VERSION "xyz"

NS_ :

BS_:

BU_: CabDisplay2 SafetyRestraintSystem AftertreatmentSystemGasOutlet AftertreatmentSystemGasIntake Turbocharger OnBoardDataLogger OffBoardDiagnosticTool2 OffBoardDiagnosticTool1 FileServer ParkingBrakeController SeatControl2 FanDriveController SteeringColumnUnit CommunicationUnitRadio CommunicationUnitSatellite CommunicationUnitCellular PropulsionBatteryCharger ChassisController2 ChassisController1 EngineValveControl AuxiliaryHeater2 AuxiliaryHeater1 ClutchUnit RampControl InformationSystem1 SuspensionSystemController2 OilSensor VehicleDynamicStability ExhaustEmissionController TransmissionDisplay2 TransmissionDisplay1 ClimateControl2 WaterPumpController RearAxleSteeringController LightingOperatorControl SeatController1 IgnitionController2 IgnitionController1 TirePressureController CabController2 CabController1 PneumaticSystemController SuspensionSystemController1 HydraulicPumpController EnduranceBrakingSystem RetarderExhaustEngine2 OnBoardDiagnosticUnit HeadwayController RetarderExhaustEngine1 CabDisplay1 ManagementComputer VirtualTerminal OffVehicleGateway PowerTakeOffFront HitchControl AuxiliaryValveControl BodyController TractorTrailerBridge1 StarterSystem ElectricalSystem VehicleSecurity VehicleNavigation AerodynamicControl ElectricalChargingSystem ClimateControl1 TripRecorder InstrumentCluster SuspensionDriveAxle2 SuspensionDriveAxle1 SuspensionSteerAxle SteeringController FuelSystem CruiseControl RetarderDriveline RetarderEngine BrakesDriveAxle2 BrakesDriveAxle1 BrakesSystemController BrakesSteerAxle AxleDrive2 AxleDrive1 AxleSteering PowerTakeOff ShiftConsoleSecondary ShiftConsolePrimary Transmission2 Transmission1 Engine2 Engine1

BO_ 2566781694 GTACE: 8 Vector__XXX
 SG_ GeneratorTotalKWHoursImport : 32|32@1+ (1,0) [0|4211081215] "kWh" Vector__XXX
 SG_ GeneratorTotalKWHoursExport : 0|32@1+ (1,0) [0|4211081215] "kWh" Vector__XXX

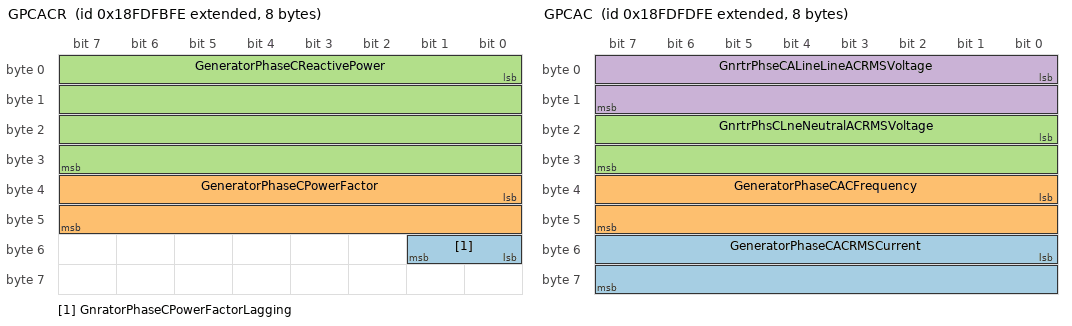
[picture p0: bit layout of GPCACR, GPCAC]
BO_ 2566781950 GPCACR: 8 Vector__XXX
 SG_ GnratorPhaseCPowerFactorLagging : 48|2@1+ (1,0) [0|3] "" Vector__XXX
 SG_ GeneratorPhaseCPowerFactor : 32|16@1+ (1,-1) [-1|2.92181] "" Vector__XXX
 SG_ GeneratorPhaseCReactivePower : 0|32@1+ (1,-2000000000) [-2000000000|2211081215] "VA" Vector__XXX

BO_ 2566782206 GPCACP: 8 Vector__XXX
 SG_ GeneratorPhaseCApparentPower : 32|32@1+ (1,-2000000000) [-2000000000|2211081215] "VA" Vector__XXX
 SG_ GeneratorPhaseCRealPower : 0|32@1+ (1,-2000000000) [-2000000000|2211081215] "VA" Vector__XXX

BO_ 2566782462 GPCAC: 8 Vector__XXX
 SG_ GeneratorPhaseCACRMSCurrent : 48|16@1+ (1,0) [0|64255] "A" Vector__XXX
 SG_ GeneratorPhaseCACFrequency : 32|16@1+ (1,0) [0|501.9921875] "Hz" Vector__XXX
 SG_ GnrtrPhsCLneNeutralACRMSVoltage : 16|16@1+ (1,0) [0|64255] "V" Vector__XXX
 SG_ GnrtrPhseCALineLineACRMSVoltage : 0|16@1+ (1,0) [0|64255] "V" Vector__XXX

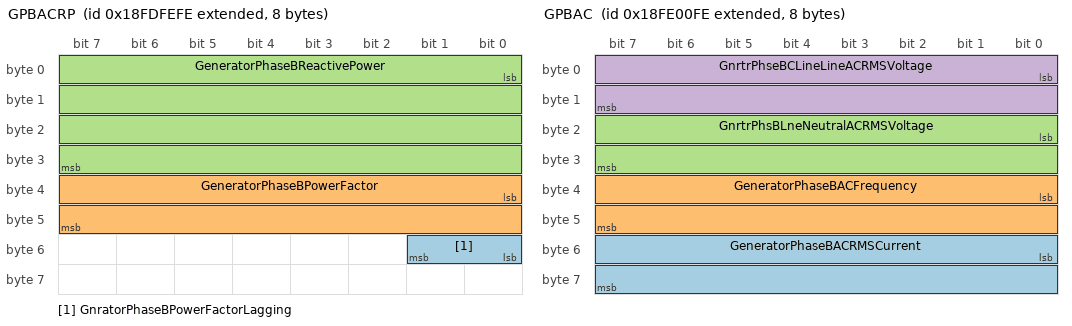
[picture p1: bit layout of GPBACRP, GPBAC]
BO_ 2566782718 GPBACRP: 8 Vector__XXX
 SG_ GnratorPhaseBPowerFactorLagging : 48|2@1+ (1,0) [0|3] "" Vector__XXX
 SG_ GeneratorPhaseBPowerFactor : 32|16@1+ (1,-1) [-1|2.92181] "" Vector__XXX
 SG_ GeneratorPhaseBReactivePower : 0|32@1+ (1,-2000000000) [-2000000000|2211081215] "VA" Vector__XXX

BO_ 2566782974 GPBACP: 8 Vector__XXX
 SG_ GeneratorPhaseBApparentPower : 32|32@1+ (1,-2000000000) [-2000000000|2211081215] "VA" Vector__XXX
 SG_ GeneratorPhaseBRealPower : 0|32@1+ (1,-2000000000) [-2000000000|2211081215] "VA" Vector__XXX

BO_ 2566783230 GPBAC: 8 Vector__XXX
 SG_ GeneratorPhaseBACRMSCurrent : 48|16@1+ (1,0) [0|64255] "A" Vector__XXX
 SG_ GeneratorPhaseBACFrequency : 32|16@1+ (1,0) [0|501.9921875] "Hz" Vector__XXX
 SG_ GnrtrPhsBLneNeutralACRMSVoltage : 16|16@1+ (1,0) [0|64255] "V" Vector__XXX
 SG_ GnrtrPhseBCLineLineACRMSVoltage : 0|16@1+ (1,0) [0|64255] "V" Vector__XXX

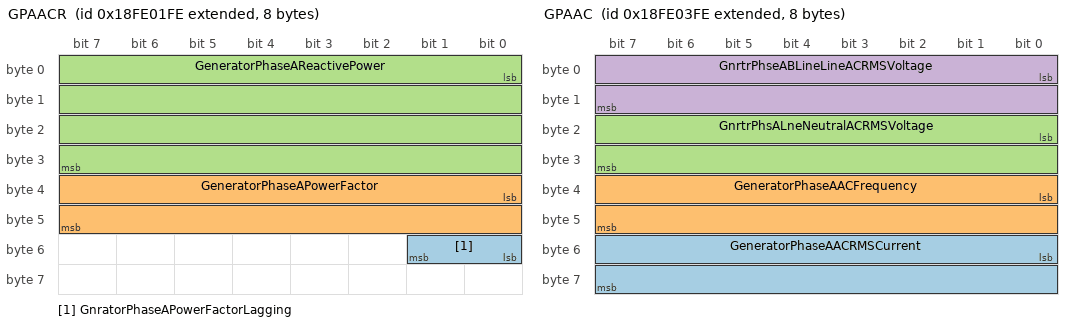
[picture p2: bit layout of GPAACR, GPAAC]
BO_ 2566783486 GPAACR: 8 Vector__XXX
 SG_ GnratorPhaseAPowerFactorLagging : 48|2@1+ (1,0) [0|3] "" Vector__XXX
 SG_ GeneratorPhaseAPowerFactor : 32|16@1+ (1,-1) [-1|2.92181] "" Vector__XXX
 SG_ GeneratorPhaseAReactivePower : 0|32@1+ (1,-2000000000) [-2000000000|2211081215] "VA" Vector__XXX

BO_ 2566783742 GPAACP: 8 Vector__XXX
 SG_ GeneratorPhaseAApparentPower : 32|32@1+ (1,-2000000000) [-2000000000|2211081215] "VA" Vector__XXX
 SG_ GeneratorPhaseARealPower : 0|32@1+ (1,-2000000000) [-2000000000|2211081215] "VA" Vector__XXX

BO_ 2566783998 GPAAC: 8 Vector__XXX
 SG_ GeneratorPhaseAACRMSCurrent : 48|16@1+ (1,0) [0|64255] "A" Vector__XXX
 SG_ GeneratorPhaseAACFrequency : 32|16@1+ (1,0) [0|501.9921875] "Hz" Vector__XXX
 SG_ GnrtrPhsALneNeutralACRMSVoltage : 16|16@1+ (1,0) [0|64255] "V" Vector__XXX
 SG_ GnrtrPhseABLineLineACRMSVoltage : 0|16@1+ (1,0) [0|64255] "V" Vector__XXX

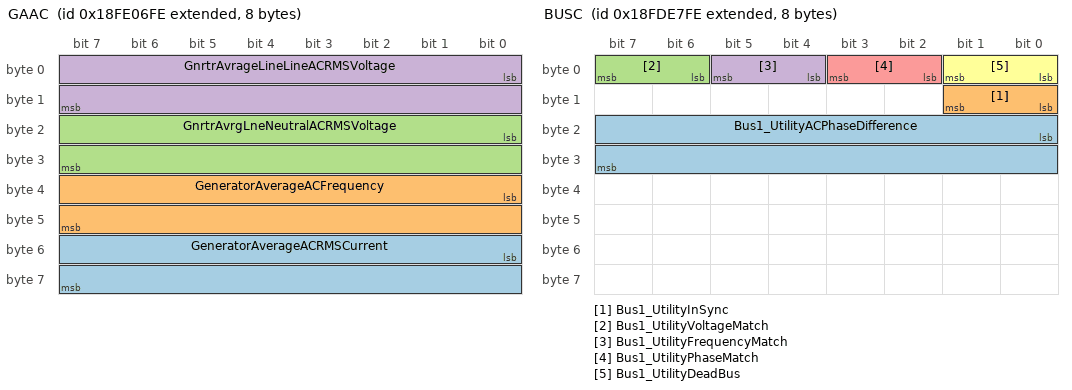
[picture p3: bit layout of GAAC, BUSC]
BO_ 2566784766 GAAC: 8 Vector__XXX
 SG_ GeneratorAverageACRMSCurrent : 48|16@1+ (1,0) [0|64255] "A" Vector__XXX
 SG_ GeneratorAverageACFrequency : 32|16@1+ (1,0) [0|501.9921875] "Hz" Vector__XXX
 SG_ GnrtrAvrgLneNeutralACRMSVoltage : 16|16@1+ (1,0) [0|64255] "V" Vector__XXX
 SG_ GnrtrAvrageLineLineACRMSVoltage : 0|16@1+ (1,0) [0|64255] "V" Vector__XXX

BO_ 2566776830 BUSC: 8 Vector__XXX
 SG_ Bus1_UtilityACPhaseDifference : 16|16@1+ (1,-200) [-200|301.99] "deg" Vector__XXX
 SG_ Bus1_UtilityInSync : 8|2@1+ (1,0) [0|3] "" Vector__XXX
 SG_ Bus1_UtilityVoltageMatch : 6|2@1+ (1,0) [0|3] "" Vector__XXX
 SG_ Bus1_UtilityFrequencyMatch : 4|2@1+ (1,0) [0|3] "" Vector__XXX
 SG_ Bus1_UtilityPhaseMatch : 2|2@1+ (1,0) [0|3] "" Vector__XXX
 SG_ Bus1_UtilityDeadBus : 0|2@1+ (1,0) [0|3] "" Vector__XXX

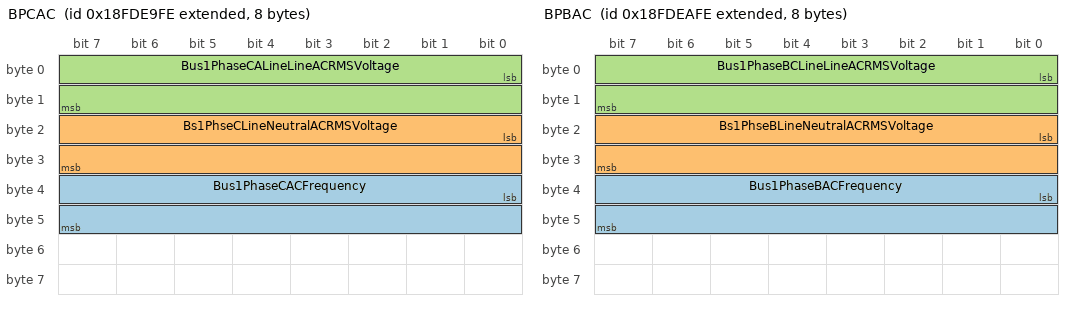
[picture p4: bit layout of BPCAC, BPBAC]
BO_ 2566777342 BPCAC: 8 Vector__XXX
 SG_ Bus1PhaseCACFrequency : 32|16@1+ (1,0) [0|501.9921875] "Hz" Vector__XXX
 SG_ Bs1PhseCLineNeutralACRMSVoltage : 16|16@1+ (1,0) [0|64255] "V" Vector__XXX
 SG_ Bus1PhaseCALineLineACRMSVoltage : 0|16@1+ (1,0) [0|64255] "V" Vector__XXX

BO_ 2566777598 BPBAC: 8 Vector__XXX
 SG_ Bus1PhaseBACFrequency : 32|16@1+ (1,0) [0|501.9921875] "Hz" Vector__XXX
 SG_ Bs1PhseBLineNeutralACRMSVoltage : 16|16@1+ (1,0) [0|64255] "V" Vector__XXX
 SG_ Bus1PhaseBCLineLineACRMSVoltage : 0|16@1+ (1,0) [0|64255] "V" Vector__XXX

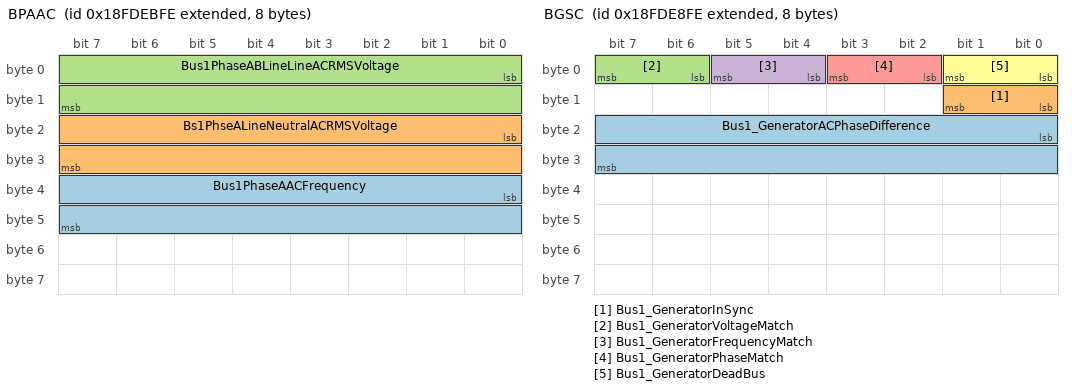
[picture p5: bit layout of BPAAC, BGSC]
BO_ 2566777854 BPAAC: 8 Vector__XXX
 SG_ Bus1PhaseAACFrequency : 32|16@1+ (1,0) [0|501.9921875] "Hz" Vector__XXX
 SG_ Bs1PhseALineNeutralACRMSVoltage : 16|16@1+ (1,0) [0|64255] "V" Vector__XXX
 SG_ Bus1PhaseABLineLineACRMSVoltage : 0|16@1+ (1,0) [0|64255] "V" Vector__XXX

BO_ 2566777086 BGSC: 8 Vector__XXX
 SG_ Bus1_GeneratorACPhaseDifference : 16|16@1+ (1,-200) [-200|301.99] "deg" Vector__XXX
 SG_ Bus1_GeneratorInSync : 8|2@1+ (1,0) [0|3] "" Vector__XXX
 SG_ Bus1_GeneratorVoltageMatch : 6|2@1+ (1,0) [0|3] "" Vector__XXX
 SG_ Bus1_GeneratorFrequencyMatch : 4|2@1+ (1,0) [0|3] "" Vector__XXX
 SG_ Bus1_GeneratorPhaseMatch : 2|2@1+ (1,0) [0|3] "" Vector__XXX
 SG_ Bus1_GeneratorDeadBus : 0|2@1+ (1,0) [0|3] "" Vector__XXX

BO_ 2566778110 BAAC: 8 Vector__XXX
 SG_ Bus1AverageACFrequency : 32|16@1+ (1,0) [0|501.9921875] "Hz" Vector__XXX
 SG_ Bs1AvrgeLineNeutralACRMSVoltage : 16|16@1+ (1,0) [0|64255] "V" Vector__XXX
 SG_ Bus1AverageLineLineACRMSVoltage : 0|16@1+ (1,0) [0|64255] "V" Vector__XXX

BO_ 2633895422 WSMSTR: 8 Vector__XXX
 SG_ NumberOfMembers : 0|8@1+ (1,0) [0|0] "" Vector__XXX

BO_ 2566838526 CA: 9 Vector__XXX
 SG_ ArbitraryAddressCapable : 63|1@1+ (1,0) [0|1] "" Vector__XXX
 SG_ IndustryGroup : 60|3@1+ (1,0) [0|7] "" Vector__XXX
 SG_ VehicleSystemInstance : 56|4@1+ (1,0) [0|15] "" Vector__XXX
 SG_ VehicleSystem : 49|7@1+ (1,0) [0|127] "" Vector__XXX
 SG_ Function : 40|8@1+ (1,0) [0|255] "" Vector__XXX
 SG_ FunctionInstance : 35|5@1+ (1,0) [0|31] "" Vector__XXX
 SG_ ECUInstance : 32|3@1+ (1,0) [0|7] "" Vector__XXX
 SG_ ManufacturerCode : 21|11@1+ (1,0) [0|2047] "" Vector__XXX
 SG_ IdentityNumber : 0|21@1+ (1,0) [0|2097152] "" Vector__XXX
 SG_ AddressAssignment : 64|8@1+ (1,0) [0|255] "" Vector__XXX

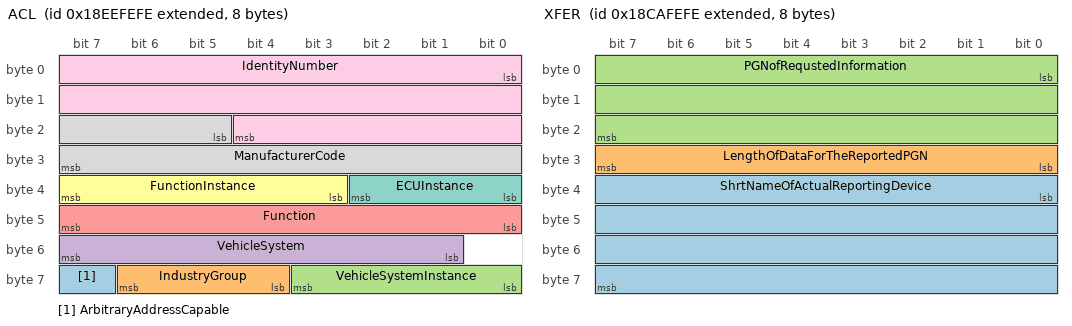
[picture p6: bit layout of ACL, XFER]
BO_ 2565799678 ACL: 8 Vector__XXX
 SG_ ArbitraryAddressCapable : 63|1@1+ (1,0) [0|1] "" Vector__XXX
 SG_ IndustryGroup : 60|3@1+ (1,0) [0|7] "" Vector__XXX
 SG_ VehicleSystemInstance : 56|4@1+ (1,0) [0|15] "" Vector__XXX
 SG_ VehicleSystem : 49|7@1+ (1,0) [0|127] "" Vector__XXX
 SG_ Function : 40|8@1+ (1,0) [0|255] "" Vector__XXX
 SG_ FunctionInstance : 35|5@1+ (1,0) [0|31] "" Vector__XXX
 SG_ ECUInstance : 32|3@1+ (1,0) [0|7] "" Vector__XXX
 SG_ ManufacturerCode : 21|11@1+ (1,0) [0|2047] "" Vector__XXX
 SG_ IdentityNumber : 0|21@1+ (1,0) [0|2097152] "" Vector__XXX

BO_ 2563440382 XFER: 8 Vector__XXX
 SG_ ShrtNameOfActualReportingDevice : 32|32@1+ (1,0) [0|0] "(2^32 - 1)" Vector__XXX
 SG_ LengthOfDataForTheReportedPGN : 24|8@1+ (1,0) [0|255] "" Vector__XXX
 SG_ PGNofRequstedInformation : 0|24@1+ (1,0) [0|16777215] "" Vector__XXX

BO_ 2565603070 TPDT: 8 Vector__XXX
 SG_ SequenceNumber : 0|8@1+ (1,0) [0|252] "" Vector__XXX

BO_ 2565668606 TPCM: 8 Vector__XXX
 SG_ TotalNumberOfPacketsEoMA m19 : 24|8@1+ (1,0) [0|255] "" Vector__XXX
 SG_ TotalMessageSizeEoMA m19 : 8|16@1+ (1,0) [0|64255] "counts" Vector__XXX
 SG_ TotalMessageSizeBAM m32 : 8|16@1+ (1,0) [0|64255] "counts" Vector__XXX
 SG_ TotalNumberOfPacketsBAM m32 : 24|8@1+ (1,0) [0|255] "" Vector__XXX
 SG_ ConnectionAbortReason m255 : 8|8@1+ (1,0) [0|255] "" Vector__XXX
 SG_ NextPacketNumberToBeSent m17 : 16|8@1+ (1,0) [0|255] "" Vector__XXX
 SG_ NumberOfPacketsThatCanBeSent m17 : 8|8@1+ (1,0) [0|255] "" Vector__XXX
 SG_ PGNumber : 40|24@1+ (1,0) [0|16777200] "" Vector__XXX
 SG_ MaximumNumberOfPackets m16 : 32|8@1+ (1,0) [0|255] "" Vector__XXX
 SG_ TotalNumberOfPackets m16 : 24|8@1+ (1,0) [0|255] "" Vector__XXX
 SG_ TotalMessageSize m16 : 8|16@1+ (1,0) [0|64255] "counts" Vector__XXX
 SG_ ControlByte M : 0|8@1+ (1,0) [0|255] "" Vector__XXX

BO_ 2563374846 RQST2: 8 Vector__XXX
 SG_ UseTransferMode : 24|2@1+ (1,0) [0|3] "" Vector__XXX
 SG_ ParameterGroupNumber : 0|24@1+ (1,0) [0|16777215] "" Vector__XXX

BO_ 2565537534 RQST: 3 Vector__XXX
 SG_ ParameterGroupNumber : 0|24@1+ (1,0) [0|16777215] "" Vector__XXX

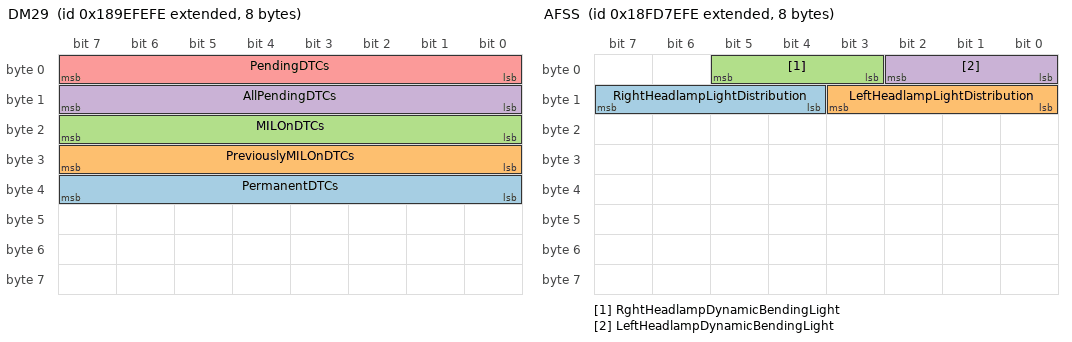
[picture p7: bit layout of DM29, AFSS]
BO_ 2560556798 DM29: 8 Vector__XXX
 SG_ PermanentDTCs : 32|8@1+ (1,0) [0|255] "" Vector__XXX
 SG_ PreviouslyMILOnDTCs : 24|8@1+ (1,0) [0|255] "" Vector__XXX
 SG_ MILOnDTCs : 16|8@1+ (1,0) [0|255] "" Vector__XXX
 SG_ AllPendingDTCs : 8|8@1+ (1,0) [0|255] "" Vector__XXX
 SG_ PendingDTCs : 0|8@1+ (1,0) [0|255] "" Vector__XXX

BO_ 2566750462 DM28: 22 Vector__XXX
 SG_ SPN5 : 144|16@1+ (1,0) [0|65536] "" Vector__XXX
 SG_ SPN4 : 112|16@1+ (1,0) [0|65536] "" Vector__XXX
 SG_ SPN3 : 80|16@1+ (1,0) [0|65536] "" Vector__XXX
 SG_ SPN2 : 48|16@1+ (1,0) [0|65536] "" Vector__XXX
 SG_ FailureModeIdentifier5 : 160|5@1+ (1,0) [0|0] "" Vector__XXX
 SG_ FailureModeIdentifier4 : 128|5@1+ (1,0) [0|0] "" Vector__XXX
 SG_ FailureModeIdentifier3 : 96|5@1+ (1,0) [0|0] "" Vector__XXX
 SG_ FlashRedStopLamp : 12|2@1+ (1,0) [0|3] "" Vector__XXX
 SG_ FlashProtectLamp : 8|2@1+ (1,0) [0|3] "" Vector__XXX
 SG_ FlashMalfuncIndicatorLamp : 14|2@1+ (1,0) [0|3] "" Vector__XXX
 SG_ FlashAmberWarningLamp : 10|2@1+ (1,0) [0|3] "" Vector__XXX
 SG_ MalfunctionIndicatorLampStatus : 6|2@1+ (1,0) [0|3] "" Vector__XXX
 SG_ AmberWarningLampStatus : 2|2@1+ (1,0) [0|3] "" Vector__XXX
 SG_ OccurenceCount1 : 40|7@1+ (1,0) [0|126] "" Vector__XXX
 SG_ SPNConversionMethod1 : 47|1@1+ (1,0) [0|1] "" Vector__XXX
 SG_ FailureModeIdentifier1 : 32|5@1+ (1,0) [0|0] "" Vector__XXX
 SG_ SPN1 : 16|16@1+ (1,0) [0|65536] "" Vector__XXX
 SG_ RedStopLampState : 4|2@1+ (1,0) [0|3] "" Vector__XXX
 SG_ ProtectLampStatus : 0|2@1+ (1,0) [0|3] "" Vector__XXX
 SG_ FailureModeIdentifier2 : 64|5@1+ (1,0) [0|0] "" Vector__XXX
 SG_ SPNConversionMethod5 : 175|1@1+ (1,0) [0|1] "" Vector__XXX
 SG_ SPNConversionMethod4 : 143|1@1+ (1,0) [0|1] "" Vector__XXX
 SG_ SPNConversionMethod3 : 111|1@1+ (1,0) [0|1] "" Vector__XXX
 SG_ SPNConversionMethod2 : 79|1@1+ (1,0) [0|1] "" Vector__XXX
 SG_ OccurenceCount5 : 168|7@1+ (1,0) [0|126] "" Vector__XXX
 SG_ OccurenceCount4 : 136|7@1+ (1,0) [0|126] "" Vector__XXX
 SG_ OccurenceCount3 : 104|7@1+ (1,0) [0|126] "" Vector__XXX
 SG_ OccurenceCount2 : 72|7@1+ (1,0) [0|126] "" Vector__XXX
 SG_ SPN5High : 165|3@1+ (1,0) [0|7] "" Vector__XXX
 SG_ SPN4High : 133|3@1+ (1,0) [0|7] "" Vector__XXX
 SG_ SPN3High : 101|3@1+ (1,0) [0|7] "" Vector__XXX
 SG_ SPN2High : 69|3@1+ (1,0) [0|7] "" Vector__XXX
 SG_ SPN1High : 37|3@1+ (1,0) [0|7] "" Vector__XXX

BO_ 2566750974 DM27: 22 Vector__XXX
 SG_ SPN5 : 144|16@1+ (1,0) [0|65536] "" Vector__XXX
 SG_ SPN4 : 112|16@1+ (1,0) [0|65536] "" Vector__XXX
 SG_ SPN3 : 80|16@1+ (1,0) [0|65536] "" Vector__XXX
 SG_ SPN2 : 48|16@1+ (1,0) [0|65536] "" Vector__XXX
 SG_ FailureModeIdentifier5 : 160|5@1+ (1,0) [0|0] "" Vector__XXX
 SG_ FailureModeIdentifier4 : 128|5@1+ (1,0) [0|0] "" Vector__XXX
 SG_ FailureModeIdentifier3 : 96|5@1+ (1,0) [0|0] "" Vector__XXX
 SG_ FlashRedStopLamp : 12|2@1+ (1,0) [0|3] "" Vector__XXX
 SG_ FlashProtectLamp : 8|2@1+ (1,0) [0|3] "" Vector__XXX
 SG_ FlashMalfuncIndicatorLamp : 14|2@1+ (1,0) [0|3] "" Vector__XXX
 SG_ FlashAmberWarningLamp : 10|2@1+ (1,0) [0|3] "" Vector__XXX
 SG_ MalfunctionIndicatorLampStatus : 6|2@1+ (1,0) [0|3] "" Vector__XXX
 SG_ AmberWarningLampStatus : 2|2@1+ (1,0) [0|3] "" Vector__XXX
 SG_ OccurenceCount1 : 40|7@1+ (1,0) [0|126] "" Vector__XXX
 SG_ SPNConversionMethod1 : 47|1@1+ (1,0) [0|1] "" Vector__XXX
 SG_ FailureModeIdentifier1 : 32|5@1+ (1,0) [0|0] "" Vector__XXX
 SG_ SPN1 : 16|16@1+ (1,0) [0|65536] "" Vector__XXX
 SG_ RedStopLampState : 4|2@1+ (1,0) [0|3] "" Vector__XXX
 SG_ ProtectLampStatus : 0|2@1+ (1,0) [0|3] "" Vector__XXX
 SG_ FailureModeIdentifier2 : 64|5@1+ (1,0) [0|0] "" Vector__XXX
 SG_ SPNConversionMethod5 : 175|1@1+ (1,0) [0|1] "" Vector__XXX
 SG_ SPNConversionMethod4 : 143|1@1+ (1,0) [0|1] "" Vector__XXX
 SG_ SPNConversionMethod3 : 111|1@1+ (1,0) [0|1] "" Vector__XXX
 SG_ SPNConversionMethod2 : 79|1@1+ (1,0) [0|1] "" Vector__XXX
 SG_ OccurenceCount5 : 168|7@1+ (1,0) [0|126] "" Vector__XXX
 SG_ OccurenceCount4 : 136|7@1+ (1,0) [0|126] "" Vector__XXX
 SG_ OccurenceCount3 : 104|7@1+ (1,0) [0|126] "" Vector__XXX
 SG_ OccurenceCount2 : 72|7@1+ (1,0) [0|126] "" Vector__XXX
 SG_ SPN5High : 165|3@1+ (1,0) [0|7] "" Vector__XXX
 SG_ SPN4High : 133|3@1+ (1,0) [0|7] "" Vector__XXX
 SG_ SPN3High : 101|3@1+ (1,0) [0|7] "" Vector__XXX
 SG_ SPN2High : 69|3@1+ (1,0) [0|7] "" Vector__XXX
 SG_ SPN1High : 37|3@1+ (1,0) [0|7] "" Vector__XXX

BO_ 2566748414 ATI2: 32 Vector__XXX
 SG_ Aftrtrtmnt2TrpPssvRgnrationTime : 128|32@1+ (1,0) [0|4211081215] "s" Vector__XXX
 SG_ Aftrtrtmnt2TrpNmbrOfPssvRgnrtns : 160|32@1+ (1,0) [0|4294967295] "counts" Vector__XXX
 SG_ Aftrtrtmnt2TrpNmbrOfActvRgnrtns : 96|32@1+ (1,0) [0|4294967295] "counts" Vector__XXX
 SG_ Aftrtrtmnt2TrpNmbrOfActvRgnrtnMn : 224|32@1+ (1,0) [0|4294967295] "counts" Vector__XXX
 SG_ Aftrtrtmnt2TrpNmbrOfActvRgnrtnIn : 192|32@1+ (1,0) [0|4294967295] "counts" Vector__XXX
 SG_ Aftrtrtmnt2TrpActvRgnrationTime : 32|32@1+ (1,0) [0|4211081215] "s" Vector__XXX
 SG_ Aftertreatment2TripFuelUsed : 0|32@1+ (0.5,0) [0|2105540607.5] "L" Vector__XXX
 SG_ Aftertreatment2TripDisabledTime : 64|32@1+ (1,0) [0|4211081215] "s" Vector__XXX

BO_ 2566748670 ATI1: 32 Vector__XXX
 SG_ Aftrtrtmnt1TrpPssvRgnrationTime : 128|32@1+ (1,0) [0|4211081215] "s" Vector__XXX
 SG_ Aftrtrtmnt1TrpNmbrOfPssvRgnrtns : 160|32@1+ (1,0) [0|4294967295] "counts" Vector__XXX
 SG_ Aftrtrtmnt1TrpNmbrOfActvRgnrtns : 96|32@1+ (1,0) [0|4294967295] "counts" Vector__XXX
 SG_ Aftrtrtmnt1TrpNmbrOfActvRgnrtnMn : 224|32@1+ (1,0) [0|4294967295] "counts" Vector__XXX
 SG_ Aftrtrtmnt1TrpNmbrOfActvRgnrtnIn : 192|32@1+ (1,0) [0|4294967295] "counts" Vector__XXX
 SG_ Aftrtrtmnt1TrpActvRgnrationTime : 32|32@1+ (1,0) [0|4211081215] "s" Vector__XXX
 SG_ Aftertreatment1TripFuelUsed : 0|32@1+ (0.5,0) [0|2105540607.5] "L" Vector__XXX
 SG_ Aftertreatment1TripDisabledTime : 64|32@1+ (1,0) [0|4211081215] "s" Vector__XXX

BO_ 2566745598 AAC3: 8 Vector__XXX
 SG_ Aftertreatment1SecondAirPress : 48|16@1+ (0.1,0) [0|6425.5] "kPa" Vector__XXX
 SG_ Aftrtreatment1SecondAirMassFlow : 32|16@1+ (0.2,0) [0|12851] "kg/h" Vector__XXX
 SG_ Aftertreatment1SecondAirTemp : 16|16@1+ (0.03125,-273) [-273|1735] "deg" Vector__XXX
 SG_ Aftrtratment1SecondAirDiffPress : 0|16@1+ (0.0078125,-250) [-250|251.99] "kPa" Vector__XXX

BO_ 2566745342 AAC4: 8 Vector__XXX
 SG_ Aftertreatment2SecondAirPress : 48|16@1+ (0.1,0) [0|6425.5] "kPa" Vector__XXX
 SG_ Aftrtreatment2SecondAirMassFlow : 32|16@1+ (0.2,0) [0|12851] "kg/h" Vector__XXX
 SG_ Aftertreatment2SecondAirTemp : 16|16@1+ (0.03125,-273) [-273|1735] "deg" Vector__XXX
 SG_ Aftrtratment2SecondAirDiffPress : 0|16@1+ (0.0078125,-250) [-250|251.99] "kPa" Vector__XXX

BO_ 2566754558 AETC: 8 Vector__XXX
 SG_ NumberOfAETCDataPoints : 4|4@1+ (1,0) [0|15] "" Vector__XXX
 SG_ AETCDataCollectionStandard : 0|4@1+ (1,0) [0|15] "" Vector__XXX

BO_ 2566749950 AFSS: 8 Vector__XXX
 SG_ RightHeadlampLightDistribution : 12|4@1+ (1,0) [0|15] "" Vector__XXX
 SG_ LeftHeadlampLightDistribution : 8|4@1+ (1,0) [0|15] "" Vector__XXX
 SG_ RghtHeadlampDynamicBendingLight : 3|3@1+ (1,0) [0|7] "" Vector__XXX
 SG_ LeftHeadlampDynamicBendingLight : 0|3@1+ (1,0) [0|7] "" Vector__XXX

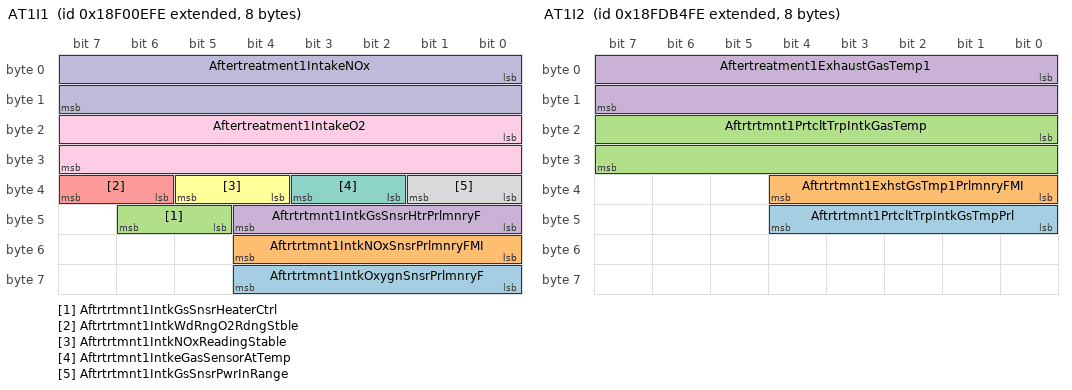
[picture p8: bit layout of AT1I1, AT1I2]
BO_ 2565869310 AT1I1: 8 Vector__XXX
 SG_ Aftrtrtmnt1IntkOxygnSnsrPrlmnryF : 56|5@1+ (1,0) [0|31] "" Vector__XXX
 SG_ Aftrtrtmnt1IntkNOxSnsrPrlmnryFMI : 48|5@1+ (1,0) [0|31] "" Vector__XXX
 SG_ Aftrtrtmnt1IntkGsSnsrHeaterCtrl : 45|2@1+ (1,0) [0|3] "" Vector__XXX
 SG_ Aftrtrtmnt1IntkGsSnsrHtrPrlmnryF : 40|5@1+ (1,0) [0|31] "" Vector__XXX
 SG_ Aftrtrtmnt1IntkWdRngO2RdngStble : 38|2@1+ (1,0) [0|3] "" Vector__XXX
 SG_ Aftrtrtmnt1IntkNOxReadingStable : 36|2@1+ (1,0) [0|3] "" Vector__XXX
 SG_ Aftrtrtmnt1IntkeGasSensorAtTemp : 34|2@1+ (1,0) [0|3] "" Vector__XXX
 SG_ Aftrtrtmnt1IntkGsSnsrPwrInRange : 32|2@1+ (1,0) [0|3] "" Vector__XXX
 SG_ Aftertreatment1IntakeO2 : 16|16@1+ (0.000514,-12) [-12|21] "%" Vector__XXX
 SG_ Aftertreatment1IntakeNOx : 0|16@1+ (0.05,-200) [-200|3012.75] "ppm" Vector__XXX

BO_ 2566763774 AT1I2: 8 Vector__XXX
 SG_ Aftrtrtmnt1PrtcltTrpIntkGsTmpPrl : 40|5@1+ (1,0) [0|31] "" Vector__XXX
 SG_ Aftrtrtmnt1ExhstGsTmp1PrlmnryFMI : 32|5@1+ (1,0) [0|31] "" Vector__XXX
 SG_ Aftrtrtmnt1PrtcltTrpIntkGasTemp : 16|16@1+ (0.03125,-273) [-273|1735] "deg" Vector__XXX
 SG_ Aftertreatment1ExhaustGasTemp1 : 0|16@1+ (0.03125,-273) [-273|1735] "deg" Vector__XXX

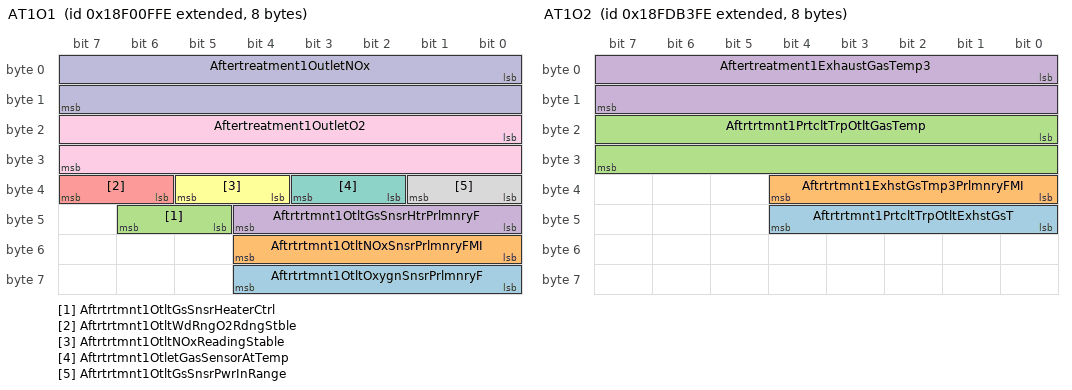
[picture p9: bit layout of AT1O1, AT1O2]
BO_ 2565869566 AT1O1: 8 Vector__XXX
 SG_ Aftrtrtmnt1OtltOxygnSnsrPrlmnryF : 56|5@1+ (1,0) [0|31] "" Vector__XXX
 SG_ Aftrtrtmnt1OtltNOxSnsrPrlmnryFMI : 48|5@1+ (1,0) [0|31] "" Vector__XXX
 SG_ Aftrtrtmnt1OtltGsSnsrHeaterCtrl : 45|2@1+ (1,0) [0|3] "" Vector__XXX
 SG_ Aftrtrtmnt1OtltGsSnsrHtrPrlmnryF : 40|5@1+ (1,0) [0|31] "" Vector__XXX
 SG_ Aftrtrtmnt1OtltWdRngO2RdngStble : 38|2@1+ (1,0) [0|3] "" Vector__XXX
 SG_ Aftrtrtmnt1OtltNOxReadingStable : 36|2@1+ (1,0) [0|3] "" Vector__XXX
 SG_ Aftrtrtmnt1OtletGasSensorAtTemp : 34|2@1+ (1,0) [0|3] "" Vector__XXX
 SG_ Aftrtrtmnt1OtltGsSnsrPwrInRange : 32|2@1+ (1,0) [0|3] "" Vector__XXX
 SG_ Aftertreatment1OutletO2 : 16|16@1+ (0.000514,-12) [-12|21] "%" Vector__XXX
 SG_ Aftertreatment1OutletNOx : 0|16@1+ (0.05,-200) [-200|3012.75] "ppm" Vector__XXX

BO_ 2566763518 AT1O2: 8 Vector__XXX
 SG_ Aftrtrtmnt1PrtcltTrpOtltExhstGsT : 40|5@1+ (1,0) [0|31] "" Vector__XXX
 SG_ Aftrtrtmnt1ExhstGsTmp3PrlmnryFMI : 32|5@1+ (1,0) [0|31] "" Vector__XXX
 SG_ Aftrtrtmnt1PrtcltTrpOtltGasTemp : 16|16@1+ (0.03125,-273) [-273|1735] "deg" Vector__XXX
 SG_ Aftertreatment1ExhaustGasTemp3 : 0|16@1+ (0.03125,-273) [-273|1735] "deg" Vector__XXX

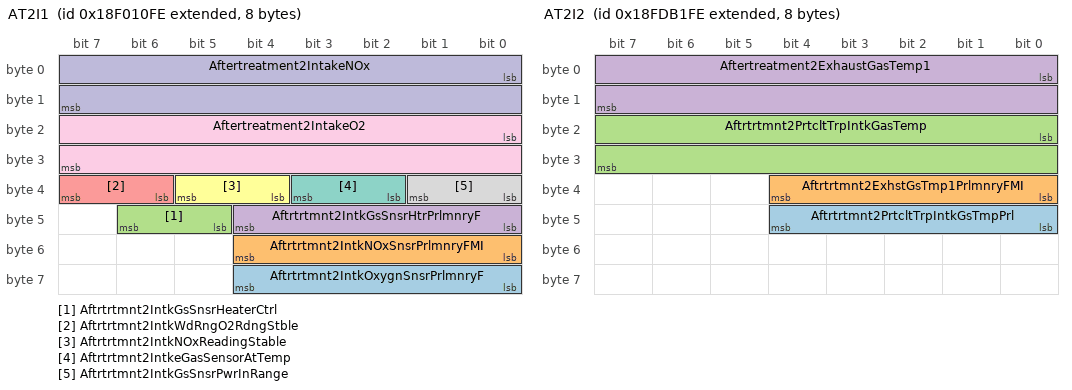
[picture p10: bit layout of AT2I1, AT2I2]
BO_ 2565869822 AT2I1: 8 Vector__XXX
 SG_ Aftrtrtmnt2IntkOxygnSnsrPrlmnryF : 56|5@1+ (1,0) [0|31] "" Vector__XXX
 SG_ Aftrtrtmnt2IntkNOxSnsrPrlmnryFMI : 48|5@1+ (1,0) [0|31] "" Vector__XXX
 SG_ Aftrtrtmnt2IntkGsSnsrHeaterCtrl : 45|2@1+ (1,0) [0|3] "" Vector__XXX
 SG_ Aftrtrtmnt2IntkGsSnsrHtrPrlmnryF : 40|5@1+ (1,0) [0|31] "" Vector__XXX
 SG_ Aftrtrtmnt2IntkWdRngO2RdngStble : 38|2@1+ (1,0) [0|3] "" Vector__XXX
 SG_ Aftrtrtmnt2IntkNOxReadingStable : 36|2@1+ (1,0) [0|3] "" Vector__XXX
 SG_ Aftrtrtmnt2IntkeGasSensorAtTemp : 34|2@1+ (1,0) [0|3] "" Vector__XXX
 SG_ Aftrtrtmnt2IntkGsSnsrPwrInRange : 32|2@1+ (1,0) [0|3] "" Vector__XXX
 SG_ Aftertreatment2IntakeO2 : 16|16@1+ (0.000514,-12) [-12|21] "%" Vector__XXX
 SG_ Aftertreatment2IntakeNOx : 0|16@1+ (0.05,-200) [-200|3012.75] "ppm" Vector__XXX

BO_ 2566763006 AT2I2: 8 Vector__XXX
 SG_ Aftrtrtmnt2PrtcltTrpIntkGsTmpPrl : 40|5@1+ (1,0) [0|31] "" Vector__XXX
 SG_ Aftrtrtmnt2ExhstGsTmp1PrlmnryFMI : 32|5@1+ (1,0) [0|31] "" Vector__XXX
 SG_ Aftrtrtmnt2PrtcltTrpIntkGasTemp : 16|16@1+ (0.03125,-273) [-273|1735] "deg" Vector__XXX
 SG_ Aftertreatment2ExhaustGasTemp1 : 0|16@1+ (0.03125,-273) [-273|1735] "deg" Vector__XXX

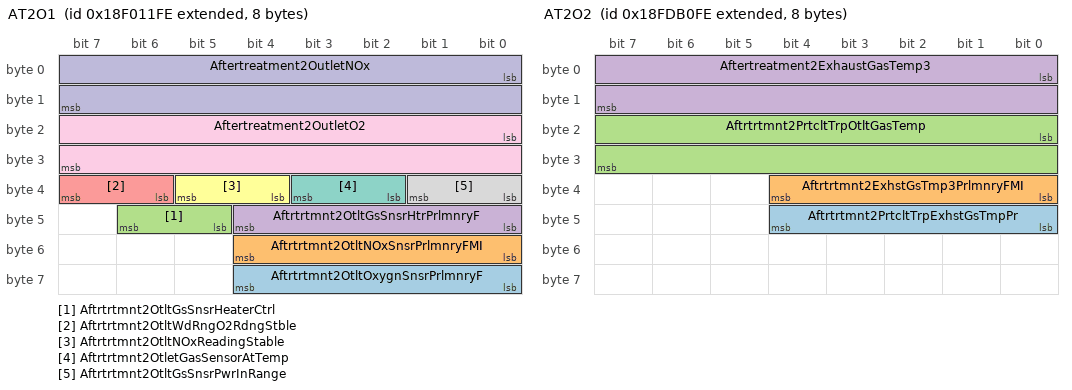
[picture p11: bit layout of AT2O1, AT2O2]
BO_ 2565870078 AT2O1: 8 Vector__XXX
 SG_ Aftrtrtmnt2OtltOxygnSnsrPrlmnryF : 56|5@1+ (1,0) [0|31] "" Vector__XXX
 SG_ Aftrtrtmnt2OtltNOxSnsrPrlmnryFMI : 48|5@1+ (1,0) [0|31] "" Vector__XXX
 SG_ Aftrtrtmnt2OtltGsSnsrHeaterCtrl : 45|2@1+ (1,0) [0|3] "" Vector__XXX
 SG_ Aftrtrtmnt2OtltGsSnsrHtrPrlmnryF : 40|5@1+ (1,0) [0|31] "" Vector__XXX
 SG_ Aftrtrtmnt2OtltWdRngO2RdngStble : 38|2@1+ (1,0) [0|3] "" Vector__XXX
 SG_ Aftrtrtmnt2OtltNOxReadingStable : 36|2@1+ (1,0) [0|3] "" Vector__XXX
 SG_ Aftrtrtmnt2OtletGasSensorAtTemp : 34|2@1+ (1,0) [0|3] "" Vector__XXX
 SG_ Aftrtrtmnt2OtltGsSnsrPwrInRange : 32|2@1+ (1,0) [0|3] "" Vector__XXX
 SG_ Aftertreatment2OutletO2 : 16|16@1+ (0.000514,-12) [-12|21] "%" Vector__XXX
 SG_ Aftertreatment2OutletNOx : 0|16@1+ (0.05,-200) [-200|3012.75] "ppm" Vector__XXX

BO_ 2566762750 AT2O2: 8 Vector__XXX
 SG_ Aftrtrtmnt2PrtcltTrpExhstGsTmpPr : 40|5@1+ (1,0) [0|31] "" Vector__XXX
 SG_ Aftrtrtmnt2ExhstGsTmp3PrlmnryFMI : 32|5@1+ (1,0) [0|31] "" Vector__XXX
 SG_ Aftrtrtmnt2PrtcltTrpOtltGasTemp : 16|16@1+ (0.03125,-273) [-273|1735] "deg" Vector__XXX
 SG_ Aftertreatment2ExhaustGasTemp3 : 0|16@1+ (0.03125,-273) [-273|1735] "deg" Vector__XXX

BO_ 2566753534 ATGP1: 8 Vector__XXX
 SG_ ParticulateTrapOutletPress1 : 16|16@1+ (0.1,0) [0|6425.5] "kPa" Vector__XXX
 SG_ ParticulateTrapIntakePress1 : 0|16@1+ (0.1,0) [0|6425.5] "kPa" Vector__XXX

BO_ 2566753278 ATGP2: 8 Vector__XXX
 SG_ ParticulateTrapOutletPress2 : 16|16@1+ (0.1,0) [0|6425.5] "kPa" Vector__XXX
 SG_ ParticulateTrapIntakePress2 : 0|16@1+ (0.1,0) [0|6425.5] "kPa" Vector__XXX

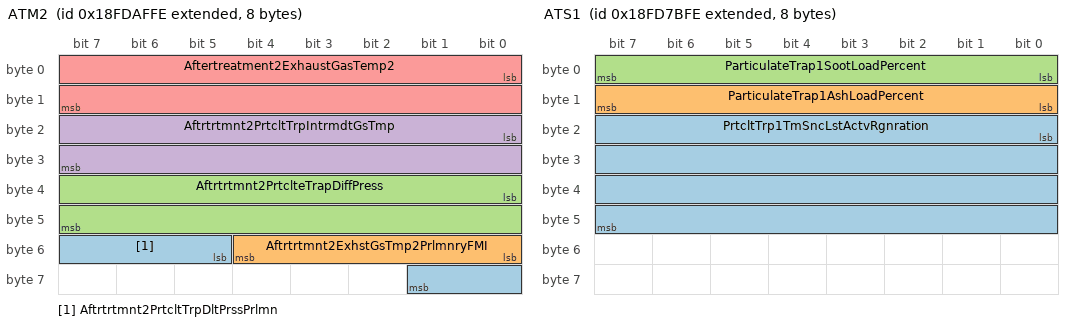
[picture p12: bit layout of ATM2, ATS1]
BO_ 2566762494 ATM2: 8 Vector__XXX
 SG_ Aftrtrtmnt2PrtcltTrpDltPrssPrlmn : 53|5@1+ (1,0) [0|31] "" Vector__XXX
 SG_ Aftrtrtmnt2ExhstGsTmp2PrlmnryFMI : 48|5@1+ (1,0) [0|31] "" Vector__XXX
 SG_ Aftrtrtmnt2PrtclteTrapDiffPress : 32|16@1+ (0.1,0) [0|6425.5] "kPa" Vector__XXX
 SG_ Aftrtrtmnt2PrtcltTrpIntrmdtGsTmp : 16|16@1+ (0.03125,-273) [-273|1735] "deg" Vector__XXX
 SG_ Aftertreatment2ExhaustGasTemp2 : 0|16@1+ (0.03125,-273) [-273|1735] "deg" Vector__XXX

BO_ 2566749182 ATS1: 8 Vector__XXX
 SG_ PrtcltTrp1TmSncLstActvRgnration : 16|32@1+ (1,0) [0|4211081215] "s" Vector__XXX
 SG_ ParticulateTrap1AshLoadPercent : 8|8@1+ (1,0) [0|250] "%" Vector__XXX
 SG_ ParticulateTrap1SootLoadPercent : 0|8@1+ (1,0) [0|250] "%" Vector__XXX

BO_ 2566748926 ATS2: 8 Vector__XXX
 SG_ PrtcltTrp2TmSncLstActvRgnration : 16|32@1+ (1,0) [0|4211081215] "s" Vector__XXX
 SG_ ParticulateTrap2AshLoadPercent : 8|8@1+ (1,0) [0|250] "%" Vector__XXX
 SG_ ParticulateTrap2SootLoadPercent : 0|8@1+ (1,0) [0|250] "%" Vector__XXX

BO_ 2566838782 AUXIO1: 8 Vector__XXX
 SG_ AuxI_OChannel2 : 48|16@1+ (1,0) [0|64255] "counts" Vector__XXX
 SG_ AuxI_OChannel1 : 32|16@1+ (1,0) [0|64255] "counts" Vector__XXX

BO_ 2561146622 AUXIO2: 8 Vector__XXX
 SG_ AuxI_O45 : 62|2@1+ (1,0) [0|3] "" Vector__XXX
 SG_ AuxI_O46 : 60|2@1+ (1,0) [0|3] "" Vector__XXX
 SG_ AuxI_O47 : 58|2@1+ (1,0) [0|3] "" Vector__XXX
 SG_ AuxI_O48 : 56|2@1+ (1,0) [0|3] "" Vector__XXX
 SG_ AuxI_O41 : 54|2@1+ (1,0) [0|3] "" Vector__XXX
 SG_ AuxI_O42 : 52|2@1+ (1,0) [0|3] "" Vector__XXX
 SG_ AuxI_O43 : 50|2@1+ (1,0) [0|3] "" Vector__XXX
 SG_ AuxI_O44 : 48|2@1+ (1,0) [0|3] "" Vector__XXX
 SG_ AuxI_O37 : 46|2@1+ (1,0) [0|3] "" Vector__XXX
 SG_ AuxI_O38 : 44|2@1+ (1,0) [0|3] "" Vector__XXX
 SG_ AuxI_O39 : 42|2@1+ (1,0) [0|3] "" Vector__XXX
 SG_ AuxI_O40 : 40|2@1+ (1,0) [0|3] "" Vector__XXX
 SG_ AuxI_O33 : 38|2@1+ (1,0) [0|3] "" Vector__XXX
 SG_ AuxI_O34 : 36|2@1+ (1,0) [0|3] "" Vector__XXX
 SG_ AuxI_O35 : 34|2@1+ (1,0) [0|3] "" Vector__XXX
 SG_ AuxI_O36 : 32|2@1+ (1,0) [0|3] "" Vector__XXX
 SG_ AuxI_O29 : 30|2@1+ (1,0) [0|3] "" Vector__XXX
 SG_ AuxI_O30 : 28|2@1+ (1,0) [0|3] "" Vector__XXX
 SG_ AuxI_O31 : 26|2@1+ (1,0) [0|3] "" Vector__XXX
 SG_ AuxI_O32 : 24|2@1+ (1,0) [0|3] "" Vector__XXX
 SG_ AuxI_O25 : 22|2@1+ (1,0) [0|3] "" Vector__XXX
 SG_ AuxI_O26 : 20|2@1+ (1,0) [0|3] "" Vector__XXX
 SG_ AuxI_O27 : 18|2@1+ (1,0) [0|3] "" Vector__XXX
 SG_ AuxI_O28 : 16|2@1+ (1,0) [0|3] "" Vector__XXX
 SG_ AuxI_O21 : 14|2@1+ (1,0) [0|3] "" Vector__XXX
 SG_ AuxI_O22 : 12|2@1+ (1,0) [0|3] "" Vector__XXX
 SG_ AuxI_O23 : 10|2@1+ (1,0) [0|3] "" Vector__XXX
 SG_ AuxI_O24 : 8|2@1+ (1,0) [0|3] "" Vector__XXX
 SG_ AuxI_O17 : 6|2@1+ (1,0) [0|3] "" Vector__XXX
 SG_ AuxI_O18 : 4|2@1+ (1,0) [0|3] "" Vector__XXX
 SG_ AuxI_O19 : 2|2@1+ (1,0) [0|3] "" Vector__XXX
 SG_ AuxI_O20 : 0|2@1+ (1,0) [0|3] "" Vector__XXX

BO_ 2561081086 AUXIO3: 8 Vector__XXX
 SG_ AuxI_O77 : 62|2@1+ (1,0) [0|3] "" Vector__XXX
 SG_ AuxI_O78 : 60|2@1+ (1,0) [0|3] "" Vector__XXX
 SG_ AuxI_O79 : 58|2@1+ (1,0) [0|3] "" Vector__XXX
 SG_ AuxI_O80 : 56|2@1+ (1,0) [0|3] "" Vector__XXX
 SG_ AuxI_O73 : 54|2@1+ (1,0) [0|3] "" Vector__XXX
 SG_ AuxI_O74 : 52|2@1+ (1,0) [0|3] "" Vector__XXX
 SG_ AuxI_O75 : 50|2@1+ (1,0) [0|3] "" Vector__XXX
 SG_ AuxI_O76 : 48|2@1+ (1,0) [0|3] "" Vector__XXX
 SG_ AuxI_O69 : 46|2@1+ (1,0) [0|3] "" Vector__XXX
 SG_ AuxI_O70 : 44|2@1+ (1,0) [0|3] "" Vector__XXX
 SG_ AuxI_O71 : 42|2@1+ (1,0) [0|3] "" Vector__XXX
 SG_ AuxI_O72 : 40|2@1+ (1,0) [0|3] "" Vector__XXX
 SG_ AuxI_O65 : 38|2@1+ (1,0) [0|3] "" Vector__XXX
 SG_ AuxI_O66 : 36|2@1+ (1,0) [0|3] "" Vector__XXX
 SG_ AuxI_O67 : 34|2@1+ (1,0) [0|3] "" Vector__XXX
 SG_ AuxI_O68 : 32|2@1+ (1,0) [0|3] "" Vector__XXX
 SG_ AuxI_O61 : 30|2@1+ (1,0) [0|3] "" Vector__XXX
 SG_ AuxI_O62 : 28|2@1+ (1,0) [0|3] "" Vector__XXX
 SG_ AuxI_O63 : 26|2@1+ (1,0) [0|3] "" Vector__XXX
 SG_ AuxI_O64 : 24|2@1+ (1,0) [0|3] "" Vector__XXX
 SG_ AuxI_O57 : 22|2@1+ (1,0) [0|3] "" Vector__XXX
 SG_ AuxI_O58 : 20|2@1+ (1,0) [0|3] "" Vector__XXX
 SG_ AuxI_O59 : 18|2@1+ (1,0) [0|3] "" Vector__XXX
 SG_ AuxI_O60 : 16|2@1+ (1,0) [0|3] "" Vector__XXX
 SG_ AuxI_O53 : 14|2@1+ (1,0) [0|3] "" Vector__XXX
 SG_ AuxI_O54 : 12|2@1+ (1,0) [0|3] "" Vector__XXX
 SG_ AuxI_O55 : 10|2@1+ (1,0) [0|3] "" Vector__XXX
 SG_ AuxI_O56 : 8|2@1+ (1,0) [0|3] "" Vector__XXX
 SG_ AuxI_O49 : 6|2@1+ (1,0) [0|3] "" Vector__XXX
 SG_ AuxI_O50 : 4|2@1+ (1,0) [0|3] "" Vector__XXX
 SG_ AuxI_O51 : 2|2@1+ (1,0) [0|3] "" Vector__XXX
 SG_ AuxI_O52 : 0|2@1+ (1,0) [0|3] "" Vector__XXX

BO_ 2561015550 AUXIO4: 8 Vector__XXX
 SG_ AuxI_O92 : 16|2@1+ (1,0) [0|3] "" Vector__XXX
 SG_ AuxI_O85 : 14|2@1+ (1,0) [0|3] "" Vector__XXX
 SG_ AuxI_O86 : 12|2@1+ (1,0) [0|3] "" Vector__XXX
 SG_ AuxI_O87 : 10|2@1+ (1,0) [0|3] "" Vector__XXX
 SG_ AuxI_O88 : 8|2@1+ (1,0) [0|3] "" Vector__XXX
 SG_ AuxI_O81 : 6|2@1+ (1,0) [0|3] "" Vector__XXX
 SG_ AuxI_O82 : 4|2@1+ (1,0) [0|3] "" Vector__XXX
 SG_ AuxI_O83 : 2|2@1+ (1,0) [0|3] "" Vector__XXX
 SG_ AuxI_O84 : 0|2@1+ (1,0) [0|3] "" Vector__XXX
 SG_ AuxI_O109 : 62|2@1+ (1,0) [0|3] "" Vector__XXX
 SG_ AuxI_O110 : 60|2@1+ (1,0) [0|3] "" Vector__XXX
 SG_ AuxI_O111 : 58|2@1+ (1,0) [0|3] "" Vector__XXX
 SG_ AuxI_O112 : 56|2@1+ (1,0) [0|3] "" Vector__XXX
 SG_ AuxI_O105 : 54|2@1+ (1,0) [0|3] "" Vector__XXX
 SG_ AuxI_O106 : 52|2@1+ (1,0) [0|3] "" Vector__XXX
 SG_ AuxI_O107 : 50|2@1+ (1,0) [0|3] "" Vector__XXX
 SG_ AuxI_O108 : 48|2@1+ (1,0) [0|3] "" Vector__XXX
 SG_ AuxI_O101 : 46|2@1+ (1,0) [0|3] "" Vector__XXX
 SG_ AuxI_O102 : 44|2@1+ (1,0) [0|3] "" Vector__XXX
 SG_ AuxI_O103 : 42|2@1+ (1,0) [0|3] "" Vector__XXX
 SG_ AuxI_O104 : 40|2@1+ (1,0) [0|3] "" Vector__XXX
 SG_ AuxI_O97 : 38|2@1+ (1,0) [0|3] "" Vector__XXX
 SG_ AuxI_O98 : 36|2@1+ (1,0) [0|3] "" Vector__XXX
 SG_ AuxI_O99 : 34|2@1+ (1,0) [0|3] "" Vector__XXX
 SG_ AuxI_O100 : 32|2@1+ (1,0) [0|3] "" Vector__XXX
 SG_ AuxI_O93 : 30|2@1+ (1,0) [0|3] "" Vector__XXX
 SG_ AuxI_O94 : 28|2@1+ (1,0) [0|3] "" Vector__XXX
 SG_ AuxI_O95 : 26|2@1+ (1,0) [0|3] "" Vector__XXX
 SG_ AuxI_O96 : 24|2@1+ (1,0) [0|3] "" Vector__XXX
 SG_ AuxI_O89 : 22|2@1+ (1,0) [0|3] "" Vector__XXX
 SG_ AuxI_O90 : 20|2@1+ (1,0) [0|3] "" Vector__XXX
 SG_ AuxI_O91 : 18|2@1+ (1,0) [0|3] "" Vector__XXX

BO_ 2566746622 BSA: 8 Vector__XXX
 SG_ TrailerBrakeStrokeAxle5Right : 57|3@1+ (1,0) [0|7] "" Vector__XXX
 SG_ TrailerBrakeStrokeAxle5Left : 54|3@1+ (1,0) [0|7] "" Vector__XXX
 SG_ TrailerBrakeStrokeAxle4Right : 51|3@1+ (1,0) [0|7] "" Vector__XXX
 SG_ TrailerBrakeStrokeAxle4Left : 48|3@1+ (1,0) [0|7] "" Vector__XXX
 SG_ TrailerBrakeStrokeAxle3Right : 45|3@1+ (1,0) [0|7] "" Vector__XXX
 SG_ TrailerBrakeStrokeAxle3Left : 42|3@1+ (1,0) [0|7] "" Vector__XXX
 SG_ TrailerBrakeStrokeAxle2Right : 39|3@1+ (1,0) [0|7] "" Vector__XXX
 SG_ TrailerBrakeStrokeAxle2Left : 36|3@1+ (1,0) [0|7] "" Vector__XXX
 SG_ TrailerBrakeStrokeAxle1Right : 33|3@1+ (1,0) [0|7] "" Vector__XXX
 SG_ TrailerBrakeStrokeAxle1Left : 30|3@1+ (1,0) [0|7] "" Vector__XXX
 SG_ TractorBrakeStrokeAxle5Right : 27|3@1+ (1,0) [0|7] "" Vector__XXX
 SG_ TractorBrakeStrokeAxle5Left : 24|3@1+ (1,0) [0|7] "" Vector__XXX
 SG_ TractorBrakeStrokeAxle4Right : 21|3@1+ (1,0) [0|7] "" Vector__XXX
 SG_ TractorBrakeStrokeAxle4Left : 18|3@1+ (1,0) [0|7] "" Vector__XXX
 SG_ TractorBrakeStrokeAxle3Right : 15|3@1+ (1,0) [0|7] "" Vector__XXX
 SG_ TractorBrakeStrokeAxle3Left : 12|3@1+ (1,0) [0|7] "" Vector__XXX
 SG_ TractorBrakeStrokeAxle2Right : 9|3@1+ (1,0) [0|7] "" Vector__XXX
 SG_ TractorBrakeStrokeAxle2Left : 6|3@1+ (1,0) [0|7] "" Vector__XXX
 SG_ TractorBrakeStrokeAxle1Right : 3|3@1+ (1,0) [0|7] "" Vector__XXX
 SG_ TractorBrakeStrokeAxle1Left : 0|3@1+ (1,0) [0|7] "" Vector__XXX

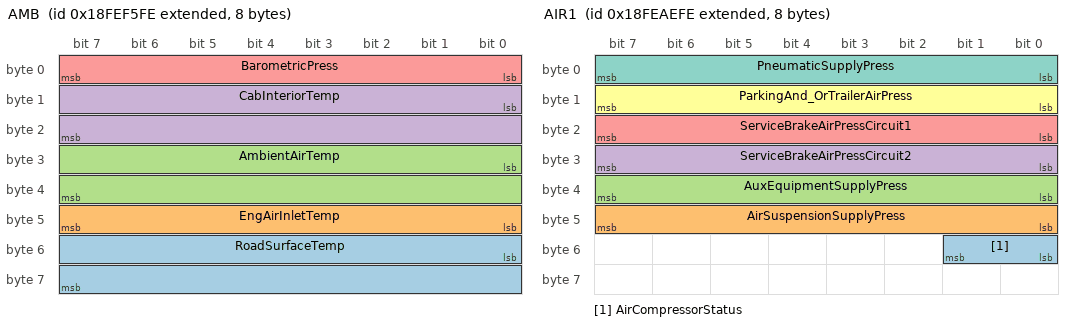
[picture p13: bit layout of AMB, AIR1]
BO_ 2566845950 AMB: 8 Vector__XXX
 SG_ RoadSurfaceTemp : 48|16@1+ (0.03125,-273) [-273|1735] "deg" Vector__XXX
 SG_ EngAirInletTemp : 40|8@1+ (1,-40) [-40|210] "deg" Vector__XXX
 SG_ AmbientAirTemp : 24|16@1+ (0.03125,-273) [-273|1735] "deg" Vector__XXX
 SG_ CabInteriorTemp : 8|16@1+ (0.03125,-273) [-273|1735] "deg" Vector__XXX
 SG_ BarometricPress : 0|8@1+ (0.5,0) [0|125] "kPa" Vector__XXX

BO_ 2566840062 AIR2: 8 Vector__XXX
 SG_ EngAirStartPress : 0|8@1+ (4,0) [0|1000] "kPa" Vector__XXX

BO_ 2566827774 AIR1: 8 Vector__XXX
 SG_ AirCompressorStatus : 48|2@1+ (1,0) [0|3] "" Vector__XXX
 SG_ AirSuspensionSupplyPress : 40|8@1+ (8,0) [0|2000] "kPa" Vector__XXX
 SG_ AuxEquipmentSupplyPress : 32|8@1+ (8,0) [0|2000] "kPa" Vector__XXX
 SG_ ServiceBrakeAirPressCircuit2 : 24|8@1+ (8,0) [0|2000] "kPa" Vector__XXX
 SG_ ServiceBrakeAirPressCircuit1 : 16|8@1+ (8,0) [0|2000] "kPa" Vector__XXX
 SG_ ParkingAnd_OrTrailerAirPress : 8|8@1+ (8,0) [0|2000] "kPa" Vector__XXX
 SG_ PneumaticSupplyPress : 0|8@1+ (8,0) [0|2000] "kPa" Vector__XXX

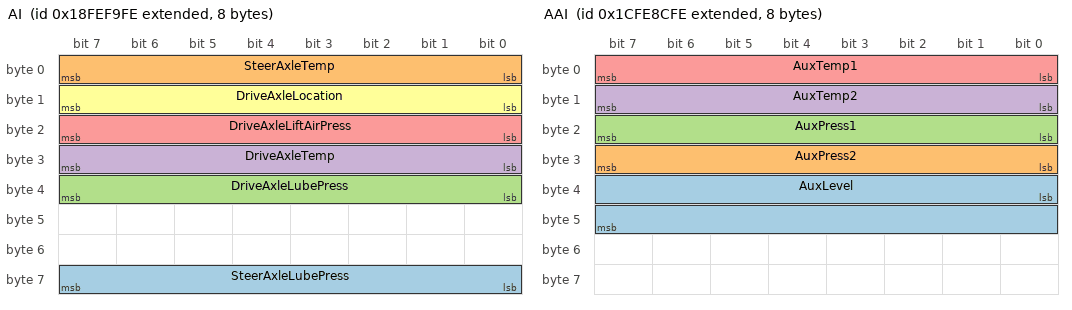
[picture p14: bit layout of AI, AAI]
BO_ 2566846974 AI: 8 Vector__XXX
 SG_ SteerAxleLubePress : 56|8@1+ (4,0) [0|1000] "kPa" Vector__XXX
 SG_ SteerAxleTemp : 0|8@1+ (1,-40) [-40|210] "deg" Vector__XXX
 SG_ DriveAxleLubePress : 32|8@1+ (4,0) [0|1000] "kPa" Vector__XXX
 SG_ DriveAxleTemp : 24|8@1+ (1,-40) [-40|210] "deg" Vector__XXX
 SG_ DriveAxleLiftAirPress : 16|8@1+ (4,0) [0|1000] "kPa" Vector__XXX
 SG_ DriveAxleLocation : 8|8@1+ (1,0) [0|255] "" Vector__XXX

BO_ 2633935614 AF2: 8 Vector__XXX
 SG_ EngTurboWastegateValvePos : 24|8@1+ (0.4,0) [0|100] "%" Vector__XXX
 SG_ EngGsMssFlwSnsrFelingCorrection : 32|8@1+ (1,-125) [-125|125] "%" Vector__XXX
 SG_ EngDsiredAbsIntakeManifoldPress : 8|16@1+ (0.1,0) [0|6425.5] "kPa" Vector__XXX
 SG_ EngGasFuelCorrectionFactor : 0|8@1+ (1,0) [0|250] "%" Vector__XXX

BO_ 2566803966 ACC2: 8 Vector__XXX
 SG_ RqedACCDistanceMode : 5|3@1+ (1,0) [0|7] "" Vector__XXX

BO_ 2432593918 ACC1: 8 Vector__XXX
 SG_ ACCDistanceAlertSignal : 52|2@1+ (1,0) [0|3] "" Vector__XXX
 SG_ ACCSystemShutoffWarning : 50|2@1+ (1,0) [0|3] "" Vector__XXX
 SG_ ACCTargetDetected : 48|2@1+ (1,0) [0|3] "" Vector__XXX
 SG_ RoadCurvature : 32|16@1+ (0.0078125,-250) [-250|251.992] "1/km" Vector__XXX
 SG_ AdptveCruiseCtrlSetDistanceMode : 27|3@1+ (1,0) [0|7] "" Vector__XXX
 SG_ AdaptiveCruiseCtrlMode : 24|3@1+ (1,0) [0|7] "" Vector__XXX
 SG_ AdaptiveCruiseCtrlSetSpeed : 16|8@1+ (1,0) [0|250] "km/h" Vector__XXX
 SG_ DistanceToForwardVehicle : 8|8@1+ (1,0) [0|250] "m" Vector__XXX
 SG_ SpeedOfForwardVehicle : 0|8@1+ (1,0) [0|250] "km/h" Vector__XXX

BO_ 2633935102 AC: 8 Vector__XXX
 SG_ ArticulationAngle : 0|8@1+ (1,-125) [-125|125] "deg" Vector__XXX

BO_ 2633927934 AAI: 8 Vector__XXX
 SG_ AuxLevel : 32|16@1+ (0.1,0) [0|6425.5] "mm" Vector__XXX
 SG_ AuxPress2 : 24|8@1+ (16,0) [0|4000] "kPa" Vector__XXX
 SG_ AuxPress1 : 16|8@1+ (16,0) [0|4000] "kPa" Vector__XXX
 SG_ AuxTemp2 : 8|8@1+ (1,-40) [-40|210] "deg" Vector__XXX
 SG_ AuxTemp1 : 0|8@1+ (1,-40) [-40|210] "deg" Vector__XXX

BO_ 2566847998 A1: 8 Vector__XXX
 SG_ EngBlowerBypassValvePos : 0|8@1+ (0.4,0) [0|100] "%" Vector__XXX
 SG_ EngGasSupplyPress : 8|16@1+ (0.5,0) [0|32127.5] "kPa" Vector__XXX

BO_ 2565406462 ACKM: 8 Vector__XXX
 SG_ AddressBusy m3 : 32|8@1+ (1,0) [0|255] "" Vector__XXX
 SG_ ControlByte M : 0|8@1+ (1,0) [0|255] "" Vector__XXX
 SG_ ParameterGroupNumber : 40|24@1+ (1,0) [0|16777215] "" Vector__XXX
 SG_ GroupFunctionValue : 8|8@1+ (1,0) [0|255] "" Vector__XXX
 SG_ AddressAccessDenied m2 : 32|8@1+ (1,0) [0|255] "" Vector__XXX
 SG_ AddressNegativeAcknowledgement m1 : 32|8@1+ (1,0) [0|255] "" Vector__XXX
 SG_ AddressAcknowledged m0 : 32|8@1+ (1,0) [0|255] "" Vector__XXX

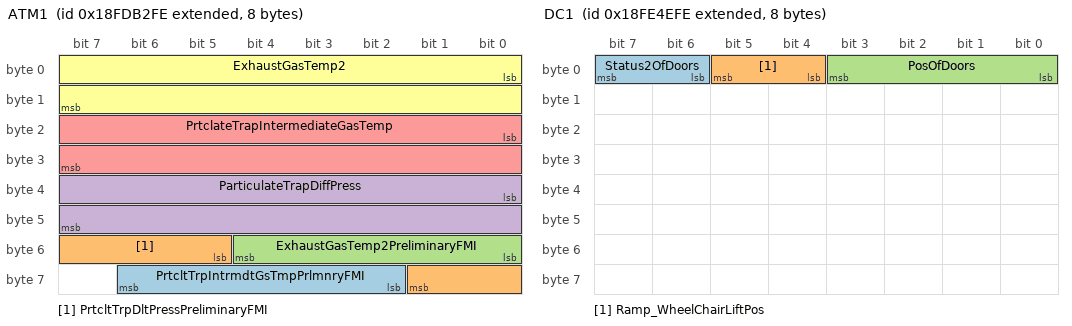
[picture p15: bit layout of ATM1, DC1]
BO_ 2566763262 ATM1: 8 Vector__XXX
 SG_ PrtcltTrpIntrmdtGsTmpPrlmnryFMI : 58|5@1+ (1,0) [0|31] "" Vector__XXX
 SG_ PrtcltTrpDltPressPreliminaryFMI : 53|5@1+ (1,0) [0|31] "" Vector__XXX
 SG_ ExhaustGasTemp2PreliminaryFMI : 48|5@1+ (1,0) [0|31] "" Vector__XXX
 SG_ ParticulateTrapDiffPress : 32|16@1+ (0.1,0) [0|6425.5] "kPa" Vector__XXX
 SG_ PrtclateTrapIntermediateGasTemp : 16|16@1+ (0.03125,-273) [-273|1735] "deg" Vector__XXX
 SG_ ExhaustGasTemp2 : 0|16@1+ (0.03125,-273) [-273|1735] "deg" Vector__XXX

BO_ 2566803198 DC1: 8 Vector__XXX
 SG_ Status2OfDoors : 6|2@1+ (1,0) [0|3] "" Vector__XXX
 SG_ Ramp_WheelChairLiftPos : 4|2@1+ (1,0) [0|3] "" Vector__XXX
 SG_ PosOfDoors : 0|4@1+ (1,0) [0|15] "" Vector__XXX

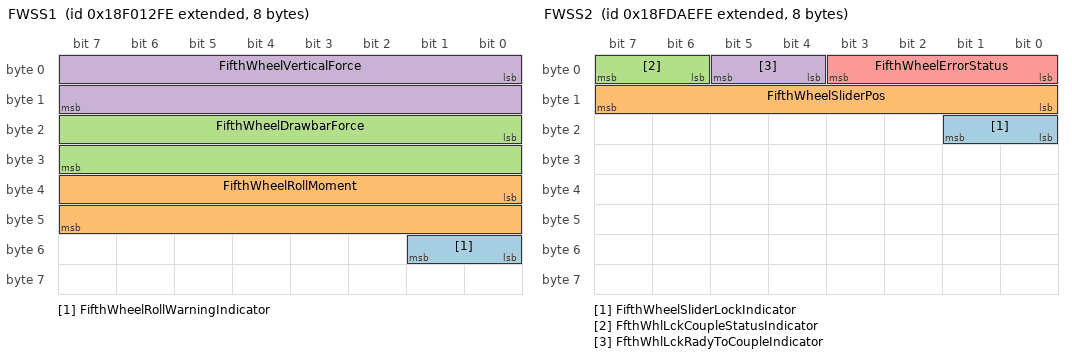
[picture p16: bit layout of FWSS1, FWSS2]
BO_ 2565870334 FWSS1: 8 Vector__XXX
 SG_ FifthWheelRollWarningIndicator : 48|2@1+ (1,0) [0|3] "" Vector__XXX
 SG_ FifthWheelRollMoment : 32|16@1+ (10,-320000) [-320000|322550] "N" Vector__XXX
 SG_ FifthWheelDrawbarForce : 16|16@1+ (10,-320000) [-320000|322550] "N" Vector__XXX
 SG_ FifthWheelVerticalForce : 0|16@1+ (5,0) [0|321275] "N" Vector__XXX

BO_ 2566762238 FWSS2: 8 Vector__XXX
 SG_ FifthWheelSliderLockIndicator : 16|2@1+ (1,0) [0|3] "" Vector__XXX
 SG_ FifthWheelSliderPos : 8|8@1+ (10,0) [0|2500] "mm" Vector__XXX
 SG_ FfthWhlLckCoupleStatusIndicator : 6|2@1+ (1,0) [0|3] "" Vector__XXX
 SG_ FfthWhlLckRadyToCoupleIndicator : 4|2@1+ (1,0) [0|3] "" Vector__XXX
 SG_ FifthWheelErrorStatus : 0|4@1+ (1,0) [0|15] "" Vector__XXX

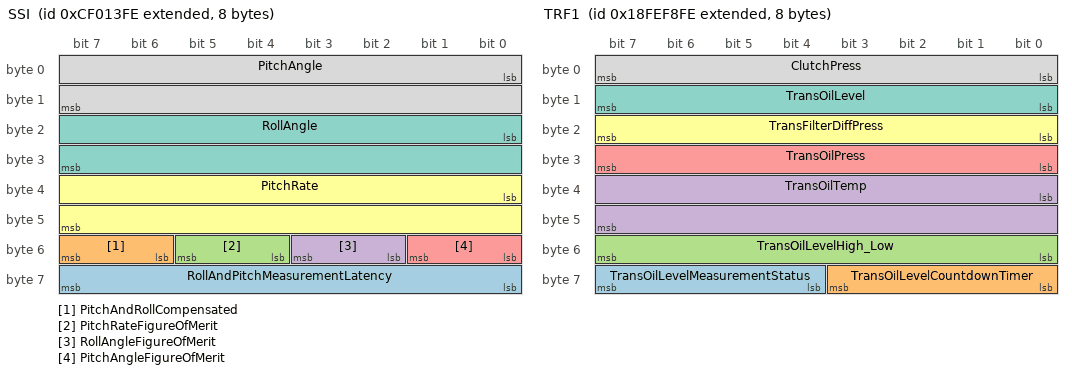
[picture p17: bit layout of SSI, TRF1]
BO_ 2364543998 SSI: 8 Vector__XXX
 SG_ RollAndPitchMeasurementLatency : 56|8@1+ (0.5,0) [0|125] "ms" Vector__XXX
 SG_ PitchAndRollCompensated : 54|2@1+ (1,0) [0|3] "" Vector__XXX
 SG_ PitchRateFigureOfMerit : 52|2@1+ (1,0) [0|3] "" Vector__XXX
 SG_ RollAngleFigureOfMerit : 50|2@1+ (1,0) [0|3] "" Vector__XXX
 SG_ PitchAngleFigureOfMerit : 48|2@1+ (1,0) [0|3] "" Vector__XXX
 SG_ PitchRate : 32|16@1+ (0.002,-64) [-64|64.51] "deg/sec" Vector__XXX
 SG_ RollAngle : 16|16@1+ (0.002,-64) [-64|64.51] "deg" Vector__XXX
 SG_ PitchAngle : 0|16@1+ (0.002,-64) [-64|64.51] "deg" Vector__XXX

BO_ 2566846718 TRF1: 8 Vector__XXX
 SG_ TransOilLevelMeasurementStatus : 60|4@1+ (1,0) [0|15] "" Vector__XXX
 SG_ TransOilLevelCountdownTimer : 56|4@1+ (1,0) [0|15] "" Vector__XXX
 SG_ TransOilLevelHigh_Low : 48|8@1+ (0.5,-62.5) [-62.5|62.5] "L" Vector__XXX
 SG_ TransOilTemp : 32|16@1+ (0.03125,-273) [-273|1735] "deg" Vector__XXX
 SG_ TransOilPress : 24|8@1+ (16,0) [0|4000] "kPa" Vector__XXX
 SG_ TransFilterDiffPress : 16|8@1+ (2,0) [0|500] "kPa" Vector__XXX
 SG_ TransOilLevel : 8|8@1+ (0.4,0) [0|100] "%" Vector__XXX
 SG_ ClutchPress : 0|8@1+ (16,0) [0|4000] "kPa" Vector__XXX

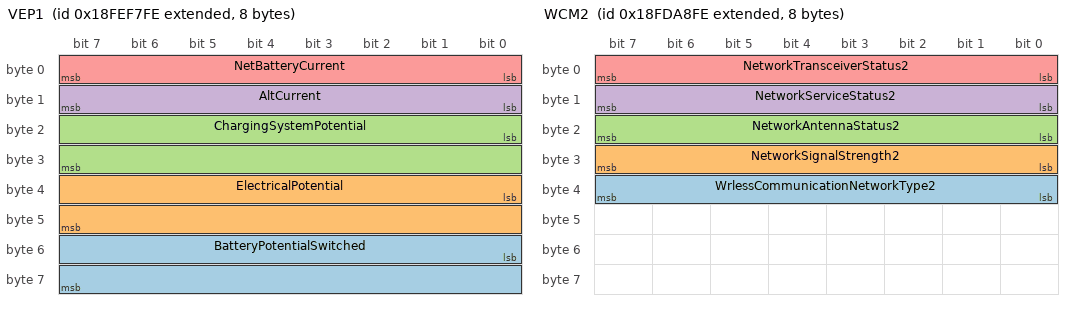
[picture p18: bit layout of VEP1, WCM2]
BO_ 2566846462 VEP1: 8 Vector__XXX
 SG_ BatteryPotentialSwitched : 48|16@1+ (0.05,0) [0|3212.75] "V" Vector__XXX
 SG_ ElectricalPotential : 32|16@1+ (0.05,0) [0|3212.75] "V" Vector__XXX
 SG_ ChargingSystemPotential : 16|16@1+ (0.05,0) [0|3212.75] "V" Vector__XXX
 SG_ AltCurrent : 8|8@1+ (1,0) [0|250] "A" Vector__XXX
 SG_ NetBatteryCurrent : 0|8@1+ (1,-125) [-125|125] "A" Vector__XXX

BO_ 2566760702 WCM2: 8 Vector__XXX
 SG_ WrlessCommunicationNetworkType2 : 32|8@1+ (1,0) [0|255] "" Vector__XXX
 SG_ NetworkSignalStrength2 : 24|8@1+ (0.4,0) [0|100] "%" Vector__XXX
 SG_ NetworkAntennaStatus2 : 16|8@1+ (1,0) [0|255] "" Vector__XXX
 SG_ NetworkServiceStatus2 : 8|8@1+ (1,0) [0|255] "" Vector__XXX
 SG_ NetworkTransceiverStatus2 : 0|8@1+ (1,0) [0|255] "" Vector__XXX

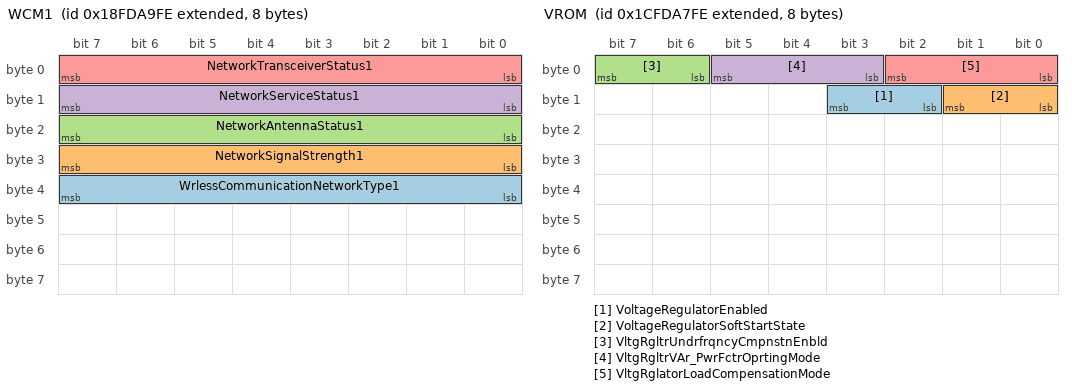
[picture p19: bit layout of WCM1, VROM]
BO_ 2566760958 WCM1: 8 Vector__XXX
 SG_ WrlessCommunicationNetworkType1 : 32|8@1+ (1,0) [0|255] "" Vector__XXX
 SG_ NetworkSignalStrength1 : 24|8@1+ (0.4,0) [0|100] "%" Vector__XXX
 SG_ NetworkAntennaStatus1 : 16|8@1+ (1,0) [0|255] "" Vector__XXX
 SG_ NetworkServiceStatus1 : 8|8@1+ (1,0) [0|255] "" Vector__XXX
 SG_ NetworkTransceiverStatus1 : 0|8@1+ (1,0) [0|255] "" Vector__XXX

BO_ 2633869310 VROM: 8 Vector__XXX
 SG_ VoltageRegulatorEnabled : 10|2@1+ (1,0) [0|3] "" Vector__XXX
 SG_ VoltageRegulatorSoftStartState : 8|2@1+ (1,0) [0|3] "" Vector__XXX
 SG_ VltgRgltrUndrfrqncyCmpnstnEnbld : 6|2@1+ (1,0) [0|3] "" Vector__XXX
 SG_ VltgRgltrVAr_PwrFctrOprtingMode : 3|3@1+ (1,0) [0|7] "" Vector__XXX
 SG_ VltgRglatorLoadCompensationMode : 0|3@1+ (1,0) [0|7] "" Vector__XXX

BO_ 2365433598 VREP: 8 Vector__XXX
 SG_ GnrtrOtputVoltageBiasPercentage : 32|16@1+ (0.1,-100) [-100|100] "%" Vector__XXX
 SG_ GeneratorExcitationFieldCurrent : 16|16@1+ (0.05,0) [0|3217.5] "A" Vector__XXX
 SG_ GeneratorExcitationFieldVoltage : 0|16@1+ (0.05,-1605.625) [-1605.625|1606.375] "V" Vector__XXX

CM_ BO_ 2566781694 "Generator Total AC Energy";
CM_ SG_ 2566781694 GeneratorTotalKWHoursImport "The total kilowatt-hours that have been imported by the generator.";
CM_ SG_ 2566781694 GeneratorTotalKWHoursExport "The total kilowatt-hours that have been exported by the generator.";
CM_ BO_ 2566781950 "Generator Phase C AC Reactive Power";
CM_ SG_ 2566781950 GnratorPhaseCPowerFactorLagging "Lead/lag status for generator phase C power factor.";
CM_ SG_ 2566781950 GeneratorPhaseCPowerFactor "The power factor of phases C of the generator.";
CM_ SG_ 2566781950 GeneratorPhaseCReactivePower "The reactive power delivered by phase C of the generator";
CM_ BO_ 2566782206 "Generator Phase C AC Power";
CM_ SG_ 2566782206 GeneratorPhaseCApparentPower "The apparent power delivered by phase C of the generator.";
CM_ SG_ 2566782206 GeneratorPhaseCRealPower "The real power delivered by phase C of the generator.";
CM_ BO_ 2566782462 "Generator Phase C Basic AC Quantities";
CM_ SG_ 2566782462 GeneratorPhaseCACRMSCurrent "RMS current measured at the generator phase C output.";
CM_ SG_ 2566782462 GeneratorPhaseCACFrequency "AC frequency measured at the generator phase C output.";
CM_ SG_ 2566782462 GnrtrPhsCLneNeutralACRMSVoltage "Line to Neutral RMS voltage measured at the generator phase C output.";
CM_ SG_ 2566782462 GnrtrPhseCALineLineACRMSVoltage "Line to Line RMS voltage measured at the generator phase CA output.";
CM_ BO_ 2566782718 "Generator Phase B AC Reactive Power";
CM_ SG_ 2566782718 GnratorPhaseBPowerFactorLagging "Lead/lag status for generator phase B power factor.";
CM_ SG_ 2566782718 GeneratorPhaseBPowerFactor "The power factor of phases B of the generator.";
CM_ SG_ 2566782718 GeneratorPhaseBReactivePower "The reactive power delivered by phase B of the generator";
CM_ BO_ 2566782974 "Generator Phase B AC Power";
CM_ SG_ 2566782974 GeneratorPhaseBApparentPower "The apparent power delivered by phase B of the generator.";
CM_ SG_ 2566782974 GeneratorPhaseBRealPower "The real power delivered by phase B of the generator.";
CM_ BO_ 2566783230 "Generator Phase B Basic AC Quantities";
CM_ SG_ 2566783230 GeneratorPhaseBACRMSCurrent "RMS current measured at the generator phase B output.";
CM_ SG_ 2566783230 GeneratorPhaseBACFrequency "AC frequency measured at the generator phase B output.";
CM_ SG_ 2566783230 GnrtrPhsBLneNeutralACRMSVoltage "Line to Neutral RMS voltage measured at the generator phase B output.";
CM_ SG_ 2566783230 GnrtrPhseBCLineLineACRMSVoltage "Line to Line RMS voltage measured at the generator phase BC output.";
CM_ BO_ 2566783486 "Generator Phase A AC Reactive Power";
CM_ SG_ 2566783486 GnratorPhaseAPowerFactorLagging "Lead/lag status for generator phase A power factor.";
CM_ SG_ 2566783486 GeneratorPhaseAPowerFactor "The power factor of phase A of the generator.";
CM_ SG_ 2566783486 GeneratorPhaseAReactivePower "The reactive power delivered by phase A of the generator";
CM_ BO_ 2566783742 "Generator Phase A AC Power";
CM_ SG_ 2566783742 GeneratorPhaseAApparentPower "The apparent power delivered by phase A of the generator.";
CM_ SG_ 2566783742 GeneratorPhaseARealPower "The real power delivered by phase A of the generator.";
CM_ BO_ 2566783998 "Generator Phase A Basic AC Quantities";
CM_ SG_ 2566783998 GeneratorPhaseAACRMSCurrent "RMS current measured at the generator phase A output.";
CM_ SG_ 2566783998 GeneratorPhaseAACFrequency "AC frequency measured at the generator phase A output.";
CM_ SG_ 2566783998 GnrtrPhsALneNeutralACRMSVoltage "Line to Neutral RMS voltage measured at the generator phase A output.";
CM_ SG_ 2566783998 GnrtrPhseABLineLineACRMSVoltage "Line to Line RMS voltage measured at the generator phase AB output.";
CM_ BO_ 2566784766 "Generator Average Basic AC Quantities";
CM_ SG_ 2566784766 GeneratorAverageACRMSCurrent "Average RMS current measured at the generator output.";
CM_ SG_ 2566784766 GeneratorAverageACFrequency "Average AC frequency measured at the generator output.";
CM_ SG_ 2566784766 GnrtrAvrgLneNeutralACRMSVoltage "The average Line to Neutral AC RMS voltage measured at the Generator output.";
CM_ SG_ 2566784766 GnrtrAvrageLineLineACRMSVoltage "Average Line to Line RMS voltage measured at the generator output.";
CM_ BO_ 2566776830 "Bus #1/Utility Sync Check Status";
CM_ SG_ 2566776830 Bus1_UtilityACPhaseDifference "The phase difference between the Bus #1 voltage and Utility voltage.";
CM_ SG_ 2566776830 Bus1_UtilityInSync "Indicator of whether Bus #1 and Utility are properly synchronized for paralleling. This indicator will be based on parameters such as Voltage Match, Frequency Match, and Phase Match.";
CM_ SG_ 2566776830 Bus1_UtilityVoltageMatch "Indicator of whether voltage difference between Bus #1 and Utility is adequate for paralleling. This indicator will be based on the measured AC voltages qualified using parameters such as Voltage Tolerance.";
CM_ SG_ 2566776830 Bus1_UtilityFrequencyMatch "Indicator of whether frequency difference between Bus #1 and Utility is adequate for paralleling. This indicator will be based on the measured AC frequencies qualified using parameters such as Frequency Tolerance, Phase Tolerance, and Dwell Time.";
CM_ SG_ 2566776830 Bus1_UtilityPhaseMatch "Indicator of whether phase difference between Bus #1 and Utility is adequate for paralleling. This indicator will be based on the measured AC phase difference qualified using parameters such as Phase Tolerance and Dwell Time.";
CM_ SG_ 2566776830 Bus1_UtilityDeadBus "Indicator of whether Bus #1 is considered dead for closing to the utility. This indicator will be based on parameters such as Bus #1 Voltage and dead bus threshold values.";
CM_ BO_ 2566777342 "Bus #1 Phase C  Basic AC Quantities";
CM_ SG_ 2566777342 Bus1PhaseCACFrequency "AC frequency measured at bus #1 phase C.";
CM_ SG_ 2566777342 Bs1PhseCLineNeutralACRMSVoltage "Line to Neutral RMS voltage measured at bus #1 phase C.";
CM_ SG_ 2566777342 Bus1PhaseCALineLineACRMSVoltage "Line to Line RMS voltage measured at bus #1 phase CA.";
CM_ BO_ 2566777598 "Bus #1 Phase B  Basic AC Quantities";
CM_ SG_ 2566777598 Bus1PhaseBACFrequency "AC frequency measured at bus #1 phase B.";
CM_ SG_ 2566777598 Bs1PhseBLineNeutralACRMSVoltage "Line to Neutral RMS voltage measured at bus #1 phase B.";
CM_ SG_ 2566777598 Bus1PhaseBCLineLineACRMSVoltage "Line to Line RMS voltage measured at bus #1 phase BC.";
CM_ BO_ 2566777854 "Bus #1 Phase A  Basic AC Quantities";
CM_ SG_ 2566777854 Bus1PhaseAACFrequency "AC frequency measured at bus #1 phase A.";
CM_ SG_ 2566777854 Bs1PhseALineNeutralACRMSVoltage "Line to Neutral RMS voltage measured at bus #1 phase A.";
CM_ SG_ 2566777854 Bus1PhaseABLineLineACRMSVoltage "Line to Line RMS voltage measured at bus #1 phase AB.";
CM_ BO_ 2566777086 "Bus #1/Generator Sync Check Status";
CM_ SG_ 2566777086 Bus1_GeneratorACPhaseDifference "The phase difference between the Bus #1 voltage and Generator voltage.";
CM_ SG_ 2566777086 Bus1_GeneratorInSync "Indicator of whether Bus #1 and Generator are properly synchronized for paralleling. This indicator will be based on parameters such as Voltage Match, Frequency Match, and Phase Match.";
CM_ SG_ 2566777086 Bus1_GeneratorVoltageMatch "Indicator of whether voltage difference between Bus #1 and Generator is adequate for paralleling. This indicator will be based on the measured AC voltages qualified using parameters such as Voltage Tolerance.";
CM_ SG_ 2566777086 Bus1_GeneratorFrequencyMatch "Indicator of whether frequency difference between Bus #1 and Generator is adequate for paralleling. This indicator will be based on the measured AC frequencies qualified using parameters such as Frequency Tolerance, Phase Tolerance, and Dwell Time.";
CM_ SG_ 2566777086 Bus1_GeneratorPhaseMatch "Indicator of whether phase difference between Bus #1 and Generator is adequate for paralleling. This indicator will be based on the measured AC phase difference qualified using parameters such as Phase Tolerance and Dwell Time.";
CM_ SG_ 2566777086 Bus1_GeneratorDeadBus "Indicator of whether Bus #1 is considered dead for closing to the generator. This indicator will be based on parameters such as Bus #1 Voltage and dead bus threshold values.";
CM_ BO_ 2566778110 "Bus #1 Average Basic AC Quantities";
CM_ SG_ 2566778110 Bus1AverageACFrequency "Average AC frequency measured at bus #1.";
CM_ SG_ 2566778110 Bs1AvrgeLineNeutralACRMSVoltage "The average Line to Neutral AC RMS voltage measured at bus #1 .";
CM_ SG_ 2566778110 Bus1AverageLineLineACRMSVoltage "Average Line to Line RMS voltage measured at bus #1 .";
CM_ BO_ 2633895422 "Working Set Master";
CM_ BO_ 2566838526 "Commanded Address";
CM_ SG_ 2566838526 IndustryGroup "0 = Global; 
   1  = On-Highway; 
   2  = Agricultural and Forestry; 
   3  = Construction; 
   4  = Marine;
   5  = Industrial - Process
          Control - Stationary (Gen-Sets)
   6  = Reserve for SAE
   7  = Reserve for SAE";
CM_ SG_ 2566838526 ManufacturerCode "Assigned by NMEA 2000 Committee";
CM_ SG_ 2566838526 AddressAssignment "The source address that is to be assigned to the CA that has the NAME corresponding to the one conveyed in the first eight bytes of this Commanded Address message.";
CM_ BO_ 2565799678 "Address Claimed";
CM_ SG_ 2565799678 IndustryGroup "0 = Global; 
   1  = On-Highway; 
   2  = Agricultural and Forestry; 
   3  = Construction; 
   4  = Marine;
   5  = Industrial - Process
          Control - Stationary (Gen-Sets)
   6  = Reserve for SAE
   7  = Reserve for SAE";
CM_ SG_ 2565799678 ManufacturerCode "Assigned by NMEA 2000 Committee";
CM_ BO_ 2563440382 "Transfer";
CM_ SG_ 2563440382 ShrtNameOfActualReportingDevice "Short name of reporting device of the requested PGN via the Transfer PGN.";
CM_ SG_ 2563440382 LengthOfDataForTheReportedPGN "Length of data reported with the associated PGN via the Transfer PGN.";
CM_ SG_ 2563440382 PGNofRequstedInformation "PGN associated with this transfer message";
CM_ BO_ 2565603070 "Transport Protocol - Data Transfer";
CM_ BO_ 2565668606 "Transport Protocol - Connection Management";
CM_ SG_ 2565668606 TotalNumberOfPacketsEoMA "Total number of packets for BAM message.Total number of packets received for RTS/CTS message.Total number of packets for RTS/CTS message.";
CM_ SG_ 2565668606 TotalMessageSizeEoMA "Total message size (in bytes) for BAM message.Total message size (in bytes) for RTS/CTS message.Total message size (in bytes) for RTS/CTS message.";
CM_ SG_ 2565668606 TotalMessageSizeBAM "Total message size (in bytes) for BAM message.Total message size (in bytes) for RTS/CTS message.Total message size (in bytes) for RTS/CTS message.";
CM_ SG_ 2565668606 TotalNumberOfPacketsBAM "Total number of packets for BAM message.Total number of packets received for RTS/CTS message.Total number of packets for RTS/CTS message.";
CM_ SG_ 2565668606 ConnectionAbortReason "Reason for connection abort message.";
CM_ SG_ 2565668606 NextPacketNumberToBeSent "Next Packet Number to be sent (TP.CM_CTS)";
CM_ SG_ 2565668606 NumberOfPacketsThatCanBeSent "Number of Packets that can be sent (TP.CM_CTS)";
CM_ SG_ 2565668606 MaximumNumberOfPackets "Maximum number of packets for RTS/CTS message.";
CM_ SG_ 2565668606 TotalNumberOfPackets "Total number of packets for BAM message.Total number of packets received for RTS/CTS message.Total number of packets for RTS/CTS message.";
CM_ SG_ 2565668606 TotalMessageSize "Total message size (in bytes) for BAM message.Total message size (in bytes) for RTS/CTS message.Total message size (in bytes) for RTS/CTS message.";
CM_ BO_ 2563374846 "Request 2";
CM_ SG_ 2563374846 UseTransferMode "Requester is to respond via the Transfer PGN";
CM_ SG_ 2563374846 ParameterGroupNumber "PGN which is requested by Request2 message";
CM_ BO_ 2565537534 "Request";
CM_ SG_ 2565537534 ParameterGroupNumber "PGN which is requested by Request2 message";
CM_ BO_ 2560556798 "DTC Counts";
CM_ SG_ 2560556798 PermanentDTCs "Identifies the current number of permanent DTCs";
CM_ SG_ 2560556798 PreviouslyMILOnDTCs "Identifies the current number of previously MIL-On DTCs";
CM_ SG_ 2560556798 MILOnDTCs "Identifies the current number of MIL-On DTCs";
CM_ SG_ 2560556798 AllPendingDTCs "Identifies the current total number of pending DTCs, including emission related";
CM_ SG_ 2560556798 PendingDTCs "Identifies the current number of emission related pending DTCs";
CM_ BO_ 2566750462 "Permanent DTCs";
CM_ SG_ 2566750462 SPN5 "SPN #5 (Conversion Version 4)";
CM_ SG_ 2566750462 SPN4 "SPN #4 (Conversion Version 4)";
CM_ SG_ 2566750462 SPN3 "SPN #3 (Conversion Version 4)";
CM_ SG_ 2566750462 SPN2 "SPN #2 (Conversion Version 4)";
CM_ SG_ 2566750462 FailureModeIdentifier5 "The FMI defines the type of failure detected in the subsystem identified by an SPN.";
CM_ SG_ 2566750462 FailureModeIdentifier4 "The FMI defines the type of failure detected in the subsystem identified by an SPN.";
CM_ SG_ 2566750462 FailureModeIdentifier3 "The FMI defines the type of failure detected in the subsystem identified by an SPN.";
CM_ SG_ 2566750462 FlashRedStopLamp "This parameter provides the capability to flash the RSL (SPN 3039).";
CM_ SG_ 2566750462 FlashProtectLamp "This parameter provides the capability to flash the engine protect lamp (SPN 3041).";
CM_ SG_ 2566750462 FlashMalfuncIndicatorLamp "This parameter provides the capability to flash the MIL (SPN 3038).";
CM_ SG_ 2566750462 FlashAmberWarningLamp "This parameter provides the capability to flash the AWL (SPN 3040). ";
CM_ SG_ 2566750462 MalfunctionIndicatorLampStatus "A lamp used to relay only emissions-related trouble code information.";
CM_ SG_ 2566750462 AmberWarningLampStatus "This lamp is used to relay trouble code information that is reporting a problem with the vehicle system but the vehicle need
not be immediately stopped.";
CM_ SG_ 2566750462 OccurenceCount1 "The 7 bit occurence count field contains the number of times a fault has gone from active to previously active.";
CM_ SG_ 2566750462 FailureModeIdentifier1 "The FMI defines the type of failure detected in the subsystem identified by an SPN.";
CM_ SG_ 2566750462 SPN1 "SPN #1 (Conversion Version 4)";
CM_ SG_ 2566750462 RedStopLampState "This lamp is uesed to relay trouble code information that is of a severe enought condition that it warrants stopping the vehicle.";
CM_ SG_ 2566750462 ProtectLampStatus "This lamp is used to relay trouble code informatio that is reporting a problem with a vehicle system that is most
probably not electronic subsystem related.";
CM_ SG_ 2566750462 FailureModeIdentifier2 "The FMI defines the type of failure detected in the subsystem identified by an SPN.";
CM_ SG_ 2566750462 OccurenceCount5 "The 7 bit occurence count field contains the number of times a fault has gone from active to previously active.";
CM_ SG_ 2566750462 OccurenceCount4 "The 7 bit occurence count field contains the number of times a fault has gone from active to previously active.";
CM_ SG_ 2566750462 OccurenceCount3 "The 7 bit occurence count field contains the number of times a fault has gone from active to previously active.";
CM_ SG_ 2566750462 OccurenceCount2 "The 7 bit occurence count field contains the number of times a fault has gone from active to previously active.";
CM_ SG_ 2566750462 SPN5High "SPN #5 (Conversion Version 4)";
CM_ SG_ 2566750462 SPN4High "SPN #4 (Conversion Version 4)";
CM_ SG_ 2566750462 SPN3High "SPN #3 (Conversion Version 4)";
CM_ SG_ 2566750462 SPN2High "SPN #2 (Conversion Version 4)";
CM_ SG_ 2566750462 SPN1High "SPN #1 (Conversion Version 4)";
CM_ BO_ 2566750974 "All Pending DTCs";
CM_ SG_ 2566750974 SPN5 "SPN #5 (Conversion Version 4)";
CM_ SG_ 2566750974 SPN4 "SPN #4 (Conversion Version 4)";
CM_ SG_ 2566750974 SPN3 "SPN #3 (Conversion Version 4)";
CM_ SG_ 2566750974 SPN2 "SPN #2 (Conversion Version 4)";
CM_ SG_ 2566750974 FailureModeIdentifier5 "The FMI defines the type of failure detected in the subsystem identified by an SPN.";
CM_ SG_ 2566750974 FailureModeIdentifier4 "The FMI defines the type of failure detected in the subsystem identified by an SPN.";
CM_ SG_ 2566750974 FailureModeIdentifier3 "The FMI defines the type of failure detected in the subsystem identified by an SPN.";
CM_ SG_ 2566750974 FlashRedStopLamp "This parameter provides the capability to flash the RSL (SPN 3039).";
CM_ SG_ 2566750974 FlashProtectLamp "This parameter provides the capability to flash the engine protect lamp (SPN 3041).";
CM_ SG_ 2566750974 FlashMalfuncIndicatorLamp "This parameter provides the capability to flash the MIL (SPN 3038).";
CM_ SG_ 2566750974 FlashAmberWarningLamp "This parameter provides the capability to flash the AWL (SPN 3040). ";
CM_ SG_ 2566750974 MalfunctionIndicatorLampStatus "A lamp used to relay only emissions-related trouble code information.";
CM_ SG_ 2566750974 AmberWarningLampStatus "This lamp is used to relay trouble code information that is reporting a problem with the vehicle system but the vehicle need
not be immediately stopped.";
CM_ SG_ 2566750974 OccurenceCount1 "The 7 bit occurence count field contains the number of times a fault has gone from active to previously active.";
CM_ SG_ 2566750974 FailureModeIdentifier1 "The FMI defines the type of failure detected in the subsystem identified by an SPN.";
CM_ SG_ 2566750974 SPN1 "SPN #1 (Conversion Version 4)";
CM_ SG_ 2566750974 RedStopLampState "This lamp is uesed to relay trouble code information that is of a severe enought condition that it warrants stopping the vehicle.";
CM_ SG_ 2566750974 ProtectLampStatus "This lamp is used to relay trouble code informatio that is reporting a problem with a vehicle system that is most
probably not electronic subsystem related.";
CM_ SG_ 2566750974 FailureModeIdentifier2 "The FMI defines the type of failure detected in the subsystem identified by an SPN.";
CM_ SG_ 2566750974 OccurenceCount5 "The 7 bit occurence count field contains the number of times a fault has gone from active to previously active.";
CM_ SG_ 2566750974 OccurenceCount4 "The 7 bit occurence count field contains the number of times a fault has gone from active to previously active.";
CM_ SG_ 2566750974 OccurenceCount3 "The 7 bit occurence count field contains the number of times a fault has gone from active to previously active.";
CM_ SG_ 2566750974 OccurenceCount2 "The 7 bit occurence count field contains the number of times a fault has gone from active to previously active.";
CM_ SG_ 2566750974 SPN5High "SPN #5 (Conversion Version 4)";
CM_ SG_ 2566750974 SPN4High "SPN #4 (Conversion Version 4)";
CM_ SG_ 2566750974 SPN3High "SPN #3 (Conversion Version 4)";
CM_ SG_ 2566750974 SPN2High "SPN #2 (Conversion Version 4)";
CM_ SG_ 2566750974 SPN1High "SPN #1 (Conversion Version 4)";
CM_ BO_ 2566748414 "Aftertreatment 2 Trip Information";
CM_ SG_ 2566748414 Aftrtrtmnt2TrpPssvRgnrationTime "Total amount of time that aftertreatment device 2 has been in passive regeneration during the current trip period.";
CM_ SG_ 2566748414 Aftrtrtmnt2TrpNmbrOfPssvRgnrtns "Total number of passive regenerations by aftertreatment device 2 during the current trip period.";
CM_ SG_ 2566748414 Aftrtrtmnt2TrpNmbrOfActvRgnrtns "Total number of active regenerations by aftertreatment device 2 during the current trip period.";
CM_ SG_ 2566748414 Aftrtrtmnt2TrpNmbrOfActvRgnrtnMn "Total number of aftertreatment device 2 active regeneration manual requests by the operator during the current trip period.";
CM_ SG_ 2566748414 Aftrtrtmnt2TrpNmbrOfActvRgnrtnIn "Total number of aftertreatment device 2 active regeneration inhibit requests by the operator during the current trip period.";
CM_ SG_ 2566748414 Aftrtrtmnt2TrpActvRgnrationTime "Total amount of time that aftertreatment device 2 has been in active regeneration during the current trip period.";
CM_ SG_ 2566748414 Aftertreatment2TripFuelUsed "Total amount of fuel used by aftertreatment device 2 during the current trip period.";
CM_ SG_ 2566748414 Aftertreatment2TripDisabledTime "Total amount of time that aftertreatment 2 regeneration has been manually disabled during the current trip period.";
CM_ BO_ 2566748670 "Aftertreatment 1 Trip Information";
CM_ SG_ 2566748670 Aftrtrtmnt1TrpPssvRgnrationTime "Total amount of time that aftertreatment device 1 has been in passive regeneration during the current trip period.";
CM_ SG_ 2566748670 Aftrtrtmnt1TrpNmbrOfPssvRgnrtns "Total number of passive regenerations by Aftertreatment device 1 during the current trip period.";
CM_ SG_ 2566748670 Aftrtrtmnt1TrpNmbrOfActvRgnrtns "Total number of active regenerations by Aftertreatment device 1 during the current trip period.";
CM_ SG_ 2566748670 Aftrtrtmnt1TrpNmbrOfActvRgnrtnMn "Total number of Aftertreatment device 1 active regeneration manual requests by the operator during the current trip period.";
CM_ SG_ 2566748670 Aftrtrtmnt1TrpNmbrOfActvRgnrtnIn "Total number of aftertreatment device 1 active regeneration inhibit requests by the operator during the current trip period.";
CM_ SG_ 2566748670 Aftrtrtmnt1TrpActvRgnrationTime "Total amount of time that aftertreatment device 1 has been in active regeneration during the current trip period.";
CM_ SG_ 2566748670 Aftertreatment1TripFuelUsed "Total amount of fuel used by aftertreatment device 1 during the current trip period.";
CM_ SG_ 2566748670 Aftertreatment1TripDisabledTime "Total amount of time that aftertreatment 1 regeneration has been manually disabled during the current trip period.";
CM_ BO_ 2566745598 "Aftertreatment Air Control 3";
CM_ SG_ 2566745598 Aftrtreatment1SecondAirMassFlow "Indicates the secondary air mass flow for aftertreatment 1.";
CM_ SG_ 2566745598 Aftertreatment1SecondAirTemp "Indicates the secondary air temperature for aftertreatment 1.";
CM_ SG_ 2566745598 Aftrtratment1SecondAirDiffPress "Indicates the secondary air differential pressure for aftertreatment 1.";
CM_ BO_ 2566745342 "Aftertreatment Air Control 4";
CM_ SG_ 2566745342 Aftrtreatment2SecondAirMassFlow "Indicates the secondary air mass flow for aftertreatment 2.";
CM_ SG_ 2566745342 Aftertreatment2SecondAirTemp "Indicates the secondary air temperature for aftertreatment 2.";
CM_ SG_ 2566745342 Aftrtratment2SecondAirDiffPress "Indicates the secondary air differential pressure for aftertreatment 2.";
CM_ BO_ 2566754558 "Advertised Engine Torque Curve";
CM_ SG_ 2566754558 NumberOfAETCDataPoints "Indicates the number of speed / torque data points contained in the Advertised Engine Torque Curve broadcast (AETC).";
CM_ SG_ 2566754558 AETCDataCollectionStandard "Indicates the standardized method by which torque data was obtained for the Advertised Engine Torque Curve (AETC).";
CM_ BO_ 2566749950 "Adaptive Front-Lighting System Status";
CM_ SG_ 2566749950 RightHeadlampLightDistribution "This parameter indicates what kind of light distribution is set by the AFS system for the right headlamp.";
CM_ SG_ 2566749950 LeftHeadlampLightDistribution "This parameter indicates what kind of light distribution is set by the AFS system for the left headlamp.";
CM_ SG_ 2566749950 RghtHeadlampDynamicBendingLight "This parameter indicates whether the dynamic bending light of the left headlamp is working properly.";
CM_ SG_ 2566749950 LeftHeadlampDynamicBendingLight "This parameter indicates whether the dynamic bending light of the left headlamp is working properly.";
CM_ BO_ 2565869310 "Aftertreatment 1 Intake Gas 1";
CM_ SG_ 2565869310 Aftrtrtmnt1IntkGsSnsrHeaterCtrl "Indicates the heater status in the warm-up process.";
CM_ SG_ 2565869310 Aftertreatment1IntakeO2 "The actual oxidation factor (%O2) of the gas within the exhaust stream.";
CM_ BO_ 2566763774 "Aftertreatment 1 Intake Gas 2";
CM_ SG_ 2566763774 Aftrtrtmnt1PrtcltTrpIntkGasTemp "Temperature of engine combustion byproducts entering the particulate trap in exhaust bank 1.";
CM_ SG_ 2566763774 Aftertreatment1ExhaustGasTemp1 "The reading from the exhaust gas temperature sensor located farthest upstream in the aftertreatment system in exhaust bank 1.";
CM_ BO_ 2565869566 "Aftertreatment 1 Outlet Gas 1";
CM_ SG_ 2565869566 Aftrtrtmnt1OtltGsSnsrHeaterCtrl "Indicates the heater status in the warm-up process.";
CM_ SG_ 2565869566 Aftertreatment1OutletO2 "The actual oxidation factor (%O2) of the gas within the exhaust stream.";
CM_ BO_ 2566763518 "Aftertreatment 1 Outlet Gas 2";
CM_ SG_ 2566763518 Aftrtrtmnt1PrtcltTrpOtltGasTemp "Temperature of engine combustion byproducts leaving the particulate trap exhaust in exhaust bank 1.";
CM_ BO_ 2565869822 "Aftertreatment 2 Intake Gas 1";
CM_ SG_ 2565869822 Aftrtrtmnt2IntkGsSnsrHeaterCtrl "Indicates the heater status in the warm-up process.";
CM_ SG_ 2565869822 Aftertreatment2IntakeO2 "The actual oxidation factor (%O2) of the gas within the exhaust stream.";
CM_ BO_ 2566763006 "Aftertreatment 2 Intake Gas 2";
CM_ SG_ 2566763006 Aftrtrtmnt2PrtcltTrpIntkGasTemp "Temperature of engine combustion byproducts entering the particulate trap in exhaust bank 2.";
CM_ SG_ 2566763006 Aftertreatment2ExhaustGasTemp1 "The reading from the exhaust gas temperature sensor located farthest upstream in the aftertreatment system in exhaust bank 2.";
CM_ BO_ 2565870078 "Aftertreatment 2 Outlet Gas 1";
CM_ SG_ 2565870078 Aftrtrtmnt2OtltGsSnsrHeaterCtrl "Indicates the heater status in the warm-up process.";
CM_ SG_ 2565870078 Aftertreatment2OutletO2 "The actual oxidation factor (%O2) of the gas within the exhaust stream.";
CM_ BO_ 2566762750 "Aftertreatment 2 Outlet Gas 2";
CM_ SG_ 2566762750 Aftrtrtmnt2PrtcltTrpOtltGasTemp "Temperature of engine combustion byproducts leaving the particulate trap exhaust in exhaust bank 2.";
CM_ BO_ 2566753534 "Aftertreatment 1 Gas Parameters";
CM_ BO_ 2566753278 "Aftertreatment 2 Gas Parameters";
CM_ BO_ 2566762494 "Aftertreatment 2 Intermediate Gas";
CM_ SG_ 2566762494 Aftrtrtmnt2PrtclteTrapDiffPress "Exhaust differential pressure measured between the intake and exhaust of a particulate trap in exhaust bank 2.";
CM_ BO_ 2566749182 "Aftertreatment 1 Service";
CM_ SG_ 2566749182 PrtcltTrp1TmSncLstActvRgnration "Indicates the time since the last active regeneration event of particulate trap 1.";
CM_ SG_ 2566749182 ParticulateTrap1AshLoadPercent "Indicates the ash load percent of particulate trap 1.";
CM_ SG_ 2566749182 ParticulateTrap1SootLoadPercent "Indicates the soot load percent of particulate trap 1.";
CM_ BO_ 2566748926 "Aftertreatment 2 Service";
CM_ SG_ 2566748926 PrtcltTrp2TmSncLstActvRgnration "Indicates the time since the last active regeneration event of particulate trap 2.";
CM_ SG_ 2566748926 ParticulateTrap2AshLoadPercent "Indicates the ash load percent of particulate trap 2.";
CM_ SG_ 2566748926 ParticulateTrap2SootLoadPercent "Indicates the soot load percent of particulate trap 2.";
CM_ BO_ 2566838782 "Auxiliary Input/Output Status 1";
CM_ SG_ 2566838782 AuxI_OChannel2 "Auxiliary channel of data (16 bit) read by the ECU.";
CM_ SG_ 2566838782 AuxI_OChannel1 "Auxiliary channel of data (16 bit) read by the ECU.";
CM_ BO_ 2561146622 "Auxiliary Input/Output Status 2";
CM_ SG_ 2561146622 AuxI_O45 "Identifies the current status of auxiliary input/output functions that are configured uniquely per application.";
CM_ SG_ 2561146622 AuxI_O46 "Identifies the current status of auxiliary input/output functions that are configured uniquely per application.";
CM_ SG_ 2561146622 AuxI_O47 "Identifies the current status of auxiliary input/output functions that are configured uniquely per application.";
CM_ SG_ 2561146622 AuxI_O48 "Identifies the current status of auxiliary input/output functions that are configured uniquely per application.";
CM_ SG_ 2561146622 AuxI_O41 "Identifies the current status of auxiliary input/output functions that are configured uniquely per application.";
CM_ SG_ 2561146622 AuxI_O42 "Identifies the current status of auxiliary input/output functions that are configured uniquely per application.";
CM_ SG_ 2561146622 AuxI_O43 "Identifies the current status of auxiliary input/output functions that are configured uniquely per application.";
CM_ SG_ 2561146622 AuxI_O44 "Identifies the current status of auxiliary input/output functions that are configured uniquely per application.";
CM_ SG_ 2561146622 AuxI_O37 "Identifies the current status of auxiliary input/output functions that are configured uniquely per application.";
CM_ SG_ 2561146622 AuxI_O38 "Identifies the current status of auxiliary input/output functions that are configured uniquely per application.";
CM_ SG_ 2561146622 AuxI_O39 "Identifies the current status of auxiliary input/output functions that are configured uniquely per application.";
CM_ SG_ 2561146622 AuxI_O40 "Identifies the current status of auxiliary input/output functions that are configured uniquely per application.";
CM_ SG_ 2561146622 AuxI_O33 "Identifies the current status of auxiliary input/output functions that are configured uniquely per application.";
CM_ SG_ 2561146622 AuxI_O34 "Identifies the current status of auxiliary input/output functions that are configured uniquely per application.";
CM_ SG_ 2561146622 AuxI_O35 "Identifies the current status of auxiliary input/output functions that are configured uniquely per application.";
CM_ SG_ 2561146622 AuxI_O36 "Identifies the current status of auxiliary input/output functions that are configured uniquely per application.";
CM_ SG_ 2561146622 AuxI_O29 "Identifies the current status of auxiliary input/output functions that are configured uniquely per application.";
CM_ SG_ 2561146622 AuxI_O30 "Identifies the current status of auxiliary input/output functions that are configured uniquely per application.";
CM_ SG_ 2561146622 AuxI_O31 "Identifies the current status of auxiliary input/output functions that are configured uniquely per application.";
CM_ SG_ 2561146622 AuxI_O32 "Identifies the current status of auxiliary input/output functions that are configured uniquely per application.";
CM_ SG_ 2561146622 AuxI_O25 "Identifies the current status of auxiliary input/output functions that are configured uniquely per application.";
CM_ SG_ 2561146622 AuxI_O26 "Identifies the current status of auxiliary input/output functions that are configured uniquely per application.";
CM_ SG_ 2561146622 AuxI_O27 "Identifies the current status of auxiliary input/output functions that are configured uniquely per application.";
CM_ SG_ 2561146622 AuxI_O28 "Identifies the current status of auxiliary input/output functions that are configured uniquely per application.";
CM_ SG_ 2561146622 AuxI_O21 "Identifies the current status of auxiliary input/output functions that are configured uniquely per application.";
CM_ SG_ 2561146622 AuxI_O22 "Identifies the current status of auxiliary input/output functions that are configured uniquely per application.";
CM_ SG_ 2561146622 AuxI_O23 "Identifies the current status of auxiliary input/output functions that are configured uniquely per application.";
CM_ SG_ 2561146622 AuxI_O24 "Identifies the current status of auxiliary input/output functions that are configured uniquely per application.";
CM_ SG_ 2561146622 AuxI_O17 "Identifies the current status of auxiliary input/output functions that are configured uniquely per application.";
CM_ SG_ 2561146622 AuxI_O18 "Identifies the current status of auxiliary input/output functions that are configured uniquely per application.";
CM_ SG_ 2561146622 AuxI_O19 "Identifies the current status of auxiliary input/output functions that are configured uniquely per application.";
CM_ SG_ 2561146622 AuxI_O20 "Identifies the current status of auxiliary input/output functions that are configured uniquely per application.";
CM_ BO_ 2561081086 "Auxiliary Input/Output Status 3";
CM_ SG_ 2561081086 AuxI_O77 "Identifies the current status of auxiliary input/output functions that are configured uniquely per application.";
CM_ SG_ 2561081086 AuxI_O78 "Identifies the current status of auxiliary input/output functions that are configured uniquely per application.";
CM_ SG_ 2561081086 AuxI_O79 "Identifies the current status of auxiliary input/output functions that are configured uniquely per application.";
CM_ SG_ 2561081086 AuxI_O80 "Identifies the current status of auxiliary input/output functions that are configured uniquely per application.";
CM_ SG_ 2561081086 AuxI_O73 "Identifies the current status of auxiliary input/output functions that are configured uniquely per application.";
CM_ SG_ 2561081086 AuxI_O74 "Identifies the current status of auxiliary input/output functions that are configured uniquely per application.";
CM_ SG_ 2561081086 AuxI_O75 "Identifies the current status of auxiliary input/output functions that are configured uniquely per application.";
CM_ SG_ 2561081086 AuxI_O76 "Identifies the current status of auxiliary input/output functions that are configured uniquely per application.";
CM_ SG_ 2561081086 AuxI_O69 "Identifies the current status of auxiliary input/output functions that are configured uniquely per application.";
CM_ SG_ 2561081086 AuxI_O70 "Identifies the current status of auxiliary input/output functions that are configured uniquely per application.";
CM_ SG_ 2561081086 AuxI_O71 "Identifies the current status of auxiliary input/output functions that are configured uniquely per application.";
CM_ SG_ 2561081086 AuxI_O72 "Identifies the current status of auxiliary input/output functions that are configured uniquely per application.";
CM_ SG_ 2561081086 AuxI_O65 "Identifies the current status of auxiliary input/output functions that are configured uniquely per application.";
CM_ SG_ 2561081086 AuxI_O66 "Identifies the current status of auxiliary input/output functions that are configured uniquely per application.";
CM_ SG_ 2561081086 AuxI_O67 "Identifies the current status of auxiliary input/output functions that are configured uniquely per application.";
CM_ SG_ 2561081086 AuxI_O68 "Identifies the current status of auxiliary input/output functions that are configured uniquely per application.";
CM_ SG_ 2561081086 AuxI_O61 "Identifies the current status of auxiliary input/output functions that are configured uniquely per application.";
CM_ SG_ 2561081086 AuxI_O62 "Identifies the current status of auxiliary input/output functions that are configured uniquely per application.";
CM_ SG_ 2561081086 AuxI_O63 "Identifies the current status of auxiliary input/output functions that are configured uniquely per application.";
CM_ SG_ 2561081086 AuxI_O64 "Identifies the current status of auxiliary input/output functions that are configured uniquely per application.";
CM_ SG_ 2561081086 AuxI_O57 "Identifies the current status of auxiliary input/output functions that are configured uniquely per application.";
CM_ SG_ 2561081086 AuxI_O58 "Identifies the current status of auxiliary input/output functions that are configured uniquely per application.";
CM_ SG_ 2561081086 AuxI_O59 "Identifies the current status of auxiliary input/output functions that are configured uniquely per application.";
CM_ SG_ 2561081086 AuxI_O60 "Identifies the current status of auxiliary input/output functions that are configured uniquely per application.";
CM_ SG_ 2561081086 AuxI_O53 "Identifies the current status of auxiliary input/output functions that are configured uniquely per application.";
CM_ SG_ 2561081086 AuxI_O54 "Identifies the current status of auxiliary input/output functions that are configured uniquely per application.";
CM_ SG_ 2561081086 AuxI_O55 "Identifies the current status of auxiliary input/output functions that are configured uniquely per application.";
CM_ SG_ 2561081086 AuxI_O56 "Identifies the current status of auxiliary input/output functions that are configured uniquely per application.";
CM_ SG_ 2561081086 AuxI_O49 "Identifies the current status of auxiliary input/output functions that are configured uniquely per application.";
CM_ SG_ 2561081086 AuxI_O50 "Identifies the current status of auxiliary input/output functions that are configured uniquely per application.";
CM_ SG_ 2561081086 AuxI_O51 "Identifies the current status of auxiliary input/output functions that are configured uniquely per application.";
CM_ SG_ 2561081086 AuxI_O52 "Identifies the current status of auxiliary input/output functions that are configured uniquely per application.";
CM_ BO_ 2561015550 "Auxiliary Input/Output Status 4";
CM_ SG_ 2561015550 AuxI_O92 "Identifies the current status of auxiliary input/output functions that are configured uniquely per application.";
CM_ SG_ 2561015550 AuxI_O85 "Identifies the current status of auxiliary input/output functions that are configured uniquely per application.";
CM_ SG_ 2561015550 AuxI_O86 "Identifies the current status of auxiliary input/output functions that are configured uniquely per application.";
CM_ SG_ 2561015550 AuxI_O87 "Identifies the current status of auxiliary input/output functions that are configured uniquely per application.";
CM_ SG_ 2561015550 AuxI_O88 "Identifies the current status of auxiliary input/output functions that are configured uniquely per application.";
CM_ SG_ 2561015550 AuxI_O81 "Identifies the current status of auxiliary input/output functions that are configured uniquely per application.";
CM_ SG_ 2561015550 AuxI_O82 "Identifies the current status of auxiliary input/output functions that are configured uniquely per application.";
CM_ SG_ 2561015550 AuxI_O83 "Identifies the current status of auxiliary input/output functions that are configured uniquely per application.";
CM_ SG_ 2561015550 AuxI_O84 "Identifies the current status of auxiliary input/output functions that are configured uniquely per application.";
CM_ SG_ 2561015550 AuxI_O109 "Identifies the current status of auxiliary input/output functions that are configured uniquely per application.";
CM_ SG_ 2561015550 AuxI_O110 "Identifies the current status of auxiliary input/output functions that are configured uniquely per application.";
CM_ SG_ 2561015550 AuxI_O111 "Identifies the current status of auxiliary input/output functions that are configured uniquely per application.";
CM_ SG_ 2561015550 AuxI_O112 "Identifies the current status of auxiliary input/output functions that are configured uniquely per application.";
CM_ SG_ 2561015550 AuxI_O105 "Identifies the current status of auxiliary input/output functions that are configured uniquely per application.";
CM_ SG_ 2561015550 AuxI_O106 "Identifies the current status of auxiliary input/output functions that are configured uniquely per application.";
CM_ SG_ 2561015550 AuxI_O107 "Identifies the current status of auxiliary input/output functions that are configured uniquely per application.";
CM_ SG_ 2561015550 AuxI_O108 "Identifies the current status of auxiliary input/output functions that are configured uniquely per application.";
CM_ SG_ 2561015550 AuxI_O101 "Identifies the current status of auxiliary input/output functions that are configured uniquely per application.";
CM_ SG_ 2561015550 AuxI_O102 "Identifies the current status of auxiliary input/output functions that are configured uniquely per application.";
CM_ SG_ 2561015550 AuxI_O103 "Identifies the current status of auxiliary input/output functions that are configured uniquely per application.";
CM_ SG_ 2561015550 AuxI_O104 "Identifies the current status of auxiliary input/output functions that are configured uniquely per application.";
CM_ SG_ 2561015550 AuxI_O97 "Identifies the current status of auxiliary input/output functions that are configured uniquely per application.";
CM_ SG_ 2561015550 AuxI_O98 "Identifies the current status of auxiliary input/output functions that are configured uniquely per application.";
CM_ SG_ 2561015550 AuxI_O99 "Identifies the current status of auxiliary input/output functions that are configured uniquely per application.";
CM_ SG_ 2561015550 AuxI_O100 "Identifies the current status of auxiliary input/output functions that are configured uniquely per application.";
CM_ SG_ 2561015550 AuxI_O93 "Identifies the current status of auxiliary input/output functions that are configured uniquely per application.";
CM_ SG_ 2561015550 AuxI_O94 "Identifies the current status of auxiliary input/output functions that are configured uniquely per application.";
CM_ SG_ 2561015550 AuxI_O95 "Identifies the current status of auxiliary input/output functions that are configured uniquely per application.";
CM_ SG_ 2561015550 AuxI_O96 "Identifies the current status of auxiliary input/output functions that are configured uniquely per application.";
CM_ SG_ 2561015550 AuxI_O89 "Identifies the current status of auxiliary input/output functions that are configured uniquely per application.";
CM_ SG_ 2561015550 AuxI_O90 "Identifies the current status of auxiliary input/output functions that are configured uniquely per application.";
CM_ SG_ 2561015550 AuxI_O91 "Identifies the current status of auxiliary input/output functions that are configured uniquely per application.";
CM_ BO_ 2566746622 "Brake actuator stroke status";
CM_ SG_ 2566746622 TrailerBrakeStrokeAxle5Right "Brake stroke status for right brake actuator on trailer axle 5.";
CM_ SG_ 2566746622 TrailerBrakeStrokeAxle5Left "Brake stroke status for left brake actuator on trailer axle 5.";
CM_ SG_ 2566746622 TrailerBrakeStrokeAxle4Right "Brake stroke status for right brake actuator on trailer axle 4.";
CM_ SG_ 2566746622 TrailerBrakeStrokeAxle4Left "Brake stroke status for left brake actuator on trailer axle 4.";
CM_ SG_ 2566746622 TrailerBrakeStrokeAxle3Right "Brake stroke status for right brake actuator on trailer axle 3.";
CM_ SG_ 2566746622 TrailerBrakeStrokeAxle3Left "Brake stroke status for left brake actuator on trailer axle 3.";
CM_ SG_ 2566746622 TrailerBrakeStrokeAxle2Right "Brake stroke status for right brake actuator on trailer axle 2.";
CM_ SG_ 2566746622 TrailerBrakeStrokeAxle2Left "Brake stroke status for left brake actuator on trailer axle 2.";
CM_ SG_ 2566746622 TrailerBrakeStrokeAxle1Right "Brake stroke status for right brake actuator on trailer axle 1.";
CM_ SG_ 2566746622 TrailerBrakeStrokeAxle1Left "Brake stroke status for left brake actuator on trailerr axle 1.";
CM_ SG_ 2566746622 TractorBrakeStrokeAxle5Right "Brake stroke status for right brake actuator on tractor axle 5.";
CM_ SG_ 2566746622 TractorBrakeStrokeAxle5Left "Brake stroke status for left brake actuator on tractor axle 5.";
CM_ SG_ 2566746622 TractorBrakeStrokeAxle4Right "Brake stroke status for right brake actuator on tractor axle 4.";
CM_ SG_ 2566746622 TractorBrakeStrokeAxle4Left "Brake stroke status for left brake actuator on tractor axle 4.";
CM_ SG_ 2566746622 TractorBrakeStrokeAxle3Right "Brake stroke status for right brake actuator on tractor axle 3.";
CM_ SG_ 2566746622 TractorBrakeStrokeAxle3Left "Brake stroke status for left brake actuator on tractor axle 3.";
CM_ SG_ 2566746622 TractorBrakeStrokeAxle2Right "Brake stroke status for right brake actuator on tractor axle 2.";
CM_ SG_ 2566746622 TractorBrakeStrokeAxle2Left "Brake stroke status for left brake actuator on tractor axle 2.";
CM_ SG_ 2566746622 TractorBrakeStrokeAxle1Right "Brake stroke status for right brake actuator on tractor axle 1.";
CM_ SG_ 2566746622 TractorBrakeStrokeAxle1Left "Brake stroke status for left brake actuator on tractor axle 1.";
CM_ BO_ 2566845950 "Ambient Conditions";
CM_ SG_ 2566845950 RoadSurfaceTemp "Indicated temperature of road surface over which vehicle is operating.";
CM_ SG_ 2566845950 EngAirInletTemp "Temperature of air entering vehicle air induction system.";
CM_ SG_ 2566845950 AmbientAirTemp "Temperature of air surrounding vehicle.";
CM_ SG_ 2566845950 CabInteriorTemp "Temperature of air inside the part of the vehicle that encloses the driver and vehicle operating controls.";
CM_ SG_ 2566845950 BarometricPress "Absolute air pressure of the atmosphere.";
CM_ BO_ 2566840062 "Air Start Pressure";
CM_ BO_ 2566827774 "Air Supply Pressure";
CM_ SG_ 2566827774 AirCompressorStatus "Indicates whether the air compressor is actively compressing air.";
CM_ SG_ 2566827774 AirSuspensionSupplyPress "The pneumatic pressure in the circuit for the electronically controlled air suspension system.";
CM_ SG_ 2566827774 AuxEquipmentSupplyPress "The pneumatic pressure in the auxiliary circuit.";
CM_ SG_ 2566827774 ServiceBrakeAirPressCircuit2 "The pneumatic pressure in the service brake circuit or reservoir #2.";
CM_ SG_ 2566827774 ServiceBrakeAirPressCircuit1 "The pneumatic pressure in the service brake circuit or reservoir #1.";
CM_ SG_ 2566827774 ParkingAnd_OrTrailerAirPress "The pneumatic pressure in the circuit or reservoir for the parking brake and/or the trailer supply.";
CM_ SG_ 2566827774 PneumaticSupplyPress "The pneumatic pressure in the main reservoir, sometimes referred to as the wet tank.";
CM_ BO_ 2566846974 "Axle Information";
CM_ SG_ 2566846974 SteerAxleLubePress "The steering axle lubricant pressure.";
CM_ SG_ 2566846974 SteerAxleTemp "Temperature of lubricant in steering axle.";
CM_ SG_ 2566846974 DriveAxleLubePress "The drive axle lubricant pressure with location determined by Drive Axle Location (SPN 930).";
CM_ SG_ 2566846974 DriveAxleTemp "Temperature of axle lubricant in drive axle.";
CM_ SG_ 2566846974 DriveAxleLiftAirPress "Gage pressure of air in system that utilizes compressed air to provide force between axle and frame.";
CM_ SG_ 2566846974 DriveAxleLocation "To identify to which of several similar devices (such as tires or fuel tanks) the information applies.";
CM_ BO_ 2633935614 "Alternate Fuel 2";
CM_ SG_ 2633935614 EngTurboWastegateValvePos "The position of the turbocharger wastegate valve (not the electronic wastegate control valve).";
CM_ SG_ 2633935614 EngDsiredAbsIntakeManifoldPress "The desired absolute intake manifold pressure of the engine.";
CM_ SG_ 2633935614 EngGasFuelCorrectionFactor "A correction to a predefined gaseous fuel energy (expressed in energy per unit volume) represented as a percentage.";
CM_ BO_ 2566803966 "Adaptive Cruise Control, Operator Input";
CM_ SG_ 2566803966 RqedACCDistanceMode "The Requested Distance Control Mode to the ACC system from the operators interface.";
CM_ BO_ 2432593918 "Adaptive Cruise Control";
CM_ SG_ 2432593918 ACCDistanceAlertSignal "Signal to indicate to the operator that the ACC system is not able to maintain the distance to the target.";
CM_ SG_ 2432593918 ACCSystemShutoffWarning "Signal to warn the driver of system deactivation due to non-driver actions.";
CM_ SG_ 2432593918 ACCTargetDetected "Signal to indicate to the driver that the ACC system has detected a target.";
CM_ SG_ 2432593918 RoadCurvature "Estimated value of the current road curvature for use by the adaptive cruise control system.";
CM_ SG_ 2432593918 AdptveCruiseCtrlSetDistanceMode "Selected distance mode for adaptive cruise control.";
CM_ SG_ 2432593918 AdaptiveCruiseCtrlMode "This parameter is used to indicate the current state, or mode, of operation by the Adaptive Cruise Control (ACC) device.";
CM_ SG_ 2432593918 AdaptiveCruiseCtrlSetSpeed "Value of the desired (chosen) velocity of the adaptive cruise control system.";
CM_ SG_ 2432593918 DistanceToForwardVehicle "Distance to the preceding vehicle situated within 250 m in the same lane and moving in the same direction.";
CM_ SG_ 2432593918 SpeedOfForwardVehicle "Absolute velocity of the preceding vehicle situated within 250 m in the same lane and moving in the same direction.";
CM_ BO_ 2633935102 "Articulation Control";
CM_ SG_ 2633935102 ArticulationAngle "Angle of deflection of an articulated transit vehicle.";
CM_ BO_ 2633927934 "Auxiliary Analog Information";
CM_ SG_ 2633927934 AuxLevel "Level measured by a sensor.";
CM_ SG_ 2633927934 AuxPress2 "Pressure measured by auxiliary pressure sensor #2.";
CM_ SG_ 2633927934 AuxPress1 "Pressure measured by auxiliary pressure sensor #1.";
CM_ SG_ 2633927934 AuxTemp2 "Temperature measured by auxiliary temperature sensor #2.";
CM_ SG_ 2633927934 AuxTemp1 "Temperature measured by auxiliary temperature sensor #1.";
CM_ BO_ 2566847998 "Alternate Fuel 1";
CM_ SG_ 2566847998 EngBlowerBypassValvePos "Relative position of the blower bypass valve.";
CM_ SG_ 2566847998 EngGasSupplyPress "Gage pressure of gas supply to fuel metering device.";
CM_ BO_ 2565406462 "Acknowledgment Message";
CM_ SG_ 2565406462 ParameterGroupNumber "PGN which is requested by Request2 message";
CM_ SG_ 2565406462 GroupFunctionValue "Group Function of PGN being acknowledged. This field identifies for a device the specific group function of a PGN being acknowledged or declined.  This field is not used if the PGN being acknowledged or declined is not a group function PGN.";
CM_ BO_ 2566763262 "After Treatment Intermediate Gas 1";
CM_ SG_ 2566763262 ParticulateTrapDiffPress "Exhaust differential pressure measured between the intake and exhaust of a particulate trap.";
CM_ SG_ 2566763262 PrtclateTrapIntermediateGasTemp "Temperature of engine combustion byproducts at a mid-point in the particulate trap.";
CM_ BO_ 2566803198 "Door Control 1";
CM_ SG_ 2566803198 Status2OfDoors "Composite indication of all bus door statuses.";
CM_ SG_ 2566803198 Ramp_WheelChairLiftPos "Signal which indicates the actual position of the ramp / wheel chair lift.";
CM_ SG_ 2566803198 PosOfDoors "Signal which indicates the actual position of the doors.";
CM_ BO_ 2565870334 "Fifth Wheel Smart Systems 1";
CM_ SG_ 2565870334 FifthWheelRollWarningIndicator "Indicates to the vehicle operator that the roll moment has exceeded a preset limit.";
CM_ SG_ 2565870334 FifthWheelRollMoment "Fifth wheel roll moment force.";
CM_ SG_ 2565870334 FifthWheelDrawbarForce "Fifth wheel drawbar force.";
CM_ SG_ 2565870334 FifthWheelVerticalForce "Fifth wheel vertical force.";
CM_ BO_ 2566762238 "Fifth Wheel Smart Systems 2";
CM_ SG_ 2566762238 FifthWheelSliderLockIndicator "Indicates to vehicle operator that the fifth wheel slider is in position and locked.";
CM_ SG_ 2566762238 FifthWheelSliderPos "Slider position measurement.";
CM_ SG_ 2566762238 FfthWhlLckCoupleStatusIndicator "Indicates results of coupling operation to the vehicle operator.";
CM_ SG_ 2566762238 FfthWhlLckRadyToCoupleIndicator "Indicates to the vehicle operator that the fifth wheel lock is open and ready to couple.";
CM_ SG_ 2566762238 FifthWheelErrorStatus "Fifth wheel error state conveys information when coupling status is incomplete or bad.";
CM_ BO_ 2364543998 "Slope Sensor Information";
CM_ SG_ 2364543998 RollAndPitchMeasurementLatency "The estimated measurement latency of the measurement.";
CM_ SG_ 2364543998 PitchAndRollCompensated "Compensated mode for the pitch and roll measurements.";
CM_ SG_ 2364543998 PitchRateFigureOfMerit "Figure of merit for the pitch rate measurement.";
CM_ SG_ 2364543998 RollAngleFigureOfMerit "Figure of merit for roll angle measurement.";
CM_ SG_ 2364543998 PitchAngleFigureOfMerit "Figure of merit for pitch angle measurement.";
CM_ SG_ 2364543998 RollAngle "The angle between the vehicle y-axis and the ground plane.";
CM_ SG_ 2364543998 PitchAngle "The angle between the vehicle x-axis and the ground plane.";
CM_ BO_ 2566846718 "Transmission Fluids 1";
CM_ SG_ 2566846718 TransOilLevelHigh_Low "Amount of current volume of transmission sump oil compared to recommended volume.";
CM_ SG_ 2566846718 TransOilTemp "Temperature of the transmission lubricant.";
CM_ SG_ 2566846718 TransOilPress "Gage pressure of lubrication fluid in transmission, measured after pump.";
CM_ SG_ 2566846718 TransOilLevel "Ratio of volume of transmission sump oil to recommended volume.";
CM_ SG_ 2566846718 ClutchPress "Gage pressure of oil within a wet clutch.";
CM_ BO_ 2566846462 "Vehicle Electrical Power #1";
CM_ SG_ 2566846462 BatteryPotentialSwitched "Electrical potential measured at the input of the electronic control unit supplied through a switching device.";
CM_ SG_ 2566846462 ElectricalPotential "Measured electrical potential of the battery.";
CM_ SG_ 2566846462 ChargingSystemPotential "Electrical potential measured at the charging system output.";
CM_ SG_ 2566846462 AltCurrent "Measure of electrical current flow from the alternator.";
CM_ SG_ 2566846462 NetBatteryCurrent "Net flow of electrical current into/out of the battery or batteries.";
CM_ BO_ 2566760702 "Wireless Communications Message 2";
CM_ SG_ 2566760702 NetworkSignalStrength2 "Indicates the signal strength for the wireless communications network type.";
CM_ BO_ 2566760958 "Wireless Communications Message 1";
CM_ SG_ 2566760958 NetworkSignalStrength1 "Indicates the signal strength for the wireless communications network type.";
CM_ BO_ 2633869310 "Voltage Regulator Operating Mode";
CM_ SG_ 2633869310 VoltageRegulatorEnabled "State signal indicating the Voltage regulator enabled.";
CM_ SG_ 2633869310 VoltageRegulatorSoftStartState "State signal indicating the mode of the Voltage regulator soft start function.";
CM_ SG_ 2633869310 VltgRgltrUndrfrqncyCmpnstnEnbld "State signal indicating the operating mode for underfrequency compensation.";
CM_ SG_ 2633869310 VltgRglatorLoadCompensationMode "State signal indicating the voltage regulator load compensation mode.";
CM_ BO_ 2365433598 "Voltage regulator excitation status";
CM_ SG_ 2365433598 GeneratorExcitationFieldCurrent "Measured signal that represents the generator excitation field current.";
CM_ SG_ 2365433598 GeneratorExcitationFieldVoltage "Measured signal that represents the generator excitation field voltage.";
BA_DEF_ SG_  "GenSigSendType" ENUM  "Cyclic","OnWrite","reserved","OnChange","reserved","reserved","reserved","NoSigSendType";
BA_DEF_ SG_  "GenSigILSupport" ENUM  "Yes","No";
BA_DEF_ SG_  "GenSigEVName" STRING ;
BA_DEF_ SG_  "SigType" STRING ;
BA_DEF_ SG_  "SPN" INT 0 524287;
BA_DEF_ BO_  "GenMsgILSupport" ENUM  "Yes","No";
BA_DEF_ BO_  "GenMsgRequestable" INT 0 1;
BA_DEF_ BO_  "GenMsgSendType" ENUM  "cyclic","reserved","cyclicIfActive","reserved","reserved","reserved","reserved","reserved","noMsgSendType";
BA_DEF_ BO_  "VFrameFormat" ENUM  "StandardCAN","ExtendedCAN","reserved","J1939PG";
BA_DEF_ BO_  "SingleFrame" INT 0 1;
BA_DEF_ BO_  "GenMsgCycleTime" INT 0 3600000;
BA_DEF_DEF_  "GenSigSendType" "NoSigSendType";
BA_DEF_DEF_  "GenSigILSupport" "Yes";
BA_DEF_DEF_  "GenSigEVName" "Env@Nodename_@Signame";
BA_DEF_DEF_  "SigType" "";
BA_DEF_DEF_  "SPN" 0;
BA_DEF_DEF_  "GenMsgILSupport" "Yes";
BA_DEF_DEF_  "GenMsgRequestable" 1;
BA_DEF_DEF_  "GenMsgSendType" "noMsgSendType";
BA_DEF_DEF_  "VFrameFormat" "J1939PG";
BA_DEF_DEF_  "SingleFrame" 1;
BA_DEF_DEF_  "GenMsgCycleTime" 0;
BA_ "GenMsgCycleTime" BO_ 2566745598 500;
BA_ "GenMsgSendType" BO_ 2566745598 0;
BA_ "GenMsgCycleTime" BO_ 2566745342 500;
BA_ "GenMsgSendType" BO_ 2566745342 0;
BA_ "GenMsgCycleTime" BO_ 2565869310 50;
BA_ "GenMsgSendType" BO_ 2565869310 0;
BA_ "GenMsgCycleTime" BO_ 2566763774 500;
BA_ "GenMsgSendType" BO_ 2566763774 0;
BA_ "GenMsgCycleTime" BO_ 2565869566 50;
BA_ "GenMsgSendType" BO_ 2565869566 0;
BA_ "GenMsgCycleTime" BO_ 2566763518 500;
BA_ "GenMsgSendType" BO_ 2566763518 0;
BA_ "GenMsgCycleTime" BO_ 2565869822 50;
BA_ "GenMsgSendType" BO_ 2565869822 0;
BA_ "GenMsgCycleTime" BO_ 2566763006 500;
BA_ "GenMsgSendType" BO_ 2566763006 0;
BA_ "GenMsgCycleTime" BO_ 2565870078 50;
BA_ "GenMsgSendType" BO_ 2565870078 0;
BA_ "GenMsgCycleTime" BO_ 2566762750 500;
BA_ "GenMsgSendType" BO_ 2566762750 0;
BA_ "GenMsgCycleTime" BO_ 2566753534 500;
BA_ "GenMsgSendType" BO_ 2566753534 0;
BA_ "GenMsgCycleTime" BO_ 2566753278 500;
BA_ "GenMsgSendType" BO_ 2566753278 0;
BA_ "GenMsgCycleTime" BO_ 2566762494 500;
BA_ "GenMsgSendType" BO_ 2566762494 0;
BA_ "GenMsgCycleTime" BO_ 2566746622 1000;
BA_ "GenMsgSendType" BO_ 2566746622 0;
BA_ "GenMsgCycleTime" BO_ 2566845950 1000;
BA_ "GenMsgSendType" BO_ 2566845950 0;
BA_ "GenMsgCycleTime" BO_ 2566827774 1000;
BA_ "GenMsgSendType" BO_ 2566827774 0;
BA_ "GenMsgCycleTime" BO_ 2566846974 1000;
BA_ "GenMsgSendType" BO_ 2566846974 0;
BA_ "GenMsgCycleTime" BO_ 2566803966 250;
BA_ "GenMsgSendType" BO_ 2566803966 0;
BA_ "GenMsgCycleTime" BO_ 2432593918 100;
BA_ "GenMsgSendType" BO_ 2432593918 0;
BA_ "GenMsgCycleTime" BO_ 2566847998 500;
BA_ "GenMsgSendType" BO_ 2566847998 0;
BA_ "GenMsgCycleTime" BO_ 2566763262 500;
BA_ "GenMsgSendType" BO_ 2566763262 0;
BA_ "GenMsgCycleTime" BO_ 2566803198 100;
BA_ "GenMsgSendType" BO_ 2566803198 0;
BA_ "GenMsgCycleTime" BO_ 2565870334 50;
BA_ "GenMsgSendType" BO_ 2565870334 0;
BA_ "GenMsgCycleTime" BO_ 2364543998 10;
BA_ "GenMsgSendType" BO_ 2364543998 0;
BA_ "GenMsgCycleTime" BO_ 2566846718 1000;
BA_ "GenMsgSendType" BO_ 2566846718 0;
BA_ "GenMsgCycleTime" BO_ 2566846462 1000;
BA_ "GenMsgSendType" BO_ 2566846462 0;
BA_ "GenMsgCycleTime" BO_ 2633869310 1000;
BA_ "GenMsgSendType" BO_ 2633869310 0;
BA_ "GenMsgCycleTime" BO_ 2365433598 100;
BA_ "GenMsgSendType" BO_ 2365433598 0;
BA_ "SPN" SG_ 2566781694 GeneratorTotalKWHoursImport 2469;
BA_ "SigType" SG_ 2566781694 GeneratorTotalKWHoursImport "DISCRETE";
BA_ "SPN" SG_ 2566781694 GeneratorTotalKWHoursExport 2468;
BA_ "SigType" SG_ 2566781694 GeneratorTotalKWHoursExport "DISCRETE";
BA_ "SPN" SG_ 2566781950 GnratorPhaseCPowerFactorLagging 2521;
BA_ "SigType" SG_ 2566781950 GnratorPhaseCPowerFactorLagging "DISCRETE";
BA_ "SPN" SG_ 2566781950 GeneratorPhaseCPowerFactor 2467;
BA_ "SigType" SG_ 2566781950 GeneratorPhaseCPowerFactor "RANGE";
BA_ "SPN" SG_ 2566781950 GeneratorPhaseCReactivePower 2459;
BA_ "SigType" SG_ 2566781950 GeneratorPhaseCReactivePower "RANGE";
BA_ "SPN" SG_ 2566782206 GeneratorPhaseCApparentPower 2463;
BA_ "SigType" SG_ 2566782206 GeneratorPhaseCApparentPower "RANGE";
BA_ "SPN" SG_ 2566782206 GeneratorPhaseCRealPower 2455;
BA_ "SigType" SG_ 2566782206 GeneratorPhaseCRealPower "RANGE";
BA_ "SPN" SG_ 2566782462 GeneratorPhaseCACRMSCurrent 2451;
BA_ "SigType" SG_ 2566782462 GeneratorPhaseCACRMSCurrent "RANGE";
BA_ "SPN" SG_ 2566782462 GeneratorPhaseCACFrequency 2439;
BA_ "SigType" SG_ 2566782462 GeneratorPhaseCACFrequency "RANGE";
BA_ "SPN" SG_ 2566782462 GnrtrPhsCLneNeutralACRMSVoltage 2447;
BA_ "SigType" SG_ 2566782462 GnrtrPhsCLneNeutralACRMSVoltage "RANGE";
BA_ "SPN" SG_ 2566782462 GnrtrPhseCALineLineACRMSVoltage 2443;
BA_ "SigType" SG_ 2566782462 GnrtrPhseCALineLineACRMSVoltage "RANGE";
BA_ "SPN" SG_ 2566782718 GnratorPhaseBPowerFactorLagging 2520;
BA_ "SigType" SG_ 2566782718 GnratorPhaseBPowerFactorLagging "DISCRETE";
BA_ "SPN" SG_ 2566782718 GeneratorPhaseBPowerFactor 2466;
BA_ "SigType" SG_ 2566782718 GeneratorPhaseBPowerFactor "RANGE";
BA_ "SPN" SG_ 2566782718 GeneratorPhaseBReactivePower 2458;
BA_ "SigType" SG_ 2566782718 GeneratorPhaseBReactivePower "RANGE";
BA_ "SPN" SG_ 2566782974 GeneratorPhaseBApparentPower 2462;
BA_ "SigType" SG_ 2566782974 GeneratorPhaseBApparentPower "RANGE";
BA_ "SPN" SG_ 2566782974 GeneratorPhaseBRealPower 2454;
BA_ "SigType" SG_ 2566782974 GeneratorPhaseBRealPower "RANGE";
BA_ "SPN" SG_ 2566783230 GeneratorPhaseBACRMSCurrent 2450;
BA_ "SigType" SG_ 2566783230 GeneratorPhaseBACRMSCurrent "RANGE";
BA_ "SPN" SG_ 2566783230 GeneratorPhaseBACFrequency 2438;
BA_ "SigType" SG_ 2566783230 GeneratorPhaseBACFrequency "RANGE";
BA_ "SPN" SG_ 2566783230 GnrtrPhsBLneNeutralACRMSVoltage 2446;
BA_ "SigType" SG_ 2566783230 GnrtrPhsBLneNeutralACRMSVoltage "RANGE";
BA_ "SPN" SG_ 2566783230 GnrtrPhseBCLineLineACRMSVoltage 2442;
BA_ "SigType" SG_ 2566783230 GnrtrPhseBCLineLineACRMSVoltage "RANGE";
BA_ "SPN" SG_ 2566783486 GnratorPhaseAPowerFactorLagging 2519;
BA_ "SigType" SG_ 2566783486 GnratorPhaseAPowerFactorLagging "DISCRETE";
BA_ "SPN" SG_ 2566783486 GeneratorPhaseAPowerFactor 2465;
BA_ "SigType" SG_ 2566783486 GeneratorPhaseAPowerFactor "RANGE";
BA_ "SPN" SG_ 2566783486 GeneratorPhaseAReactivePower 2457;
BA_ "SigType" SG_ 2566783486 GeneratorPhaseAReactivePower "RANGE";
BA_ "SPN" SG_ 2566783742 GeneratorPhaseAApparentPower 2461;
BA_ "SigType" SG_ 2566783742 GeneratorPhaseAApparentPower "RANGE";
BA_ "SPN" SG_ 2566783742 GeneratorPhaseARealPower 2453;
BA_ "SigType" SG_ 2566783742 GeneratorPhaseARealPower "RANGE";
BA_ "SPN" SG_ 2566783998 GeneratorPhaseAACRMSCurrent 2449;
BA_ "SigType" SG_ 2566783998 GeneratorPhaseAACRMSCurrent "RANGE";
BA_ "SPN" SG_ 2566783998 GeneratorPhaseAACFrequency 2437;
BA_ "SigType" SG_ 2566783998 GeneratorPhaseAACFrequency "RANGE";
BA_ "SPN" SG_ 2566783998 GnrtrPhsALneNeutralACRMSVoltage 2445;
BA_ "SigType" SG_ 2566783998 GnrtrPhsALneNeutralACRMSVoltage "RANGE";
BA_ "SPN" SG_ 2566783998 GnrtrPhseABLineLineACRMSVoltage 2441;
BA_ "SigType" SG_ 2566783998 GnrtrPhseABLineLineACRMSVoltage "RANGE";
BA_ "SPN" SG_ 2566784766 GeneratorAverageACRMSCurrent 2448;
BA_ "SigType" SG_ 2566784766 GeneratorAverageACRMSCurrent "RANGE";
BA_ "SPN" SG_ 2566784766 GeneratorAverageACFrequency 2436;
BA_ "SigType" SG_ 2566784766 GeneratorAverageACFrequency "RANGE";
BA_ "SPN" SG_ 2566784766 GnrtrAvrgLneNeutralACRMSVoltage 2444;
BA_ "SigType" SG_ 2566784766 GnrtrAvrgLneNeutralACRMSVoltage "RANGE";
BA_ "SPN" SG_ 2566784766 GnrtrAvrageLineLineACRMSVoltage 2440;
BA_ "SigType" SG_ 2566784766 GnrtrAvrageLineLineACRMSVoltage "RANGE";
BA_ "SPN" SG_ 2566776830 Bus1_UtilityACPhaseDifference 2517;
BA_ "SigType" SG_ 2566776830 Bus1_UtilityACPhaseDifference "RANGE";
BA_ "SPN" SG_ 2566776830 Bus1_UtilityInSync 2534;
BA_ "SigType" SG_ 2566776830 Bus1_UtilityInSync "DISCRETE";
BA_ "SPN" SG_ 2566776830 Bus1_UtilityVoltageMatch 2532;
BA_ "SigType" SG_ 2566776830 Bus1_UtilityVoltageMatch "DISCRETE";
BA_ "SPN" SG_ 2566776830 Bus1_UtilityFrequencyMatch 2533;
BA_ "SigType" SG_ 2566776830 Bus1_UtilityFrequencyMatch "DISCRETE";
BA_ "SPN" SG_ 2566776830 Bus1_UtilityPhaseMatch 2531;
BA_ "SigType" SG_ 2566776830 Bus1_UtilityPhaseMatch "DISCRETE";
BA_ "SPN" SG_ 2566776830 Bus1_UtilityDeadBus 2535;
BA_ "SigType" SG_ 2566776830 Bus1_UtilityDeadBus "DISCRETE";
BA_ "SPN" SG_ 2566777342 Bus1PhaseCACFrequency 2507;
BA_ "SigType" SG_ 2566777342 Bus1PhaseCACFrequency "RANGE";
BA_ "SPN" SG_ 2566777342 Bs1PhseCLineNeutralACRMSVoltage 2515;
BA_ "SigType" SG_ 2566777342 Bs1PhseCLineNeutralACRMSVoltage "RANGE";
BA_ "SPN" SG_ 2566777342 Bus1PhaseCALineLineACRMSVoltage 2511;
BA_ "SigType" SG_ 2566777342 Bus1PhaseCALineLineACRMSVoltage "RANGE";
BA_ "SPN" SG_ 2566777598 Bus1PhaseBACFrequency 2506;
BA_ "SigType" SG_ 2566777598 Bus1PhaseBACFrequency "RANGE";
BA_ "SPN" SG_ 2566777598 Bs1PhseBLineNeutralACRMSVoltage 2514;
BA_ "SigType" SG_ 2566777598 Bs1PhseBLineNeutralACRMSVoltage "RANGE";
BA_ "SPN" SG_ 2566777598 Bus1PhaseBCLineLineACRMSVoltage 2510;
BA_ "SigType" SG_ 2566777598 Bus1PhaseBCLineLineACRMSVoltage "RANGE";
BA_ "SPN" SG_ 2566777854 Bus1PhaseAACFrequency 2505;
BA_ "SigType" SG_ 2566777854 Bus1PhaseAACFrequency "RANGE";
BA_ "SPN" SG_ 2566777854 Bs1PhseALineNeutralACRMSVoltage 2513;
BA_ "SigType" SG_ 2566777854 Bs1PhseALineNeutralACRMSVoltage "RANGE";
BA_ "SPN" SG_ 2566777854 Bus1PhaseABLineLineACRMSVoltage 2509;
BA_ "SigType" SG_ 2566777854 Bus1PhaseABLineLineACRMSVoltage "RANGE";
BA_ "SPN" SG_ 2566777086 Bus1_GeneratorACPhaseDifference 2516;
BA_ "SigType" SG_ 2566777086 Bus1_GeneratorACPhaseDifference "RANGE";
BA_ "SPN" SG_ 2566777086 Bus1_GeneratorInSync 2529;
BA_ "SigType" SG_ 2566777086 Bus1_GeneratorInSync "DISCRETE";
BA_ "SPN" SG_ 2566777086 Bus1_GeneratorVoltageMatch 2527;
BA_ "SigType" SG_ 2566777086 Bus1_GeneratorVoltageMatch "DISCRETE";
BA_ "SPN" SG_ 2566777086 Bus1_GeneratorFrequencyMatch 2528;
BA_ "SigType" SG_ 2566777086 Bus1_GeneratorFrequencyMatch "DISCRETE";
BA_ "SPN" SG_ 2566777086 Bus1_GeneratorPhaseMatch 2526;
BA_ "SigType" SG_ 2566777086 Bus1_GeneratorPhaseMatch "DISCRETE";
BA_ "SPN" SG_ 2566777086 Bus1_GeneratorDeadBus 2530;
BA_ "SigType" SG_ 2566777086 Bus1_GeneratorDeadBus "DISCRETE";
BA_ "SPN" SG_ 2566778110 Bus1AverageACFrequency 2504;
BA_ "SigType" SG_ 2566778110 Bus1AverageACFrequency "RANGE";
BA_ "SPN" SG_ 2566778110 Bs1AvrgeLineNeutralACRMSVoltage 2512;
BA_ "SigType" SG_ 2566778110 Bs1AvrgeLineNeutralACRMSVoltage "RANGE";
BA_ "SPN" SG_ 2566778110 Bus1AverageLineLineACRMSVoltage 2508;
BA_ "SigType" SG_ 2566778110 Bus1AverageLineLineACRMSVoltage "RANGE";
BA_ "SigType" SG_ 2633895422 NumberOfMembers "ASCII";
BA_ "SigType" SG_ 2566838526 IndustryGroup "DISCRETE";
BA_ "SigType" SG_ 2566838526 ManufacturerCode "RANGE";
BA_ "SPN" SG_ 2566838526 AddressAssignment 2847;
BA_ "SigType" SG_ 2566838526 AddressAssignment "RANGE";
BA_ "SigType" SG_ 2565799678 IndustryGroup "DISCRETE";
BA_ "SigType" SG_ 2565799678 ManufacturerCode "RANGE";
BA_ "SPN" SG_ 2563440382 ShrtNameOfActualReportingDevice 2554;
BA_ "SigType" SG_ 2563440382 ShrtNameOfActualReportingDevice "DISCRETE";
BA_ "SPN" SG_ 2563440382 LengthOfDataForTheReportedPGN 2553;
BA_ "SigType" SG_ 2563440382 LengthOfDataForTheReportedPGN "RANGE";
BA_ "SPN" SG_ 2563440382 PGNofRequstedInformation 2552;
BA_ "SigType" SG_ 2563440382 PGNofRequstedInformation "RANGE";
BA_ "SPN" SG_ 2565603070 SequenceNumber 2572;
BA_ "SigType" SG_ 2565603070 SequenceNumber "RANGE";
BA_ "SPN" SG_ 2565668606 TotalNumberOfPacketsEoMA 2558;
BA_ "SigType" SG_ 2565668606 TotalNumberOfPacketsEoMA "RANGE";
BA_ "SPN" SG_ 2565668606 TotalMessageSizeEoMA 2557;
BA_ "SigType" SG_ 2565668606 TotalMessageSizeEoMA "RANGE";
BA_ "SPN" SG_ 2565668606 TotalMessageSizeBAM 2557;
BA_ "SigType" SG_ 2565668606 TotalMessageSizeBAM "RANGE";
BA_ "SPN" SG_ 2565668606 TotalNumberOfPacketsBAM 2558;
BA_ "SigType" SG_ 2565668606 TotalNumberOfPacketsBAM "RANGE";
BA_ "SPN" SG_ 2565668606 ConnectionAbortReason 2570;
BA_ "SigType" SG_ 2565668606 ConnectionAbortReason "RANGE";
BA_ "SPN" SG_ 2565668606 NextPacketNumberToBeSent 2562;
BA_ "SigType" SG_ 2565668606 NextPacketNumberToBeSent "RANGE";
BA_ "SPN" SG_ 2565668606 NumberOfPacketsThatCanBeSent 2561;
BA_ "SigType" SG_ 2565668606 NumberOfPacketsThatCanBeSent "RANGE";
BA_ "SPN" SG_ 2565668606 PGNumber 2560;
BA_ "SPN" SG_ 2565668606 MaximumNumberOfPackets 2559;
BA_ "SigType" SG_ 2565668606 MaximumNumberOfPackets "RANGE";
BA_ "SPN" SG_ 2565668606 TotalNumberOfPackets 2558;
BA_ "SigType" SG_ 2565668606 TotalNumberOfPackets "RANGE";
BA_ "SPN" SG_ 2565668606 TotalMessageSize 2557;
BA_ "SigType" SG_ 2565668606 TotalMessageSize "RANGE";
BA_ "SPN" SG_ 2565668606 ControlByte 2556;
BA_ "SPN" SG_ 2563374846 UseTransferMode 2575;
BA_ "SigType" SG_ 2563374846 UseTransferMode "DISCRETE";
BA_ "SPN" SG_ 2563374846 ParameterGroupNumber 2574;
BA_ "SigType" SG_ 2563374846 ParameterGroupNumber "RANGE";
BA_ "SPN" SG_ 2565537534 ParameterGroupNumber 2574;
BA_ "SigType" SG_ 2565537534 ParameterGroupNumber "RANGE";
BA_ "SPN" SG_ 2560556798 PermanentDTCs 4108;
BA_ "SigType" SG_ 2560556798 PermanentDTCs "RANGE";
BA_ "SPN" SG_ 2560556798 PreviouslyMILOnDTCs 4107;
BA_ "SigType" SG_ 2560556798 PreviouslyMILOnDTCs "RANGE";
BA_ "SPN" SG_ 2560556798 MILOnDTCs 4106;
BA_ "SigType" SG_ 2560556798 MILOnDTCs "RANGE";
BA_ "SPN" SG_ 2560556798 AllPendingDTCs 4105;
BA_ "SigType" SG_ 2560556798 AllPendingDTCs "RANGE";
BA_ "SPN" SG_ 2560556798 PendingDTCs 4104;
BA_ "SigType" SG_ 2560556798 PendingDTCs "RANGE";
BA_ "SPN" SG_ 2566750462 FlashRedStopLamp 3039;
BA_ "SPN" SG_ 2566750462 FlashProtectLamp 3041;
BA_ "SPN" SG_ 2566750462 FlashMalfuncIndicatorLamp 3038;
BA_ "SigType" SG_ 2566750462 FlashMalfuncIndicatorLamp "DISCRETE";
BA_ "SPN" SG_ 2566750462 FlashAmberWarningLamp 3040;
BA_ "SPN" SG_ 2566750462 MalfunctionIndicatorLampStatus 1213;
BA_ "SigType" SG_ 2566750462 MalfunctionIndicatorLampStatus "DISCRETE";
BA_ "SPN" SG_ 2566750462 AmberWarningLampStatus 624;
BA_ "SigType" SG_ 2566750462 AmberWarningLampStatus "DISCRETE";
BA_ "SPN" SG_ 2566750462 OccurenceCount1 1216;
BA_ "SigType" SG_ 2566750462 OccurenceCount1 "RANGE";
BA_ "SPN" SG_ 2566750462 SPNConversionMethod1 1706;
BA_ "SPN" SG_ 2566750462 FailureModeIdentifier1 1215;
BA_ "SPN" SG_ 2566750462 SPN1 1214;
BA_ "SPN" SG_ 2566750462 RedStopLampState 623;
BA_ "SigType" SG_ 2566750462 RedStopLampState "DISCRETE";
BA_ "SPN" SG_ 2566750462 ProtectLampStatus 987;
BA_ "SigType" SG_ 2566750462 ProtectLampStatus "DISCRETE";
BA_ "SigType" SG_ 2566750462 OccurenceCount5 "RANGE";
BA_ "SigType" SG_ 2566750462 OccurenceCount4 "RANGE";
BA_ "SigType" SG_ 2566750462 OccurenceCount3 "RANGE";
BA_ "SigType" SG_ 2566750462 OccurenceCount2 "RANGE";
BA_ "SPN" SG_ 2566750462 SPN1High 1214;
BA_ "SPN" SG_ 2566750974 FlashRedStopLamp 3039;
BA_ "SPN" SG_ 2566750974 FlashProtectLamp 3041;
BA_ "SPN" SG_ 2566750974 FlashMalfuncIndicatorLamp 3038;
BA_ "SigType" SG_ 2566750974 FlashMalfuncIndicatorLamp "DISCRETE";
BA_ "SPN" SG_ 2566750974 FlashAmberWarningLamp 3040;
BA_ "SPN" SG_ 2566750974 MalfunctionIndicatorLampStatus 1213;
BA_ "SigType" SG_ 2566750974 MalfunctionIndicatorLampStatus "DISCRETE";
BA_ "SPN" SG_ 2566750974 AmberWarningLampStatus 624;
BA_ "SigType" SG_ 2566750974 AmberWarningLampStatus "DISCRETE";
BA_ "SPN" SG_ 2566750974 OccurenceCount1 1216;
BA_ "SigType" SG_ 2566750974 OccurenceCount1 "RANGE";
BA_ "SPN" SG_ 2566750974 SPNConversionMethod1 1706;
BA_ "SPN" SG_ 2566750974 FailureModeIdentifier1 1215;
BA_ "SPN" SG_ 2566750974 SPN1 1214;
BA_ "SPN" SG_ 2566750974 RedStopLampState 623;
BA_ "SigType" SG_ 2566750974 RedStopLampState "DISCRETE";
BA_ "SPN" SG_ 2566750974 ProtectLampStatus 987;
BA_ "SigType" SG_ 2566750974 ProtectLampStatus "DISCRETE";
BA_ "SigType" SG_ 2566750974 OccurenceCount5 "RANGE";
BA_ "SigType" SG_ 2566750974 OccurenceCount4 "RANGE";
BA_ "SigType" SG_ 2566750974 OccurenceCount3 "RANGE";
BA_ "SigType" SG_ 2566750974 OccurenceCount2 "RANGE";
BA_ "SPN" SG_ 2566750974 SPN1High 1214;
BA_ "SPN" SG_ 2566748414 Aftrtrtmnt2TrpPssvRgnrationTime 3745;
BA_ "SigType" SG_ 2566748414 Aftrtrtmnt2TrpPssvRgnrationTime "RANGE";
BA_ "SPN" SG_ 2566748414 Aftrtrtmnt2TrpNmbrOfPssvRgnrtns 3746;
BA_ "SigType" SG_ 2566748414 Aftrtrtmnt2TrpNmbrOfPssvRgnrtns "RANGE";
BA_ "SPN" SG_ 2566748414 Aftrtrtmnt2TrpNmbrOfActvRgnrtns 3744;
BA_ "SigType" SG_ 2566748414 Aftrtrtmnt2TrpNmbrOfActvRgnrtns "RANGE";
BA_ "SPN" SG_ 2566748414 Aftrtrtmnt2TrpNmbrOfActvRgnrtnMn 3748;
BA_ "SigType" SG_ 2566748414 Aftrtrtmnt2TrpNmbrOfActvRgnrtnMn "RANGE";
BA_ "SPN" SG_ 2566748414 Aftrtrtmnt2TrpNmbrOfActvRgnrtnIn 3747;
BA_ "SigType" SG_ 2566748414 Aftrtrtmnt2TrpNmbrOfActvRgnrtnIn "RANGE";
BA_ "SPN" SG_ 2566748414 Aftrtrtmnt2TrpActvRgnrationTime 3742;
BA_ "SigType" SG_ 2566748414 Aftrtrtmnt2TrpActvRgnrationTime "RANGE";
BA_ "SPN" SG_ 2566748414 Aftertreatment2TripFuelUsed 3741;
BA_ "SigType" SG_ 2566748414 Aftertreatment2TripFuelUsed "RANGE";
BA_ "SPN" SG_ 2566748414 Aftertreatment2TripDisabledTime 3743;
BA_ "SigType" SG_ 2566748414 Aftertreatment2TripDisabledTime "RANGE";
BA_ "SPN" SG_ 2566748670 Aftrtrtmnt1TrpPssvRgnrationTime 3737;
BA_ "SigType" SG_ 2566748670 Aftrtrtmnt1TrpPssvRgnrationTime "RANGE";
BA_ "SPN" SG_ 2566748670 Aftrtrtmnt1TrpNmbrOfPssvRgnrtns 3738;
BA_ "SigType" SG_ 2566748670 Aftrtrtmnt1TrpNmbrOfPssvRgnrtns "RANGE";
BA_ "SPN" SG_ 2566748670 Aftrtrtmnt1TrpNmbrOfActvRgnrtns 3736;
BA_ "SigType" SG_ 2566748670 Aftrtrtmnt1TrpNmbrOfActvRgnrtns "RANGE";
BA_ "SPN" SG_ 2566748670 Aftrtrtmnt1TrpNmbrOfActvRgnrtnMn 3740;
BA_ "SigType" SG_ 2566748670 Aftrtrtmnt1TrpNmbrOfActvRgnrtnMn "RANGE";
BA_ "SPN" SG_ 2566748670 Aftrtrtmnt1TrpNmbrOfActvRgnrtnIn 3739;
BA_ "SigType" SG_ 2566748670 Aftrtrtmnt1TrpNmbrOfActvRgnrtnIn "RANGE";
BA_ "SPN" SG_ 2566748670 Aftrtrtmnt1TrpActvRgnrationTime 3734;
BA_ "SigType" SG_ 2566748670 Aftrtrtmnt1TrpActvRgnrationTime "RANGE";
BA_ "SPN" SG_ 2566748670 Aftertreatment1TripFuelUsed 3733;
BA_ "SigType" SG_ 2566748670 Aftertreatment1TripFuelUsed "RANGE";
BA_ "SPN" SG_ 2566748670 Aftertreatment1TripDisabledTime 3735;
BA_ "SigType" SG_ 2566748670 Aftertreatment1TripDisabledTime "RANGE";
BA_ "SPN" SG_ 2566745598 Aftertreatment1SecondAirPress 3837;
BA_ "SigType" SG_ 2566745598 Aftertreatment1SecondAirPress "RANGE";
BA_ "SPN" SG_ 2566745598 Aftrtreatment1SecondAirMassFlow 3832;
BA_ "SigType" SG_ 2566745598 Aftrtreatment1SecondAirMassFlow "RANGE";
BA_ "SPN" SG_ 2566745598 Aftertreatment1SecondAirTemp 3831;
BA_ "SigType" SG_ 2566745598 Aftertreatment1SecondAirTemp "RANGE";
BA_ "SPN" SG_ 2566745598 Aftrtratment1SecondAirDiffPress 3830;
BA_ "SigType" SG_ 2566745598 Aftrtratment1SecondAirDiffPress "RANGE";
BA_ "SPN" SG_ 2566745342 Aftertreatment2SecondAirPress 3838;
BA_ "SigType" SG_ 2566745342 Aftertreatment2SecondAirPress "RANGE";
BA_ "SPN" SG_ 2566745342 Aftrtreatment2SecondAirMassFlow 3835;
BA_ "SigType" SG_ 2566745342 Aftrtreatment2SecondAirMassFlow "RANGE";
BA_ "SPN" SG_ 2566745342 Aftertreatment2SecondAirTemp 3834;
BA_ "SigType" SG_ 2566745342 Aftertreatment2SecondAirTemp "RANGE";
BA_ "SPN" SG_ 2566745342 Aftrtratment2SecondAirDiffPress 3833;
BA_ "SigType" SG_ 2566745342 Aftrtratment2SecondAirDiffPress "RANGE";
BA_ "SPN" SG_ 2566754558 NumberOfAETCDataPoints 3559;
BA_ "SigType" SG_ 2566754558 NumberOfAETCDataPoints "DISCRETE";
BA_ "SPN" SG_ 2566754558 AETCDataCollectionStandard 3558;
BA_ "SigType" SG_ 2566754558 AETCDataCollectionStandard "DISCRETE";
BA_ "SPN" SG_ 2566749950 RightHeadlampLightDistribution 3694;
BA_ "SigType" SG_ 2566749950 RightHeadlampLightDistribution "DISCRETE";
BA_ "SPN" SG_ 2566749950 LeftHeadlampLightDistribution 3693;
BA_ "SigType" SG_ 2566749950 LeftHeadlampLightDistribution "DISCRETE";
BA_ "SPN" SG_ 2566749950 RghtHeadlampDynamicBendingLight 3692;
BA_ "SigType" SG_ 2566749950 RghtHeadlampDynamicBendingLight "DISCRETE";
BA_ "SPN" SG_ 2566749950 LeftHeadlampDynamicBendingLight 3691;
BA_ "SigType" SG_ 2566749950 LeftHeadlampDynamicBendingLight "DISCRETE";
BA_ "SPN" SG_ 2565869310 Aftrtrtmnt1IntkOxygnSnsrPrlmnryF 3225;
BA_ "SigType" SG_ 2565869310 Aftrtrtmnt1IntkOxygnSnsrPrlmnryF "RANGE";
BA_ "SPN" SG_ 2565869310 Aftrtrtmnt1IntkNOxSnsrPrlmnryFMI 3224;
BA_ "SigType" SG_ 2565869310 Aftrtrtmnt1IntkNOxSnsrPrlmnryFMI "RANGE";
BA_ "SPN" SG_ 2565869310 Aftrtrtmnt1IntkGsSnsrHeaterCtrl 3223;
BA_ "SigType" SG_ 2565869310 Aftrtrtmnt1IntkGsSnsrHeaterCtrl "DISCRETE";
BA_ "SPN" SG_ 2565869310 Aftrtrtmnt1IntkGsSnsrHtrPrlmnryF 3222;
BA_ "SigType" SG_ 2565869310 Aftrtrtmnt1IntkGsSnsrHtrPrlmnryF "RANGE";
BA_ "SPN" SG_ 2565869310 Aftrtrtmnt1IntkWdRngO2RdngStble 3221;
BA_ "SigType" SG_ 2565869310 Aftrtrtmnt1IntkWdRngO2RdngStble "DISCRETE";
BA_ "SPN" SG_ 2565869310 Aftrtrtmnt1IntkNOxReadingStable 3220;
BA_ "SigType" SG_ 2565869310 Aftrtrtmnt1IntkNOxReadingStable "DISCRETE";
BA_ "SPN" SG_ 2565869310 Aftrtrtmnt1IntkeGasSensorAtTemp 3219;
BA_ "SigType" SG_ 2565869310 Aftrtrtmnt1IntkeGasSensorAtTemp "DISCRETE";
BA_ "SPN" SG_ 2565869310 Aftrtrtmnt1IntkGsSnsrPwrInRange 3218;
BA_ "SigType" SG_ 2565869310 Aftrtrtmnt1IntkGsSnsrPwrInRange "DISCRETE";
BA_ "SPN" SG_ 2565869310 Aftertreatment1IntakeO2 3217;
BA_ "SigType" SG_ 2565869310 Aftertreatment1IntakeO2 "RANGE";
BA_ "SPN" SG_ 2565869310 Aftertreatment1IntakeNOx 3216;
BA_ "SigType" SG_ 2565869310 Aftertreatment1IntakeNOx "RANGE";
BA_ "SPN" SG_ 2566763774 Aftrtrtmnt1PrtcltTrpIntkGsTmpPrl 3244;
BA_ "SigType" SG_ 2566763774 Aftrtrtmnt1PrtcltTrpIntkGsTmpPrl "RANGE";
BA_ "SPN" SG_ 2566763774 Aftrtrtmnt1ExhstGsTmp1PrlmnryFMI 3243;
BA_ "SigType" SG_ 2566763774 Aftrtrtmnt1ExhstGsTmp1PrlmnryFMI "RANGE";
BA_ "SPN" SG_ 2566763774 Aftrtrtmnt1PrtcltTrpIntkGasTemp 3242;
BA_ "SigType" SG_ 2566763774 Aftrtrtmnt1PrtcltTrpIntkGasTemp "RANGE";
BA_ "SPN" SG_ 2566763774 Aftertreatment1ExhaustGasTemp1 3241;
BA_ "SigType" SG_ 2566763774 Aftertreatment1ExhaustGasTemp1 "RANGE";
BA_ "SPN" SG_ 2565869566 Aftrtrtmnt1OtltOxygnSnsrPrlmnryF 3235;
BA_ "SigType" SG_ 2565869566 Aftrtrtmnt1OtltOxygnSnsrPrlmnryF "RANGE";
BA_ "SPN" SG_ 2565869566 Aftrtrtmnt1OtltNOxSnsrPrlmnryFMI 3234;
BA_ "SigType" SG_ 2565869566 Aftrtrtmnt1OtltNOxSnsrPrlmnryFMI "RANGE";
BA_ "SPN" SG_ 2565869566 Aftrtrtmnt1OtltGsSnsrHeaterCtrl 3233;
BA_ "SigType" SG_ 2565869566 Aftrtrtmnt1OtltGsSnsrHeaterCtrl "DISCRETE";
BA_ "SPN" SG_ 2565869566 Aftrtrtmnt1OtltGsSnsrHtrPrlmnryF 3232;
BA_ "SigType" SG_ 2565869566 Aftrtrtmnt1OtltGsSnsrHtrPrlmnryF "RANGE";
BA_ "SPN" SG_ 2565869566 Aftrtrtmnt1OtltWdRngO2RdngStble 3231;
BA_ "SigType" SG_ 2565869566 Aftrtrtmnt1OtltWdRngO2RdngStble "DISCRETE";
BA_ "SPN" SG_ 2565869566 Aftrtrtmnt1OtltNOxReadingStable 3230;
BA_ "SigType" SG_ 2565869566 Aftrtrtmnt1OtltNOxReadingStable "DISCRETE";
BA_ "SPN" SG_ 2565869566 Aftrtrtmnt1OtletGasSensorAtTemp 3229;
BA_ "SigType" SG_ 2565869566 Aftrtrtmnt1OtletGasSensorAtTemp "DISCRETE";
BA_ "SPN" SG_ 2565869566 Aftrtrtmnt1OtltGsSnsrPwrInRange 3228;
BA_ "SigType" SG_ 2565869566 Aftrtrtmnt1OtltGsSnsrPwrInRange "DISCRETE";
BA_ "SPN" SG_ 2565869566 Aftertreatment1OutletO2 3227;
BA_ "SigType" SG_ 2565869566 Aftertreatment1OutletO2 "RANGE";
BA_ "SPN" SG_ 2565869566 Aftertreatment1OutletNOx 3226;
BA_ "SigType" SG_ 2565869566 Aftertreatment1OutletNOx "RANGE";
BA_ "SPN" SG_ 2566763518 Aftrtrtmnt1PrtcltTrpOtltExhstGsT 3248;
BA_ "SigType" SG_ 2566763518 Aftrtrtmnt1PrtcltTrpOtltExhstGsT "RANGE";
BA_ "SPN" SG_ 2566763518 Aftrtrtmnt1ExhstGsTmp3PrlmnryFMI 3247;
BA_ "SigType" SG_ 2566763518 Aftrtrtmnt1ExhstGsTmp3PrlmnryFMI "RANGE";
BA_ "SPN" SG_ 2566763518 Aftrtrtmnt1PrtcltTrpOtltGasTemp 3246;
BA_ "SigType" SG_ 2566763518 Aftrtrtmnt1PrtcltTrpOtltGasTemp "RANGE";
BA_ "SPN" SG_ 2566763518 Aftertreatment1ExhaustGasTemp3 3245;
BA_ "SigType" SG_ 2566763518 Aftertreatment1ExhaustGasTemp3 "RANGE";
BA_ "SPN" SG_ 2565869822 Aftrtrtmnt2IntkOxygnSnsrPrlmnryF 3264;
BA_ "SigType" SG_ 2565869822 Aftrtrtmnt2IntkOxygnSnsrPrlmnryF "RANGE";
BA_ "SPN" SG_ 2565869822 Aftrtrtmnt2IntkNOxSnsrPrlmnryFMI 3263;
BA_ "SigType" SG_ 2565869822 Aftrtrtmnt2IntkNOxSnsrPrlmnryFMI "RANGE";
BA_ "SPN" SG_ 2565869822 Aftrtrtmnt2IntkGsSnsrHeaterCtrl 3262;
BA_ "SigType" SG_ 2565869822 Aftrtrtmnt2IntkGsSnsrHeaterCtrl "DISCRETE";
BA_ "SPN" SG_ 2565869822 Aftrtrtmnt2IntkGsSnsrHtrPrlmnryF 3261;
BA_ "SigType" SG_ 2565869822 Aftrtrtmnt2IntkGsSnsrHtrPrlmnryF "RANGE";
BA_ "SPN" SG_ 2565869822 Aftrtrtmnt2IntkWdRngO2RdngStble 3260;
BA_ "SigType" SG_ 2565869822 Aftrtrtmnt2IntkWdRngO2RdngStble "DISCRETE";
BA_ "SPN" SG_ 2565869822 Aftrtrtmnt2IntkNOxReadingStable 3259;
BA_ "SigType" SG_ 2565869822 Aftrtrtmnt2IntkNOxReadingStable "DISCRETE";
BA_ "SPN" SG_ 2565869822 Aftrtrtmnt2IntkeGasSensorAtTemp 3258;
BA_ "SigType" SG_ 2565869822 Aftrtrtmnt2IntkeGasSensorAtTemp "DISCRETE";
BA_ "SPN" SG_ 2565869822 Aftrtrtmnt2IntkGsSnsrPwrInRange 3257;
BA_ "SigType" SG_ 2565869822 Aftrtrtmnt2IntkGsSnsrPwrInRange "DISCRETE";
BA_ "SPN" SG_ 2565869822 Aftertreatment2IntakeO2 3256;
BA_ "SigType" SG_ 2565869822 Aftertreatment2IntakeO2 "RANGE";
BA_ "SPN" SG_ 2565869822 Aftertreatment2IntakeNOx 3255;
BA_ "SigType" SG_ 2565869822 Aftertreatment2IntakeNOx "RANGE";
BA_ "SPN" SG_ 2566763006 Aftrtrtmnt2PrtcltTrpIntkGsTmpPrl 3278;
BA_ "SigType" SG_ 2566763006 Aftrtrtmnt2PrtcltTrpIntkGsTmpPrl "RANGE";
BA_ "SPN" SG_ 2566763006 Aftrtrtmnt2ExhstGsTmp1PrlmnryFMI 3277;
BA_ "SigType" SG_ 2566763006 Aftrtrtmnt2ExhstGsTmp1PrlmnryFMI "RANGE";
BA_ "SPN" SG_ 2566763006 Aftrtrtmnt2PrtcltTrpIntkGasTemp 3276;
BA_ "SigType" SG_ 2566763006 Aftrtrtmnt2PrtcltTrpIntkGasTemp "RANGE";
BA_ "SPN" SG_ 2566763006 Aftertreatment2ExhaustGasTemp1 3275;
BA_ "SigType" SG_ 2566763006 Aftertreatment2ExhaustGasTemp1 "RANGE";
BA_ "SPN" SG_ 2565870078 Aftrtrtmnt2OtltOxygnSnsrPrlmnryF 3274;
BA_ "SigType" SG_ 2565870078 Aftrtrtmnt2OtltOxygnSnsrPrlmnryF "RANGE";
BA_ "SPN" SG_ 2565870078 Aftrtrtmnt2OtltNOxSnsrPrlmnryFMI 3273;
BA_ "SigType" SG_ 2565870078 Aftrtrtmnt2OtltNOxSnsrPrlmnryFMI "RANGE";
BA_ "SPN" SG_ 2565870078 Aftrtrtmnt2OtltGsSnsrHeaterCtrl 3272;
BA_ "SigType" SG_ 2565870078 Aftrtrtmnt2OtltGsSnsrHeaterCtrl "DISCRETE";
BA_ "SPN" SG_ 2565870078 Aftrtrtmnt2OtltGsSnsrHtrPrlmnryF 3271;
BA_ "SigType" SG_ 2565870078 Aftrtrtmnt2OtltGsSnsrHtrPrlmnryF "RANGE";
BA_ "SPN" SG_ 2565870078 Aftrtrtmnt2OtltWdRngO2RdngStble 3270;
BA_ "SigType" SG_ 2565870078 Aftrtrtmnt2OtltWdRngO2RdngStble "DISCRETE";
BA_ "SPN" SG_ 2565870078 Aftrtrtmnt2OtltNOxReadingStable 3269;
BA_ "SigType" SG_ 2565870078 Aftrtrtmnt2OtltNOxReadingStable "DISCRETE";
BA_ "SPN" SG_ 2565870078 Aftrtrtmnt2OtletGasSensorAtTemp 3268;
BA_ "SigType" SG_ 2565870078 Aftrtrtmnt2OtletGasSensorAtTemp "DISCRETE";
BA_ "SPN" SG_ 2565870078 Aftrtrtmnt2OtltGsSnsrPwrInRange 3267;
BA_ "SigType" SG_ 2565870078 Aftrtrtmnt2OtltGsSnsrPwrInRange "DISCRETE";
BA_ "SPN" SG_ 2565870078 Aftertreatment2OutletO2 3266;
BA_ "SigType" SG_ 2565870078 Aftertreatment2OutletO2 "RANGE";
BA_ "SPN" SG_ 2565870078 Aftertreatment2OutletNOx 3265;
BA_ "SigType" SG_ 2565870078 Aftertreatment2OutletNOx "RANGE";
BA_ "SPN" SG_ 2566762750 Aftrtrtmnt2PrtcltTrpExhstGsTmpPr 3282;
BA_ "SigType" SG_ 2566762750 Aftrtrtmnt2PrtcltTrpExhstGsTmpPr "RANGE";
BA_ "SPN" SG_ 2566762750 Aftrtrtmnt2ExhstGsTmp3PrlmnryFMI 3281;
BA_ "SigType" SG_ 2566762750 Aftrtrtmnt2ExhstGsTmp3PrlmnryFMI "RANGE";
BA_ "SPN" SG_ 2566762750 Aftrtrtmnt2PrtcltTrpOtltGasTemp 3280;
BA_ "SigType" SG_ 2566762750 Aftrtrtmnt2PrtcltTrpOtltGasTemp "RANGE";
BA_ "SPN" SG_ 2566762750 Aftertreatment2ExhaustGasTemp3 3279;
BA_ "SigType" SG_ 2566762750 Aftertreatment2ExhaustGasTemp3 "RANGE";
BA_ "SPN" SG_ 2566753534 ParticulateTrapOutletPress1 3610;
BA_ "SigType" SG_ 2566753534 ParticulateTrapOutletPress1 "RANGE";
BA_ "SPN" SG_ 2566753534 ParticulateTrapIntakePress1 3609;
BA_ "SigType" SG_ 2566753534 ParticulateTrapIntakePress1 "RANGE";
BA_ "SPN" SG_ 2566753278 ParticulateTrapOutletPress2 3612;
BA_ "SigType" SG_ 2566753278 ParticulateTrapOutletPress2 "RANGE";
BA_ "SPN" SG_ 2566753278 ParticulateTrapIntakePress2 3611;
BA_ "SigType" SG_ 2566753278 ParticulateTrapIntakePress2 "RANGE";
BA_ "SPN" SG_ 2566762494 Aftrtrtmnt2PrtcltTrpDltPrssPrlmn 3287;
BA_ "SigType" SG_ 2566762494 Aftrtrtmnt2PrtcltTrpDltPrssPrlmn "RANGE";
BA_ "SPN" SG_ 2566762494 Aftrtrtmnt2ExhstGsTmp2PrlmnryFMI 3286;
BA_ "SigType" SG_ 2566762494 Aftrtrtmnt2ExhstGsTmp2PrlmnryFMI "RANGE";
BA_ "SPN" SG_ 2566762494 Aftrtrtmnt2PrtclteTrapDiffPress 3285;
BA_ "SigType" SG_ 2566762494 Aftrtrtmnt2PrtclteTrapDiffPress "RANGE";
BA_ "SPN" SG_ 2566762494 Aftertreatment2ExhaustGasTemp2 3283;
BA_ "SigType" SG_ 2566762494 Aftertreatment2ExhaustGasTemp2 "RANGE";
BA_ "SPN" SG_ 2566749182 PrtcltTrp1TmSncLstActvRgnration 3721;
BA_ "SigType" SG_ 2566749182 PrtcltTrp1TmSncLstActvRgnration "RANGE";
BA_ "SPN" SG_ 2566749182 ParticulateTrap1AshLoadPercent 3720;
BA_ "SigType" SG_ 2566749182 ParticulateTrap1AshLoadPercent "RANGE";
BA_ "SPN" SG_ 2566749182 ParticulateTrap1SootLoadPercent 3719;
BA_ "SigType" SG_ 2566749182 ParticulateTrap1SootLoadPercent "RANGE";
BA_ "SPN" SG_ 2566748926 PrtcltTrp2TmSncLstActvRgnration 3724;
BA_ "SigType" SG_ 2566748926 PrtcltTrp2TmSncLstActvRgnration "RANGE";
BA_ "SPN" SG_ 2566748926 ParticulateTrap2AshLoadPercent 3723;
BA_ "SigType" SG_ 2566748926 ParticulateTrap2AshLoadPercent "RANGE";
BA_ "SPN" SG_ 2566748926 ParticulateTrap2SootLoadPercent 3722;
BA_ "SigType" SG_ 2566748926 ParticulateTrap2SootLoadPercent "RANGE";
BA_ "SPN" SG_ 2566838782 AuxI_OChannel2 1084;
BA_ "SigType" SG_ 2566838782 AuxI_OChannel2 "RANGE";
BA_ "SPN" SG_ 2566838782 AuxI_OChannel1 1083;
BA_ "SigType" SG_ 2566838782 AuxI_OChannel1 "RANGE";
BA_ "SPN" SG_ 2561146622 AuxI_O45 3868;
BA_ "SigType" SG_ 2561146622 AuxI_O45 "DISCRETE";
BA_ "SPN" SG_ 2561146622 AuxI_O46 3869;
BA_ "SigType" SG_ 2561146622 AuxI_O46 "DISCRETE";
BA_ "SPN" SG_ 2561146622 AuxI_O47 3870;
BA_ "SigType" SG_ 2561146622 AuxI_O47 "DISCRETE";
BA_ "SPN" SG_ 2561146622 AuxI_O48 3871;
BA_ "SigType" SG_ 2561146622 AuxI_O48 "DISCRETE";
BA_ "SPN" SG_ 2561146622 AuxI_O41 3864;
BA_ "SigType" SG_ 2561146622 AuxI_O41 "DISCRETE";
BA_ "SPN" SG_ 2561146622 AuxI_O42 3865;
BA_ "SigType" SG_ 2561146622 AuxI_O42 "DISCRETE";
BA_ "SPN" SG_ 2561146622 AuxI_O43 3866;
BA_ "SigType" SG_ 2561146622 AuxI_O43 "DISCRETE";
BA_ "SPN" SG_ 2561146622 AuxI_O44 3867;
BA_ "SigType" SG_ 2561146622 AuxI_O44 "DISCRETE";
BA_ "SPN" SG_ 2561146622 AuxI_O37 3860;
BA_ "SigType" SG_ 2561146622 AuxI_O37 "DISCRETE";
BA_ "SPN" SG_ 2561146622 AuxI_O38 3861;
BA_ "SigType" SG_ 2561146622 AuxI_O38 "DISCRETE";
BA_ "SPN" SG_ 2561146622 AuxI_O39 3862;
BA_ "SigType" SG_ 2561146622 AuxI_O39 "DISCRETE";
BA_ "SPN" SG_ 2561146622 AuxI_O40 3863;
BA_ "SigType" SG_ 2561146622 AuxI_O40 "DISCRETE";
BA_ "SPN" SG_ 2561146622 AuxI_O33 3856;
BA_ "SigType" SG_ 2561146622 AuxI_O33 "DISCRETE";
BA_ "SPN" SG_ 2561146622 AuxI_O34 3857;
BA_ "SigType" SG_ 2561146622 AuxI_O34 "DISCRETE";
BA_ "SPN" SG_ 2561146622 AuxI_O35 3858;
BA_ "SigType" SG_ 2561146622 AuxI_O35 "DISCRETE";
BA_ "SPN" SG_ 2561146622 AuxI_O36 3859;
BA_ "SigType" SG_ 2561146622 AuxI_O36 "DISCRETE";
BA_ "SPN" SG_ 2561146622 AuxI_O29 3852;
BA_ "SigType" SG_ 2561146622 AuxI_O29 "DISCRETE";
BA_ "SPN" SG_ 2561146622 AuxI_O30 3853;
BA_ "SigType" SG_ 2561146622 AuxI_O30 "DISCRETE";
BA_ "SPN" SG_ 2561146622 AuxI_O31 3854;
BA_ "SigType" SG_ 2561146622 AuxI_O31 "DISCRETE";
BA_ "SPN" SG_ 2561146622 AuxI_O32 3855;
BA_ "SigType" SG_ 2561146622 AuxI_O32 "DISCRETE";
BA_ "SPN" SG_ 2561146622 AuxI_O25 3848;
BA_ "SigType" SG_ 2561146622 AuxI_O25 "DISCRETE";
BA_ "SPN" SG_ 2561146622 AuxI_O26 3849;
BA_ "SigType" SG_ 2561146622 AuxI_O26 "DISCRETE";
BA_ "SPN" SG_ 2561146622 AuxI_O27 3850;
BA_ "SigType" SG_ 2561146622 AuxI_O27 "DISCRETE";
BA_ "SPN" SG_ 2561146622 AuxI_O28 3851;
BA_ "SigType" SG_ 2561146622 AuxI_O28 "DISCRETE";
BA_ "SPN" SG_ 2561146622 AuxI_O21 3844;
BA_ "SigType" SG_ 2561146622 AuxI_O21 "DISCRETE";
BA_ "SPN" SG_ 2561146622 AuxI_O22 3845;
BA_ "SigType" SG_ 2561146622 AuxI_O22 "DISCRETE";
BA_ "SPN" SG_ 2561146622 AuxI_O23 3846;
BA_ "SigType" SG_ 2561146622 AuxI_O23 "DISCRETE";
BA_ "SPN" SG_ 2561146622 AuxI_O24 3847;
BA_ "SigType" SG_ 2561146622 AuxI_O24 "DISCRETE";
BA_ "SPN" SG_ 2561146622 AuxI_O17 3840;
BA_ "SigType" SG_ 2561146622 AuxI_O17 "DISCRETE";
BA_ "SPN" SG_ 2561146622 AuxI_O18 3841;
BA_ "SigType" SG_ 2561146622 AuxI_O18 "DISCRETE";
BA_ "SPN" SG_ 2561146622 AuxI_O19 3842;
BA_ "SigType" SG_ 2561146622 AuxI_O19 "DISCRETE";
BA_ "SPN" SG_ 2561146622 AuxI_O20 3843;
BA_ "SigType" SG_ 2561146622 AuxI_O20 "DISCRETE";
BA_ "SPN" SG_ 2561081086 AuxI_O77 3900;
BA_ "SigType" SG_ 2561081086 AuxI_O77 "DISCRETE";
BA_ "SPN" SG_ 2561081086 AuxI_O78 3901;
BA_ "SigType" SG_ 2561081086 AuxI_O78 "DISCRETE";
BA_ "SPN" SG_ 2561081086 AuxI_O79 3902;
BA_ "SigType" SG_ 2561081086 AuxI_O79 "DISCRETE";
BA_ "SPN" SG_ 2561081086 AuxI_O80 3903;
BA_ "SigType" SG_ 2561081086 AuxI_O80 "DISCRETE";
BA_ "SPN" SG_ 2561081086 AuxI_O73 3896;
BA_ "SigType" SG_ 2561081086 AuxI_O73 "DISCRETE";
BA_ "SPN" SG_ 2561081086 AuxI_O74 3897;
BA_ "SigType" SG_ 2561081086 AuxI_O74 "DISCRETE";
BA_ "SPN" SG_ 2561081086 AuxI_O75 3898;
BA_ "SigType" SG_ 2561081086 AuxI_O75 "DISCRETE";
BA_ "SPN" SG_ 2561081086 AuxI_O76 3899;
BA_ "SigType" SG_ 2561081086 AuxI_O76 "DISCRETE";
BA_ "SPN" SG_ 2561081086 AuxI_O69 3892;
BA_ "SigType" SG_ 2561081086 AuxI_O69 "DISCRETE";
BA_ "SPN" SG_ 2561081086 AuxI_O70 3893;
BA_ "SigType" SG_ 2561081086 AuxI_O70 "DISCRETE";
BA_ "SPN" SG_ 2561081086 AuxI_O71 3894;
BA_ "SigType" SG_ 2561081086 AuxI_O71 "DISCRETE";
BA_ "SPN" SG_ 2561081086 AuxI_O72 3895;
BA_ "SigType" SG_ 2561081086 AuxI_O72 "DISCRETE";
BA_ "SPN" SG_ 2561081086 AuxI_O65 3888;
BA_ "SigType" SG_ 2561081086 AuxI_O65 "DISCRETE";
BA_ "SPN" SG_ 2561081086 AuxI_O66 3889;
BA_ "SigType" SG_ 2561081086 AuxI_O66 "DISCRETE";
BA_ "SPN" SG_ 2561081086 AuxI_O67 3890;
BA_ "SigType" SG_ 2561081086 AuxI_O67 "DISCRETE";
BA_ "SPN" SG_ 2561081086 AuxI_O68 3891;
BA_ "SigType" SG_ 2561081086 AuxI_O68 "DISCRETE";
BA_ "SPN" SG_ 2561081086 AuxI_O61 3884;
BA_ "SigType" SG_ 2561081086 AuxI_O61 "DISCRETE";
BA_ "SPN" SG_ 2561081086 AuxI_O62 3885;
BA_ "SigType" SG_ 2561081086 AuxI_O62 "DISCRETE";
BA_ "SPN" SG_ 2561081086 AuxI_O63 3886;
BA_ "SigType" SG_ 2561081086 AuxI_O63 "DISCRETE";
BA_ "SPN" SG_ 2561081086 AuxI_O64 3887;
BA_ "SigType" SG_ 2561081086 AuxI_O64 "DISCRETE";
BA_ "SPN" SG_ 2561081086 AuxI_O57 3880;
BA_ "SigType" SG_ 2561081086 AuxI_O57 "DISCRETE";
BA_ "SPN" SG_ 2561081086 AuxI_O58 3881;
BA_ "SigType" SG_ 2561081086 AuxI_O58 "DISCRETE";
BA_ "SPN" SG_ 2561081086 AuxI_O59 3882;
BA_ "SigType" SG_ 2561081086 AuxI_O59 "DISCRETE";
BA_ "SPN" SG_ 2561081086 AuxI_O60 3883;
BA_ "SigType" SG_ 2561081086 AuxI_O60 "DISCRETE";
BA_ "SPN" SG_ 2561081086 AuxI_O53 3876;
BA_ "SigType" SG_ 2561081086 AuxI_O53 "DISCRETE";
BA_ "SPN" SG_ 2561081086 AuxI_O54 3877;
BA_ "SigType" SG_ 2561081086 AuxI_O54 "DISCRETE";
BA_ "SPN" SG_ 2561081086 AuxI_O55 3878;
BA_ "SigType" SG_ 2561081086 AuxI_O55 "DISCRETE";
BA_ "SPN" SG_ 2561081086 AuxI_O56 3879;
BA_ "SigType" SG_ 2561081086 AuxI_O56 "DISCRETE";
BA_ "SPN" SG_ 2561081086 AuxI_O49 3872;
BA_ "SigType" SG_ 2561081086 AuxI_O49 "DISCRETE";
BA_ "SPN" SG_ 2561081086 AuxI_O50 3873;
BA_ "SigType" SG_ 2561081086 AuxI_O50 "DISCRETE";
BA_ "SPN" SG_ 2561081086 AuxI_O51 3874;
BA_ "SigType" SG_ 2561081086 AuxI_O51 "DISCRETE";
BA_ "SPN" SG_ 2561081086 AuxI_O52 3875;
BA_ "SigType" SG_ 2561081086 AuxI_O52 "DISCRETE";
BA_ "SPN" SG_ 2561015550 AuxI_O92 3915;
BA_ "SigType" SG_ 2561015550 AuxI_O92 "DISCRETE";
BA_ "SPN" SG_ 2561015550 AuxI_O85 3908;
BA_ "SigType" SG_ 2561015550 AuxI_O85 "DISCRETE";
BA_ "SPN" SG_ 2561015550 AuxI_O86 3909;
BA_ "SigType" SG_ 2561015550 AuxI_O86 "DISCRETE";
BA_ "SPN" SG_ 2561015550 AuxI_O87 3910;
BA_ "SigType" SG_ 2561015550 AuxI_O87 "DISCRETE";
BA_ "SPN" SG_ 2561015550 AuxI_O88 3911;
BA_ "SigType" SG_ 2561015550 AuxI_O88 "DISCRETE";
BA_ "SPN" SG_ 2561015550 AuxI_O81 3904;
BA_ "SigType" SG_ 2561015550 AuxI_O81 "DISCRETE";
BA_ "SPN" SG_ 2561015550 AuxI_O82 3905;
BA_ "SigType" SG_ 2561015550 AuxI_O82 "DISCRETE";
BA_ "SPN" SG_ 2561015550 AuxI_O83 3906;
BA_ "SigType" SG_ 2561015550 AuxI_O83 "DISCRETE";
BA_ "SPN" SG_ 2561015550 AuxI_O84 3907;
BA_ "SigType" SG_ 2561015550 AuxI_O84 "DISCRETE";
BA_ "SPN" SG_ 2561015550 AuxI_O109 3932;
BA_ "SigType" SG_ 2561015550 AuxI_O109 "DISCRETE";
BA_ "SPN" SG_ 2561015550 AuxI_O110 3933;
BA_ "SigType" SG_ 2561015550 AuxI_O110 "DISCRETE";
BA_ "SPN" SG_ 2561015550 AuxI_O111 3934;
BA_ "SigType" SG_ 2561015550 AuxI_O111 "DISCRETE";
BA_ "SPN" SG_ 2561015550 AuxI_O112 3935;
BA_ "SigType" SG_ 2561015550 AuxI_O112 "DISCRETE";
BA_ "SPN" SG_ 2561015550 AuxI_O105 3928;
BA_ "SigType" SG_ 2561015550 AuxI_O105 "DISCRETE";
BA_ "SPN" SG_ 2561015550 AuxI_O106 3929;
BA_ "SigType" SG_ 2561015550 AuxI_O106 "DISCRETE";
BA_ "SPN" SG_ 2561015550 AuxI_O107 3930;
BA_ "SigType" SG_ 2561015550 AuxI_O107 "DISCRETE";
BA_ "SPN" SG_ 2561015550 AuxI_O108 3931;
BA_ "SigType" SG_ 2561015550 AuxI_O108 "DISCRETE";
BA_ "SPN" SG_ 2561015550 AuxI_O101 3924;
BA_ "SigType" SG_ 2561015550 AuxI_O101 "DISCRETE";
BA_ "SPN" SG_ 2561015550 AuxI_O102 3925;
BA_ "SigType" SG_ 2561015550 AuxI_O102 "DISCRETE";
BA_ "SPN" SG_ 2561015550 AuxI_O103 3926;
BA_ "SigType" SG_ 2561015550 AuxI_O103 "DISCRETE";
BA_ "SPN" SG_ 2561015550 AuxI_O104 3927;
BA_ "SigType" SG_ 2561015550 AuxI_O104 "DISCRETE";
BA_ "SPN" SG_ 2561015550 AuxI_O97 3920;
BA_ "SigType" SG_ 2561015550 AuxI_O97 "DISCRETE";
BA_ "SPN" SG_ 2561015550 AuxI_O98 3921;
BA_ "SigType" SG_ 2561015550 AuxI_O98 "DISCRETE";
BA_ "SPN" SG_ 2561015550 AuxI_O99 3922;
BA_ "SigType" SG_ 2561015550 AuxI_O99 "DISCRETE";
BA_ "SPN" SG_ 2561015550 AuxI_O100 3923;
BA_ "SigType" SG_ 2561015550 AuxI_O100 "DISCRETE";
BA_ "SPN" SG_ 2561015550 AuxI_O93 3916;
BA_ "SigType" SG_ 2561015550 AuxI_O93 "DISCRETE";
BA_ "SPN" SG_ 2561015550 AuxI_O94 3917;
BA_ "SigType" SG_ 2561015550 AuxI_O94 "DISCRETE";
BA_ "SPN" SG_ 2561015550 AuxI_O95 3918;
BA_ "SigType" SG_ 2561015550 AuxI_O95 "DISCRETE";
BA_ "SPN" SG_ 2561015550 AuxI_O96 3919;
BA_ "SigType" SG_ 2561015550 AuxI_O96 "DISCRETE";
BA_ "SPN" SG_ 2561015550 AuxI_O89 3912;
BA_ "SigType" SG_ 2561015550 AuxI_O89 "DISCRETE";
BA_ "SPN" SG_ 2561015550 AuxI_O90 3913;
BA_ "SigType" SG_ 2561015550 AuxI_O90 "DISCRETE";
BA_ "SPN" SG_ 2561015550 AuxI_O91 3914;
BA_ "SigType" SG_ 2561015550 AuxI_O91 "DISCRETE";
BA_ "SPN" SG_ 2566746622 TrailerBrakeStrokeAxle5Right 3804;
BA_ "SigType" SG_ 2566746622 TrailerBrakeStrokeAxle5Right "DISCRETE";
BA_ "SPN" SG_ 2566746622 TrailerBrakeStrokeAxle5Left 3803;
BA_ "SigType" SG_ 2566746622 TrailerBrakeStrokeAxle5Left "DISCRETE";
BA_ "SPN" SG_ 2566746622 TrailerBrakeStrokeAxle4Right 3802;
BA_ "SigType" SG_ 2566746622 TrailerBrakeStrokeAxle4Right "DISCRETE";
BA_ "SPN" SG_ 2566746622 TrailerBrakeStrokeAxle4Left 3801;
BA_ "SigType" SG_ 2566746622 TrailerBrakeStrokeAxle4Left "DISCRETE";
BA_ "SPN" SG_ 2566746622 TrailerBrakeStrokeAxle3Right 3800;
BA_ "SigType" SG_ 2566746622 TrailerBrakeStrokeAxle3Right "DISCRETE";
BA_ "SPN" SG_ 2566746622 TrailerBrakeStrokeAxle3Left 3799;
BA_ "SigType" SG_ 2566746622 TrailerBrakeStrokeAxle3Left "DISCRETE";
BA_ "SPN" SG_ 2566746622 TrailerBrakeStrokeAxle2Right 3798;
BA_ "SigType" SG_ 2566746622 TrailerBrakeStrokeAxle2Right "DISCRETE";
BA_ "SPN" SG_ 2566746622 TrailerBrakeStrokeAxle2Left 3797;
BA_ "SigType" SG_ 2566746622 TrailerBrakeStrokeAxle2Left "DISCRETE";
BA_ "SPN" SG_ 2566746622 TrailerBrakeStrokeAxle1Right 3796;
BA_ "SigType" SG_ 2566746622 TrailerBrakeStrokeAxle1Right "DISCRETE";
BA_ "SPN" SG_ 2566746622 TrailerBrakeStrokeAxle1Left 3795;
BA_ "SigType" SG_ 2566746622 TrailerBrakeStrokeAxle1Left "DISCRETE";
BA_ "SPN" SG_ 2566746622 TractorBrakeStrokeAxle5Right 3794;
BA_ "SigType" SG_ 2566746622 TractorBrakeStrokeAxle5Right "DISCRETE";
BA_ "SPN" SG_ 2566746622 TractorBrakeStrokeAxle5Left 3793;
BA_ "SigType" SG_ 2566746622 TractorBrakeStrokeAxle5Left "DISCRETE";
BA_ "SPN" SG_ 2566746622 TractorBrakeStrokeAxle4Right 3792;
BA_ "SigType" SG_ 2566746622 TractorBrakeStrokeAxle4Right "DISCRETE";
BA_ "SPN" SG_ 2566746622 TractorBrakeStrokeAxle4Left 3791;
BA_ "SigType" SG_ 2566746622 TractorBrakeStrokeAxle4Left "DISCRETE";
BA_ "SPN" SG_ 2566746622 TractorBrakeStrokeAxle3Right 3790;
BA_ "SigType" SG_ 2566746622 TractorBrakeStrokeAxle3Right "DISCRETE";
BA_ "SPN" SG_ 2566746622 TractorBrakeStrokeAxle3Left 3789;
BA_ "SigType" SG_ 2566746622 TractorBrakeStrokeAxle3Left "DISCRETE";
BA_ "SPN" SG_ 2566746622 TractorBrakeStrokeAxle2Right 3788;
BA_ "SigType" SG_ 2566746622 TractorBrakeStrokeAxle2Right "DISCRETE";
BA_ "SPN" SG_ 2566746622 TractorBrakeStrokeAxle2Left 3787;
BA_ "SigType" SG_ 2566746622 TractorBrakeStrokeAxle2Left "DISCRETE";
BA_ "SPN" SG_ 2566746622 TractorBrakeStrokeAxle1Right 3786;
BA_ "SigType" SG_ 2566746622 TractorBrakeStrokeAxle1Right "DISCRETE";
BA_ "SPN" SG_ 2566746622 TractorBrakeStrokeAxle1Left 3785;
BA_ "SigType" SG_ 2566746622 TractorBrakeStrokeAxle1Left "DISCRETE";
BA_ "SPN" SG_ 2566845950 RoadSurfaceTemp 79;
BA_ "SigType" SG_ 2566845950 RoadSurfaceTemp "RANGE";
BA_ "SPN" SG_ 2566845950 EngAirInletTemp 172;
BA_ "SigType" SG_ 2566845950 EngAirInletTemp "RANGE";
BA_ "SPN" SG_ 2566845950 AmbientAirTemp 171;
BA_ "SigType" SG_ 2566845950 AmbientAirTemp "RANGE";
BA_ "SPN" SG_ 2566845950 CabInteriorTemp 170;
BA_ "SigType" SG_ 2566845950 CabInteriorTemp "RANGE";
BA_ "SPN" SG_ 2566845950 BarometricPress 108;
BA_ "SigType" SG_ 2566845950 BarometricPress "RANGE";
BA_ "SPN" SG_ 2566840062 EngAirStartPress 82;
BA_ "SigType" SG_ 2566840062 EngAirStartPress "RANGE";
BA_ "SPN" SG_ 2566827774 AirCompressorStatus 1351;
BA_ "SigType" SG_ 2566827774 AirCompressorStatus "DISCRETE";
BA_ "SPN" SG_ 2566827774 AirSuspensionSupplyPress 1090;
BA_ "SigType" SG_ 2566827774 AirSuspensionSupplyPress "RANGE";
BA_ "SPN" SG_ 2566827774 AuxEquipmentSupplyPress 1089;
BA_ "SigType" SG_ 2566827774 AuxEquipmentSupplyPress "RANGE";
BA_ "SPN" SG_ 2566827774 ServiceBrakeAirPressCircuit2 1088;
BA_ "SigType" SG_ 2566827774 ServiceBrakeAirPressCircuit2 "RANGE";
BA_ "SPN" SG_ 2566827774 ServiceBrakeAirPressCircuit1 1087;
BA_ "SigType" SG_ 2566827774 ServiceBrakeAirPressCircuit1 "RANGE";
BA_ "SPN" SG_ 2566827774 ParkingAnd_OrTrailerAirPress 1086;
BA_ "SigType" SG_ 2566827774 ParkingAnd_OrTrailerAirPress "RANGE";
BA_ "SPN" SG_ 2566827774 PneumaticSupplyPress 46;
BA_ "SigType" SG_ 2566827774 PneumaticSupplyPress "RANGE";
BA_ "SPN" SG_ 2566846974 SteerAxleLubePress 2614;
BA_ "SigType" SG_ 2566846974 SteerAxleLubePress "RANGE";
BA_ "SPN" SG_ 2566846974 SteerAxleTemp 75;
BA_ "SigType" SG_ 2566846974 SteerAxleTemp "RANGE";
BA_ "SPN" SG_ 2566846974 DriveAxleLubePress 2613;
BA_ "SigType" SG_ 2566846974 DriveAxleLubePress "RANGE";
BA_ "SPN" SG_ 2566846974 DriveAxleTemp 578;
BA_ "SigType" SG_ 2566846974 DriveAxleTemp "RANGE";
BA_ "SPN" SG_ 2566846974 DriveAxleLiftAirPress 579;
BA_ "SigType" SG_ 2566846974 DriveAxleLiftAirPress "RANGE";
BA_ "SPN" SG_ 2566846974 DriveAxleLocation 930;
BA_ "SigType" SG_ 2566846974 DriveAxleLocation "RANGE";
BA_ "SPN" SG_ 2633935614 EngTurboWastegateValvePos 1693;
BA_ "SigType" SG_ 2633935614 EngTurboWastegateValvePos "RANGE";
BA_ "SPN" SG_ 2633935614 EngGsMssFlwSnsrFelingCorrection 1694;
BA_ "SigType" SG_ 2633935614 EngGsMssFlwSnsrFelingCorrection "RANGE";
BA_ "SPN" SG_ 2633935614 EngDsiredAbsIntakeManifoldPress 1692;
BA_ "SigType" SG_ 2633935614 EngDsiredAbsIntakeManifoldPress "RANGE";
BA_ "SPN" SG_ 2633935614 EngGasFuelCorrectionFactor 1116;
BA_ "SigType" SG_ 2633935614 EngGasFuelCorrectionFactor "RANGE";
BA_ "SPN" SG_ 2566803966 RqedACCDistanceMode 1799;
BA_ "SigType" SG_ 2566803966 RqedACCDistanceMode "DISCRETE";
BA_ "SPN" SG_ 2432593918 ACCDistanceAlertSignal 1796;
BA_ "SigType" SG_ 2432593918 ACCDistanceAlertSignal "DISCRETE";
BA_ "SPN" SG_ 2432593918 ACCSystemShutoffWarning 1797;
BA_ "SigType" SG_ 2432593918 ACCSystemShutoffWarning "DISCRETE";
BA_ "SPN" SG_ 2432593918 ACCTargetDetected 1798;
BA_ "SigType" SG_ 2432593918 ACCTargetDetected "DISCRETE";
BA_ "SPN" SG_ 2432593918 RoadCurvature 1591;
BA_ "SigType" SG_ 2432593918 RoadCurvature "RANGE";
BA_ "SPN" SG_ 2432593918 AdptveCruiseCtrlSetDistanceMode 1589;
BA_ "SigType" SG_ 2432593918 AdptveCruiseCtrlSetDistanceMode "DISCRETE";
BA_ "SPN" SG_ 2432593918 AdaptiveCruiseCtrlMode 1590;
BA_ "SigType" SG_ 2432593918 AdaptiveCruiseCtrlMode "DISCRETE";
BA_ "SPN" SG_ 2432593918 AdaptiveCruiseCtrlSetSpeed 1588;
BA_ "SigType" SG_ 2432593918 AdaptiveCruiseCtrlSetSpeed "RANGE";
BA_ "SPN" SG_ 2432593918 DistanceToForwardVehicle 1587;
BA_ "SigType" SG_ 2432593918 DistanceToForwardVehicle "RANGE";
BA_ "SPN" SG_ 2432593918 SpeedOfForwardVehicle 1586;
BA_ "SigType" SG_ 2432593918 SpeedOfForwardVehicle "RANGE";
BA_ "SPN" SG_ 2633935102 ArticulationAngle 1120;
BA_ "SigType" SG_ 2633935102 ArticulationAngle "RANGE";
BA_ "SPN" SG_ 2633927934 AuxLevel 3087;
BA_ "SigType" SG_ 2633927934 AuxLevel "RANGE";
BA_ "SPN" SG_ 2633927934 AuxPress2 1388;
BA_ "SigType" SG_ 2633927934 AuxPress2 "RANGE";
BA_ "SPN" SG_ 2633927934 AuxPress1 1387;
BA_ "SigType" SG_ 2633927934 AuxPress1 "RANGE";
BA_ "SPN" SG_ 2633927934 AuxTemp2 442;
BA_ "SigType" SG_ 2633927934 AuxTemp2 "RANGE";
BA_ "SPN" SG_ 2633927934 AuxTemp1 441;
BA_ "SigType" SG_ 2633927934 AuxTemp1 "RANGE";
BA_ "SPN" SG_ 2566847998 EngBlowerBypassValvePos 72;
BA_ "SigType" SG_ 2566847998 EngBlowerBypassValvePos "RANGE";
BA_ "SPN" SG_ 2566847998 EngGasSupplyPress 159;
BA_ "SigType" SG_ 2566847998 EngGasSupplyPress "RANGE";
BA_ "SPN" SG_ 2565406462 ControlByte 2541;
BA_ "SPN" SG_ 2565406462 ParameterGroupNumber 2574;
BA_ "SigType" SG_ 2565406462 ParameterGroupNumber "RANGE";
BA_ "SPN" SG_ 2565406462 GroupFunctionValue 2542;
BA_ "SigType" SG_ 2565406462 GroupFunctionValue "RANGE";
BA_ "SPN" SG_ 2566763262 PrtcltTrpIntrmdtGsTmpPrlmnryFMI 3254;
BA_ "SigType" SG_ 2566763262 PrtcltTrpIntrmdtGsTmpPrlmnryFMI "RANGE";
BA_ "SPN" SG_ 2566763262 PrtcltTrpDltPressPreliminaryFMI 3253;
BA_ "SigType" SG_ 2566763262 PrtcltTrpDltPressPreliminaryFMI "RANGE";
BA_ "SPN" SG_ 2566763262 ExhaustGasTemp2PreliminaryFMI 3252;
BA_ "SigType" SG_ 2566763262 ExhaustGasTemp2PreliminaryFMI "RANGE";
BA_ "SPN" SG_ 2566763262 ParticulateTrapDiffPress 3251;
BA_ "SigType" SG_ 2566763262 ParticulateTrapDiffPress "RANGE";
BA_ "SPN" SG_ 2566763262 PrtclateTrapIntermediateGasTemp 3250;
BA_ "SigType" SG_ 2566763262 PrtclateTrapIntermediateGasTemp "RANGE";
BA_ "SPN" SG_ 2566763262 ExhaustGasTemp2 3249;
BA_ "SigType" SG_ 2566763262 ExhaustGasTemp2 "RANGE";
BA_ "SPN" SG_ 2566803198 Status2OfDoors 3411;
BA_ "SigType" SG_ 2566803198 Status2OfDoors "DISCRETE";
BA_ "SPN" SG_ 2566803198 Ramp_WheelChairLiftPos 1820;
BA_ "SigType" SG_ 2566803198 Ramp_WheelChairLiftPos "DISCRETE";
BA_ "SPN" SG_ 2566803198 PosOfDoors 1821;
BA_ "SigType" SG_ 2566803198 PosOfDoors "DISCRETE";
BA_ "SPN" SG_ 2565870334 FifthWheelRollWarningIndicator 3317;
BA_ "SigType" SG_ 2565870334 FifthWheelRollWarningIndicator "DISCRETE";
BA_ "SPN" SG_ 2565870334 FifthWheelRollMoment 3310;
BA_ "SigType" SG_ 2565870334 FifthWheelRollMoment "RANGE";
BA_ "SPN" SG_ 2565870334 FifthWheelDrawbarForce 3309;
BA_ "SigType" SG_ 2565870334 FifthWheelDrawbarForce "RANGE";
BA_ "SPN" SG_ 2565870334 FifthWheelVerticalForce 3308;
BA_ "SigType" SG_ 2565870334 FifthWheelVerticalForce "RANGE";
BA_ "SPN" SG_ 2566762238 FifthWheelSliderLockIndicator 3316;
BA_ "SigType" SG_ 2566762238 FifthWheelSliderLockIndicator "DISCRETE";
BA_ "SPN" SG_ 2566762238 FifthWheelSliderPos 3311;
BA_ "SigType" SG_ 2566762238 FifthWheelSliderPos "RANGE";
BA_ "SPN" SG_ 2566762238 FfthWhlLckCoupleStatusIndicator 3313;
BA_ "SigType" SG_ 2566762238 FfthWhlLckCoupleStatusIndicator "DISCRETE";
BA_ "SPN" SG_ 2566762238 FfthWhlLckRadyToCoupleIndicator 3312;
BA_ "SigType" SG_ 2566762238 FfthWhlLckRadyToCoupleIndicator "DISCRETE";
BA_ "SPN" SG_ 2566762238 FifthWheelErrorStatus 3307;
BA_ "SigType" SG_ 2566762238 FifthWheelErrorStatus "DISCRETE";
BA_ "SPN" SG_ 2364543998 RollAndPitchMeasurementLatency 3327;
BA_ "SigType" SG_ 2364543998 RollAndPitchMeasurementLatency "RANGE";
BA_ "SPN" SG_ 2364543998 PitchAndRollCompensated 3326;
BA_ "SigType" SG_ 2364543998 PitchAndRollCompensated "DISCRETE";
BA_ "SPN" SG_ 2364543998 PitchRateFigureOfMerit 3325;
BA_ "SigType" SG_ 2364543998 PitchRateFigureOfMerit "DISCRETE";
BA_ "SPN" SG_ 2364543998 RollAngleFigureOfMerit 3324;
BA_ "SigType" SG_ 2364543998 RollAngleFigureOfMerit "DISCRETE";
BA_ "SPN" SG_ 2364543998 PitchAngleFigureOfMerit 3323;
BA_ "SigType" SG_ 2364543998 PitchAngleFigureOfMerit "DISCRETE";
BA_ "SPN" SG_ 2364543998 PitchRate 3322;
BA_ "SigType" SG_ 2364543998 PitchRate "RANGE";
BA_ "SPN" SG_ 2364543998 RollAngle 3319;
BA_ "SigType" SG_ 2364543998 RollAngle "RANGE";
BA_ "SPN" SG_ 2364543998 PitchAngle 3318;
BA_ "SigType" SG_ 2364543998 PitchAngle "RANGE";
BA_ "SPN" SG_ 2566846718 TransOilLevelMeasurementStatus 3026;
BA_ "SigType" SG_ 2566846718 TransOilLevelMeasurementStatus "DISCRETE";
BA_ "SPN" SG_ 2566846718 TransOilLevelCountdownTimer 3028;
BA_ "SigType" SG_ 2566846718 TransOilLevelCountdownTimer "DISCRETE";
BA_ "SPN" SG_ 2566846718 TransOilLevelHigh_Low 3027;
BA_ "SigType" SG_ 2566846718 TransOilLevelHigh_Low "RANGE";
BA_ "SPN" SG_ 2566846718 TransOilTemp 177;
BA_ "SigType" SG_ 2566846718 TransOilTemp "RANGE";
BA_ "SPN" SG_ 2566846718 TransOilPress 127;
BA_ "SigType" SG_ 2566846718 TransOilPress "RANGE";
BA_ "SPN" SG_ 2566846718 TransFilterDiffPress 126;
BA_ "SigType" SG_ 2566846718 TransFilterDiffPress "RANGE";
BA_ "SPN" SG_ 2566846718 TransOilLevel 124;
BA_ "SigType" SG_ 2566846718 TransOilLevel "RANGE";
BA_ "SPN" SG_ 2566846718 ClutchPress 123;
BA_ "SigType" SG_ 2566846718 ClutchPress "RANGE";
BA_ "SPN" SG_ 2566846462 BatteryPotentialSwitched 158;
BA_ "SigType" SG_ 2566846462 BatteryPotentialSwitched "RANGE";
BA_ "SPN" SG_ 2566846462 ElectricalPotential 168;
BA_ "SigType" SG_ 2566846462 ElectricalPotential "RANGE";
BA_ "SPN" SG_ 2566846462 ChargingSystemPotential 167;
BA_ "SigType" SG_ 2566846462 ChargingSystemPotential "RANGE";
BA_ "SPN" SG_ 2566846462 AltCurrent 115;
BA_ "SigType" SG_ 2566846462 AltCurrent "RANGE";
BA_ "SPN" SG_ 2566846462 NetBatteryCurrent 114;
BA_ "SigType" SG_ 2566846462 NetBatteryCurrent "RANGE";
BA_ "SPN" SG_ 2566760702 WrlessCommunicationNetworkType2 3446;
BA_ "SigType" SG_ 2566760702 WrlessCommunicationNetworkType2 "RANGE";
BA_ "SPN" SG_ 2566760702 NetworkSignalStrength2 3445;
BA_ "SigType" SG_ 2566760702 NetworkSignalStrength2 "RANGE";
BA_ "SPN" SG_ 2566760702 NetworkAntennaStatus2 3444;
BA_ "SigType" SG_ 2566760702 NetworkAntennaStatus2 "RANGE";
BA_ "SPN" SG_ 2566760702 NetworkServiceStatus2 3443;
BA_ "SigType" SG_ 2566760702 NetworkServiceStatus2 "RANGE";
BA_ "SPN" SG_ 2566760702 NetworkTransceiverStatus2 3442;
BA_ "SigType" SG_ 2566760702 NetworkTransceiverStatus2 "RANGE";
BA_ "SPN" SG_ 2566760958 WrlessCommunicationNetworkType1 3372;
BA_ "SigType" SG_ 2566760958 WrlessCommunicationNetworkType1 "RANGE";
BA_ "SPN" SG_ 2566760958 NetworkSignalStrength1 3371;
BA_ "SigType" SG_ 2566760958 NetworkSignalStrength1 "RANGE";
BA_ "SPN" SG_ 2566760958 NetworkAntennaStatus1 3370;
BA_ "SigType" SG_ 2566760958 NetworkAntennaStatus1 "RANGE";
BA_ "SPN" SG_ 2566760958 NetworkServiceStatus1 3369;
BA_ "SigType" SG_ 2566760958 NetworkServiceStatus1 "RANGE";
BA_ "SPN" SG_ 2566760958 NetworkTransceiverStatus1 3368;
BA_ "SigType" SG_ 2566760958 NetworkTransceiverStatus1 "RANGE";
BA_ "SPN" SG_ 2633869310 VoltageRegulatorEnabled 3379;
BA_ "SigType" SG_ 2633869310 VoltageRegulatorEnabled "DISCRETE";
BA_ "SPN" SG_ 2633869310 VoltageRegulatorSoftStartState 3378;
BA_ "SigType" SG_ 2633869310 VoltageRegulatorSoftStartState "DISCRETE";
BA_ "SPN" SG_ 2633869310 VltgRgltrUndrfrqncyCmpnstnEnbld 3377;
BA_ "SigType" SG_ 2633869310 VltgRgltrUndrfrqncyCmpnstnEnbld "DISCRETE";
BA_ "SPN" SG_ 2633869310 VltgRgltrVAr_PwrFctrOprtingMode 3376;
BA_ "SigType" SG_ 2633869310 VltgRgltrVAr_PwrFctrOprtingMode "DISCRETE";
BA_ "SPN" SG_ 2633869310 VltgRglatorLoadCompensationMode 3375;
BA_ "SigType" SG_ 2633869310 VltgRglatorLoadCompensationMode "DISCRETE";
BA_ "SPN" SG_ 2365433598 GnrtrOtputVoltageBiasPercentage 3382;
BA_ "SigType" SG_ 2365433598 GnrtrOtputVoltageBiasPercentage "RANGE";
BA_ "SPN" SG_ 2365433598 GeneratorExcitationFieldCurrent 3381;
BA_ "SigType" SG_ 2365433598 GeneratorExcitationFieldCurrent "RANGE";
BA_ "SPN" SG_ 2365433598 GeneratorExcitationFieldVoltage 3380;
BA_ "SigType" SG_ 2365433598 GeneratorExcitationFieldVoltage "RANGE";
VAL_ 2566838526 IndustryGroup 7 "Reserve for SAE" 5 "IndustrialProcessCtrlStationary" 4 "Marine" 3 "Construction" 2 "Agricultural and Forestry" 1 "On-Highway" 0 "Global" ;
VAL_ 2565799678 IndustryGroup 7 "Reserve for SAE" 5 "IndustrialProcessCtrlStationary" 4 "Marine" 3 "Construction" 2 "Agricultural and Forestry" 1 "On-Highway" 0 "Global" ;
VAL_ 2565668606 PGNumber 255 "NotAvailable" ;
VAL_ 2565668606 ControlByte 24 "EAbort" 23 "EEoMACK" 22 "EDPO" 21 "ECTS" 20 "ERTS" 255 "Abort" 32 "BAM" 19 "EoMA" 17 "CTS" 16 "RTS" ;
VAL_ 2563374846 UseTransferMode 3 "NA" 2 "Undefined" 1 "Yes" 0 "No" ;
VAL_ 2566750462 FailureModeIdentifier5 31 "Not available" 19 "Received network data in error" 18 "Below normal (moderatels severe)" 17 "Below normal (least severe)" 16 "Above normal (moderately severe)" 15 "Above normal (least severe)" 14 "Special intstructions" 13 "Out of calibration" 12 "Bad intelligent device" 11 "Root cause not known" 10 "Abnormal rate of change" 9 "Abnormal update rate" 8 "Abnormal frequency" 7 "Mechanical system not responding" 6 "Current above normal" 5 "Current below normal" 4 "Voltage below normal" 3 "Voltage above normal" 2 "Data erratic" 1 "Below normal (most severe)" 0 "Above normal (most severe)" ;
VAL_ 2566750462 FailureModeIdentifier4 31 "Not available" 19 "Received network data in error" 18 "Below normal (moderatels severe)" 17 "Below normal (least severe)" 16 "Above normal (moderately severe)" 15 "Above normal (least severe)" 14 "Special intstructions" 13 "Out of calibration" 12 "Bad intelligent device" 11 "Root cause not known" 10 "Abnormal rate of change" 9 "Abnormal update rate" 8 "Abnormal frequency" 7 "Mechanical system not responding" 6 "Current above normal" 5 "Current below normal" 4 "Voltage below normal" 3 "Voltage above normal" 2 "Data erratic" 1 "Below normal (most severe)" 0 "Above normal (most severe)" ;
VAL_ 2566750462 FailureModeIdentifier3 31 "Not available" 19 "Received network data in error" 18 "Below normal (moderatels severe)" 17 "Below normal (least severe)" 16 "Above normal (moderately severe)" 15 "Above normal (least severe)" 14 "Special intstructions" 13 "Out of calibration" 12 "Bad intelligent device" 11 "Root cause not known" 10 "Abnormal rate of change" 9 "Abnormal update rate" 8 "Abnormal frequency" 7 "Mechanical system not responding" 6 "Current above normal" 5 "Current below normal" 4 "Voltage below normal" 3 "Voltage above normal" 2 "Data erratic" 1 "Below normal (most severe)" 0 "Above normal (most severe)" ;
VAL_ 2566750462 FlashRedStopLamp 3 "Unavailable / Do Not Flash" 2 "Reserved" 1 "Fast Flash" 0 "Slow Flash" ;
VAL_ 2566750462 FlashProtectLamp 3 "Unavailable / Do Not Flash" 2 "Reserved" 1 "Fast Flash" 0 "Slow Flash" ;
VAL_ 2566750462 FlashMalfuncIndicatorLamp 3 "Unavailable / Do Not Flash" 2 "Reserved" 1 "Fast Flash" 0 "Slow Flash" ;
VAL_ 2566750462 FlashAmberWarningLamp 3 "Unavailable / Do Not Flash" 2 "Reserved" 1 "Fast Flash" 0 "Slow Flash" ;
VAL_ 2566750462 MalfunctionIndicatorLampStatus 3 "Not available" 2 "Reserved" 1 "Lamp on" 0 "Lamp off" ;
VAL_ 2566750462 AmberWarningLampStatus 3 "Not available" 2 "Reserved" 1 "Lamp on" 0 "Lamp off" ;
VAL_ 2566750462 FailureModeIdentifier1 31 "Not available" 19 "Received network data in error" 18 "Below normal (moderatels severe)" 17 "Below normal (least severe)" 16 "Above normal (moderately severe)" 15 "Above normal (least severe)" 14 "Special intstructions" 13 "Out of calibration" 12 "Bad intelligent device" 11 "Root cause not known" 10 "Abnormal rate of change" 9 "Abnormal update rate" 8 "Abnormal frequency" 7 "Mechanical system not responding" 6 "Current above normal" 5 "Current below normal" 4 "Voltage below normal" 3 "Voltage above normal" 2 "Data erratic" 1 "Below normal (most severe)" 0 "Above normal (most severe)" ;
VAL_ 2566750462 RedStopLampState 3 "Not available" 2 "Reserved" 1 "Lamp on" 0 "Lamp off" ;
VAL_ 2566750462 ProtectLampStatus 3 "Not available" 2 "Reserved" 1 "Lamp on" 0 "Lamp off" ;
VAL_ 2566750462 FailureModeIdentifier2 31 "Not available" 19 "Received network data in error" 18 "Below normal (moderatels severe)" 17 "Below normal (least severe)" 16 "Above normal (moderately severe)" 15 "Above normal (least severe)" 14 "Special intstructions" 13 "Out of calibration" 12 "Bad intelligent device" 11 "Root cause not known" 10 "Abnormal rate of change" 9 "Abnormal update rate" 8 "Abnormal frequency" 7 "Mechanical system not responding" 6 "Current above normal" 5 "Current below normal" 4 "Voltage below normal" 3 "Voltage above normal" 2 "Data erratic" 1 "Below normal (most severe)" 0 "Above normal (most severe)" ;
VAL_ 2566750974 FailureModeIdentifier5 31 "Not available" 19 "Received network data in error" 18 "Below normal (moderatels severe)" 17 "Below normal (least severe)" 16 "Above normal (moderately severe)" 15 "Above normal (least severe)" 14 "Special intstructions" 13 "Out of calibration" 12 "Bad intelligent device" 11 "Root cause not known" 10 "Abnormal rate of change" 9 "Abnormal update rate" 8 "Abnormal frequency" 7 "Mechanical system not responding" 6 "Current above normal" 5 "Current below normal" 4 "Voltage below normal" 3 "Voltage above normal" 2 "Data erratic" 1 "Below normal (most severe)" 0 "Above normal (most severe)" ;
VAL_ 2566750974 FailureModeIdentifier4 31 "Not available" 19 "Received network data in error" 18 "Below normal (moderatels severe)" 17 "Below normal (least severe)" 16 "Above normal (moderately severe)" 15 "Above normal (least severe)" 14 "Special intstructions" 13 "Out of calibration" 12 "Bad intelligent device" 11 "Root cause not known" 10 "Abnormal rate of change" 9 "Abnormal update rate" 8 "Abnormal frequency" 7 "Mechanical system not responding" 6 "Current above normal" 5 "Current below normal" 4 "Voltage below normal" 3 "Voltage above normal" 2 "Data erratic" 1 "Below normal (most severe)" 0 "Above normal (most severe)" ;
VAL_ 2566750974 FailureModeIdentifier3 31 "Not available" 19 "Received network data in error" 18 "Below normal (moderatels severe)" 17 "Below normal (least severe)" 16 "Above normal (moderately severe)" 15 "Above normal (least severe)" 14 "Special intstructions" 13 "Out of calibration" 12 "Bad intelligent device" 11 "Root cause not known" 10 "Abnormal rate of change" 9 "Abnormal update rate" 8 "Abnormal frequency" 7 "Mechanical system not responding" 6 "Current above normal" 5 "Current below normal" 4 "Voltage below normal" 3 "Voltage above normal" 2 "Data erratic" 1 "Below normal (most severe)" 0 "Above normal (most severe)" ;
VAL_ 2566750974 FlashRedStopLamp 3 "Unavailable / Do Not Flash" 2 "Reserved" 1 "Fast Flash" 0 "Slow Flash" ;
VAL_ 2566750974 FlashProtectLamp 3 "Unavailable / Do Not Flash" 2 "Reserved" 1 "Fast Flash" 0 "Slow Flash" ;
VAL_ 2566750974 FlashMalfuncIndicatorLamp 3 "Unavailable / Do Not Flash" 2 "Reserved" 1 "Fast Flash" 0 "Slow Flash" ;
VAL_ 2566750974 FlashAmberWarningLamp 3 "Unavailable / Do Not Flash" 2 "Reserved" 1 "Fast Flash" 0 "Slow Flash" ;
VAL_ 2566750974 MalfunctionIndicatorLampStatus 3 "Not available" 2 "Reserved" 1 "Lamp on" 0 "Lamp off" ;
VAL_ 2566750974 AmberWarningLampStatus 3 "Not available" 2 "Reserved" 1 "Lamp on" 0 "Lamp off" ;
VAL_ 2566750974 FailureModeIdentifier1 31 "Not available" 19 "Received network data in error" 18 "Below normal (moderatels severe)" 17 "Below normal (least severe)" 16 "Above normal (moderately severe)" 15 "Above normal (least severe)" 14 "Special intstructions" 13 "Out of calibration" 12 "Bad intelligent device" 11 "Root cause not known" 10 "Abnormal rate of change" 9 "Abnormal update rate" 8 "Abnormal frequency" 7 "Mechanical system not responding" 6 "Current above normal" 5 "Current below normal" 4 "Voltage below normal" 3 "Voltage above normal" 2 "Data erratic" 1 "Below normal (most severe)" 0 "Above normal (most severe)" ;
VAL_ 2566750974 RedStopLampState 3 "Not available" 2 "Reserved" 1 "Lamp on" 0 "Lamp off" ;
VAL_ 2566750974 ProtectLampStatus 3 "Not available" 2 "Reserved" 1 "Lamp on" 0 "Lamp off" ;
VAL_ 2566750974 FailureModeIdentifier2 31 "Not available" 19 "Received network data in error" 18 "Below normal (moderatels severe)" 17 "Below normal (least severe)" 16 "Above normal (moderately severe)" 15 "Above normal (least severe)" 14 "Special intstructions" 13 "Out of calibration" 12 "Bad intelligent device" 11 "Root cause not known" 10 "Abnormal rate of change" 9 "Abnormal update rate" 8 "Abnormal frequency" 7 "Mechanical system not responding" 6 "Current above normal" 5 "Current below normal" 4 "Voltage below normal" 3 "Voltage above normal" 2 "Data erratic" 1 "Below normal (most severe)" 0 "Above normal (most severe)" ;
VAL_ 2566754558 AETCDataCollectionStandard 15 "NotAvailable" 1 "1101NotDefined" 0 "SAEJ1995" ;
VAL_ 2566749950 RightHeadlampLightDistribution 15 "NotAvailable" 8 "1110Reserved" 7 "DffrntLghtDstrbtnsNtAvlblNAFSDs" 6 "LghtDstrbtnFlrMdlIsDmgdCrrntPsM" 5 "LghtDstrbtnFlSfPsMdlIsDmgdCrrnt" 4 "LghtDstrbtnAdvrsWthrAdvrsWthrLg" 3 "LghtDstrbtnHghBmHghBmDstrbtnOfT" 2 "LghtDstrbtnMtrwyTskOfMtrwyLghtI" 1 "LghtDstrbtnCntryCntryLghtIsMstl" 0 "LghtDstrbtnTwnBscLghtDstrbtnFrT" ;
VAL_ 2566749950 LeftHeadlampLightDistribution 15 "NotAvailable" 8 "1110Reserved" 7 "DffrntLghtDstrbtnsNtAvlblNAFSDs" 6 "LghtDstrbtnFlrMdlIsDmgdCrrntPsM" 5 "LghtDstrbtnFlSfPsMdlIsDmgdCrrnt" 4 "LghtDstrbtnAdvrsWthrAdvrsWthrLg" 3 "LghtDstrbtnHghBmHghBmDstrbtnOfT" 2 "LghtDstrbtnMtrwyTskOfMtrwyLghtI" 1 "LghtDstrbtnCntryCntryLghtIsMstl" 0 "LghtDstrbtnTwnBscLghtDstrbtnFrT" ;
VAL_ 2566749950 RghtHeadlampDynamicBendingLight 7 "NotAvailable" 4 "110Reserved" 3 "DynmcBndngLghtFlrBndngLghtDsNtW" 2 "DynmcBndngLghtFlSfPsBndngLghtIs" 1 "DynmcBndngLghtIsWrkngPrprlyNrml" 0 "DynmcBndngLghtDctvtdThrIsNPrblm" ;
VAL_ 2566749950 LeftHeadlampDynamicBendingLight 7 "NotAvailable" 4 "110Reserved" 3 "DynmcBndngLghtFlrBndngLghtDsNtW" 2 "DynmcBndngLghtFlSfPsBndngLghtIs" 1 "DynmcBndngLghtIsWrkngPrprlyNrml" 0 "DynmcBndngLghtDctvtdThrIsNPrblm" ;
VAL_ 2565869310 Aftrtrtmnt1IntkGsSnsrHeaterCtrl 3 "HeaterOff" 2 "Preheat1" 1 "Preheat2" 0 "Automatic" ;
VAL_ 2565869310 Aftrtrtmnt1IntkWdRngO2RdngStble 3 "NotAvailable" 2 "Error" 1 "Stable" 0 "NotStable" ;
VAL_ 2565869310 Aftrtrtmnt1IntkNOxReadingStable 3 "NotAvailable" 2 "Error" 1 "Stable" 0 "NotStable" ;
VAL_ 2565869310 Aftrtrtmnt1IntkGsSnsrPwrInRange 3 "NotAvailable" 2 "Error" 1 "InRange" 0 "NotInRange" ;
VAL_ 2565869566 Aftrtrtmnt1OtltGsSnsrHeaterCtrl 3 "HeaterOff" 2 "Preheat1" 1 "Preheat2" 0 "Automatic" ;
VAL_ 2565869566 Aftrtrtmnt1OtltWdRngO2RdngStble 3 "NotAvailable" 2 "Error" 1 "Stable" 0 "NotStable" ;
VAL_ 2565869566 Aftrtrtmnt1OtltNOxReadingStable 3 "NotAvailable" 2 "Error" 1 "Stable" 0 "NotStable" ;
VAL_ 2565869566 Aftrtrtmnt1OtletGasSensorAtTemp 3 "NotAvailable" 2 "Error" 1 "InRange" 0 "NotInRange" ;
VAL_ 2565869566 Aftrtrtmnt1OtltGsSnsrPwrInRange 3 "NotAvailable" 2 "Error" 1 "InRange" 0 "NotInRange" ;
VAL_ 2565869822 Aftrtrtmnt2IntkGsSnsrHeaterCtrl 3 "HeaterOff" 2 "Preheat1" 1 "Preheat2" 0 "Automatic" ;
VAL_ 2565869822 Aftrtrtmnt2IntkWdRngO2RdngStble 3 "NotAvailable" 2 "Error" 1 "Stable" 0 "NotStable" ;
VAL_ 2565869822 Aftrtrtmnt2IntkNOxReadingStable 3 "NotAvailable" 2 "Error" 1 "Stable" 0 "NotStable" ;
VAL_ 2565869822 Aftrtrtmnt2IntkeGasSensorAtTemp 3 "NotAvailable" 2 "Error" 1 "InRange" 0 "NotInRange" ;
VAL_ 2565869822 Aftrtrtmnt2IntkGsSnsrPwrInRange 3 "NotAvailable" 2 "Error" 1 "InRange" 0 "NotInRange" ;
VAL_ 2565870078 Aftrtrtmnt2OtltGsSnsrHeaterCtrl 3 "HeaterOff" 2 "Preheat1" 1 "Preheat2" 0 "Automatic" ;
VAL_ 2565870078 Aftrtrtmnt2OtltWdRngO2RdngStble 3 "NotAvailable" 2 "Error" 1 "Stable" 0 "NotStable" ;
VAL_ 2565870078 Aftrtrtmnt2OtltNOxReadingStable 3 "NotAvailable" 2 "Error" 1 "Stable" 0 "NotStable" ;
VAL_ 2565870078 Aftrtrtmnt2OtletGasSensorAtTemp 3 "NotAvailable" 2 "Error" 1 "InRange" 0 "NotInRange" ;
VAL_ 2565870078 Aftrtrtmnt2OtltGsSnsrPwrInRange 3 "NotAvailable" 2 "Error" 1 "InRange" 0 "NotInRange" ;
VAL_ 2566749182 ParticulateTrap1AshLoadPercent 4 "LevelIsTargetAshServiceInterval" ;
VAL_ 2566749182 ParticulateTrap1SootLoadPercent 4 "LvlIsActvRgnerationTriggerLevel" ;
VAL_ 2566748926 ParticulateTrap2AshLoadPercent 4 "LevelIsTargetAshServiceInterval" ;
VAL_ 2566748926 ParticulateTrap2SootLoadPercent 4 "LvlIsActvRgnerationTriggerLevel" ;
VAL_ 2561146622 AuxI_O45 3 "NtAvlblTkNoActionDependingOnApp" 2 "ErrrIndctrNotUsedDependingOnApp" 1 "AuxChannelOn" 0 "AuxChannelOff" ;
VAL_ 2561146622 AuxI_O46 3 "NtAvlblTkNoActionDependingOnApp" 2 "ErrrIndctrNotUsedDependingOnApp" 1 "AuxChannelOn" 0 "AuxChannelOff" ;
VAL_ 2561146622 AuxI_O47 3 "NtAvlblTkNoActionDependingOnApp" 2 "ErrrIndctrNotUsedDependingOnApp" 1 "AuxChannelOn" 0 "AuxChannelOff" ;
VAL_ 2561146622 AuxI_O48 3 "NtAvlblTkNoActionDependingOnApp" 2 "ErrrIndctrNotUsedDependingOnApp" 1 "AuxChannelOn" 0 "AuxChannelOff" ;
VAL_ 2561146622 AuxI_O41 3 "NtAvlblTkNoActionDependingOnApp" 2 "ErrrIndctrNotUsedDependingOnApp" 1 "AuxChannelOn" 0 "AuxChannelOff" ;
VAL_ 2561146622 AuxI_O42 3 "NtAvlblTkNoActionDependingOnApp" 2 "ErrrIndctrNotUsedDependingOnApp" 1 "AuxChannelOn" 0 "AuxChannelOff" ;
VAL_ 2561146622 AuxI_O43 3 "NtAvlblTkNoActionDependingOnApp" 2 "ErrrIndctrNotUsedDependingOnApp" 1 "AuxChannelOn" 0 "AuxChannelOff" ;
VAL_ 2561146622 AuxI_O44 3 "NtAvlblTkNoActionDependingOnApp" 2 "ErrrIndctrNotUsedDependingOnApp" 1 "AuxChannelOn" 0 "AuxChannelOff" ;
VAL_ 2561146622 AuxI_O37 3 "NtAvlblTkNoActionDependingOnApp" 2 "ErrrIndctrNotUsedDependingOnApp" 1 "AuxChannelOn" 0 "AuxChannelOff" ;
VAL_ 2561146622 AuxI_O38 3 "NtAvlblTkNoActionDependingOnApp" 2 "ErrrIndctrNotUsedDependingOnApp" 1 "AuxChannelOn" 0 "AuxChannelOff" ;
VAL_ 2561146622 AuxI_O39 3 "NtAvlblTkNoActionDependingOnApp" 2 "ErrrIndctrNotUsedDependingOnApp" 1 "AuxChannelOn" 0 "AuxChannelOff" ;
VAL_ 2561146622 AuxI_O40 3 "NtAvlblTkNoActionDependingOnApp" 2 "ErrrIndctrNotUsedDependingOnApp" 1 "AuxChannelOn" 0 "AuxChannelOff" ;
VAL_ 2561146622 AuxI_O33 3 "NtAvlblTkNoActionDependingOnApp" 2 "ErrrIndctrNotUsedDependingOnApp" 1 "AuxChannelOn" 0 "AuxChannelOff" ;
VAL_ 2561146622 AuxI_O34 3 "NtAvlblTkNoActionDependingOnApp" 2 "ErrrIndctrNotUsedDependingOnApp" 1 "AuxChannelOn" 0 "AuxChannelOff" ;
VAL_ 2561146622 AuxI_O35 3 "NtAvlblTkNoActionDependingOnApp" 2 "ErrrIndctrNotUsedDependingOnApp" 1 "AuxChannelOn" 0 "AuxChannelOff" ;
VAL_ 2561146622 AuxI_O36 3 "NtAvlblTkNoActionDependingOnApp" 2 "ErrrIndctrNotUsedDependingOnApp" 1 "AuxChannelOn" 0 "AuxChannelOff" ;
VAL_ 2561146622 AuxI_O29 3 "NtAvlblTkNoActionDependingOnApp" 2 "ErrrIndctrNotUsedDependingOnApp" 1 "AuxChannelOn" 0 "AuxChannelOff" ;
VAL_ 2561146622 AuxI_O30 3 "NtAvlblTkNoActionDependingOnApp" 2 "ErrrIndctrNotUsedDependingOnApp" 1 "AuxChannelOn" 0 "AuxChannelOff" ;
VAL_ 2561146622 AuxI_O31 3 "NtAvlblTkNoActionDependingOnApp" 2 "ErrrIndctrNotUsedDependingOnApp" 1 "AuxChannelOn" 0 "AuxChannelOff" ;
VAL_ 2561146622 AuxI_O32 3 "NtAvlblTkNoActionDependingOnApp" 2 "ErrrIndctrNotUsedDependingOnApp" 1 "AuxChannelOn" 0 "AuxChannelOff" ;
VAL_ 2561146622 AuxI_O25 3 "NtAvlblTkNoActionDependingOnApp" 2 "ErrrIndctrNotUsedDependingOnApp" 1 "AuxChannelOn" 0 "AuxChannelOff" ;
VAL_ 2561146622 AuxI_O26 3 "NtAvlblTkNoActionDependingOnApp" 2 "ErrrIndctrNotUsedDependingOnApp" 1 "AuxChannelOn" 0 "AuxChannelOff" ;
VAL_ 2561146622 AuxI_O27 3 "NtAvlblTkNoActionDependingOnApp" 2 "ErrrIndctrNotUsedDependingOnApp" 1 "AuxChannelOn" 0 "AuxChannelOff" ;
VAL_ 2561146622 AuxI_O28 3 "NtAvlblTkNoActionDependingOnApp" 2 "ErrrIndctrNotUsedDependingOnApp" 1 "AuxChannelOn" 0 "AuxChannelOff" ;
VAL_ 2561146622 AuxI_O21 3 "NtAvlblTkNoActionDependingOnApp" 2 "ErrrIndctrNotUsedDependingOnApp" 1 "AuxChannelOn" 0 "AuxChannelOff" ;
VAL_ 2561146622 AuxI_O22 3 "NtAvlblTkNoActionDependingOnApp" 2 "ErrrIndctrNotUsedDependingOnApp" 1 "AuxChannelOn" 0 "AuxChannelOff" ;
VAL_ 2561146622 AuxI_O23 3 "NtAvlblTkNoActionDependingOnApp" 2 "ErrrIndctrNotUsedDependingOnApp" 1 "AuxChannelOn" 0 "AuxChannelOff" ;
VAL_ 2561146622 AuxI_O24 3 "NtAvlblTkNoActionDependingOnApp" 2 "ErrrIndctrNotUsedDependingOnApp" 1 "AuxChannelOn" 0 "AuxChannelOff" ;
VAL_ 2561146622 AuxI_O17 3 "NtAvlblTkNoActionDependingOnApp" 2 "ErrrIndctrNotUsedDependingOnApp" 1 "AuxChannelOn" 0 "AuxChannelOff" ;
VAL_ 2561146622 AuxI_O18 3 "NtAvlblTkNoActionDependingOnApp" 2 "ErrrIndctrNotUsedDependingOnApp" 1 "AuxChannelOn" 0 "AuxChannelOff" ;
VAL_ 2561146622 AuxI_O19 3 "NtAvlblTkNoActionDependingOnApp" 2 "ErrrIndctrNotUsedDependingOnApp" 1 "AuxChannelOn" 0 "AuxChannelOff" ;
VAL_ 2561146622 AuxI_O20 3 "NtAvlblTkNoActionDependingOnApp" 2 "ErrrIndctrNotUsedDependingOnApp" 1 "AuxChannelOn" 0 "AuxChannelOff" ;
VAL_ 2561081086 AuxI_O77 3 "NtAvlblTkNoActionDependingOnApp" 2 "ErrrIndctrNotUsedDependingOnApp" 1 "AuxChannelOn" 0 "AuxChannelOff" ;
VAL_ 2561081086 AuxI_O78 3 "NtAvlblTkNoActionDependingOnApp" 2 "ErrrIndctrNotUsedDependingOnApp" 1 "AuxChannelOn" 0 "AuxChannelOff" ;
VAL_ 2561081086 AuxI_O79 3 "NtAvlblTkNoActionDependingOnApp" 2 "ErrrIndctrNotUsedDependingOnApp" 1 "AuxChannelOn" 0 "AuxChannelOff" ;
VAL_ 2561081086 AuxI_O80 3 "NtAvlblTkNoActionDependingOnApp" 2 "ErrrIndctrNotUsedDependingOnApp" 1 "AuxChannelOn" 0 "AuxChannelOff" ;
VAL_ 2561081086 AuxI_O73 3 "NtAvlblTkNoActionDependingOnApp" 2 "ErrrIndctrNotUsedDependingOnApp" 1 "AuxChannelOn" 0 "AuxChannelOff" ;
VAL_ 2561081086 AuxI_O74 3 "NtAvlblTkNoActionDependingOnApp" 2 "ErrrIndctrNotUsedDependingOnApp" 1 "AuxChannelOn" 0 "AuxChannelOff" ;
VAL_ 2561081086 AuxI_O75 3 "NtAvlblTkNoActionDependingOnApp" 2 "ErrrIndctrNotUsedDependingOnApp" 1 "AuxChannelOn" 0 "AuxChannelOff" ;
VAL_ 2561081086 AuxI_O76 3 "NtAvlblTkNoActionDependingOnApp" 2 "ErrrIndctrNotUsedDependingOnApp" 1 "AuxChannelOn" 0 "AuxChannelOff" ;
VAL_ 2561081086 AuxI_O69 3 "NtAvlblTkNoActionDependingOnApp" 2 "ErrrIndctrNotUsedDependingOnApp" 1 "AuxChannelOn" 0 "AuxChannelOff" ;
VAL_ 2561081086 AuxI_O70 3 "NtAvlblTkNoActionDependingOnApp" 2 "ErrrIndctrNotUsedDependingOnApp" 1 "AuxChannelOn" 0 "AuxChannelOff" ;
VAL_ 2561081086 AuxI_O71 3 "NtAvlblTkNoActionDependingOnApp" 2 "ErrrIndctrNotUsedDependingOnApp" 1 "AuxChannelOn" 0 "AuxChannelOff" ;
VAL_ 2561081086 AuxI_O72 3 "NtAvlblTkNoActionDependingOnApp" 2 "ErrrIndctrNotUsedDependingOnApp" 1 "AuxChannelOn" 0 "AuxChannelOff" ;
VAL_ 2561081086 AuxI_O65 3 "NtAvlblTkNoActionDependingOnApp" 2 "ErrrIndctrNotUsedDependingOnApp" 1 "AuxChannelOn" 0 "AuxChannelOff" ;
VAL_ 2561081086 AuxI_O66 3 "NtAvlblTkNoActionDependingOnApp" 2 "ErrrIndctrNotUsedDependingOnApp" 1 "AuxChannelOn" 0 "AuxChannelOff" ;
VAL_ 2561081086 AuxI_O67 3 "NtAvlblTkNoActionDependingOnApp" 2 "ErrrIndctrNotUsedDependingOnApp" 1 "AuxChannelOn" 0 "AuxChannelOff" ;
VAL_ 2561081086 AuxI_O68 3 "NtAvlblTkNoActionDependingOnApp" 2 "ErrrIndctrNotUsedDependingOnApp" 1 "AuxChannelOn" 0 "AuxChannelOff" ;
VAL_ 2561081086 AuxI_O61 3 "NtAvlblTkNoActionDependingOnApp" 2 "ErrrIndctrNotUsedDependingOnApp" 1 "AuxChannelOn" 0 "AuxChannelOff" ;
VAL_ 2561081086 AuxI_O62 3 "NtAvlblTkNoActionDependingOnApp" 2 "ErrrIndctrNotUsedDependingOnApp" 1 "AuxChannelOn" 0 "AuxChannelOff" ;
VAL_ 2561081086 AuxI_O63 3 "NtAvlblTkNoActionDependingOnApp" 2 "ErrrIndctrNotUsedDependingOnApp" 1 "AuxChannelOn" 0 "AuxChannelOff" ;
VAL_ 2561081086 AuxI_O64 3 "NtAvlblTkNoActionDependingOnApp" 2 "ErrrIndctrNotUsedDependingOnApp" 1 "AuxChannelOn" 0 "AuxChannelOff" ;
VAL_ 2561081086 AuxI_O57 3 "NtAvlblTkNoActionDependingOnApp" 2 "ErrrIndctrNotUsedDependingOnApp" 1 "AuxChannelOn" 0 "AuxChannelOff" ;
VAL_ 2561081086 AuxI_O58 3 "NtAvlblTkNoActionDependingOnApp" 2 "ErrrIndctrNotUsedDependingOnApp" 1 "AuxChannelOn" 0 "AuxChannelOff" ;
VAL_ 2561081086 AuxI_O59 3 "NtAvlblTkNoActionDependingOnApp" 2 "ErrrIndctrNotUsedDependingOnApp" 1 "AuxChannelOn" 0 "AuxChannelOff" ;
VAL_ 2561081086 AuxI_O60 3 "NtAvlblTkNoActionDependingOnApp" 2 "ErrrIndctrNotUsedDependingOnApp" 1 "AuxChannelOn" 0 "AuxChannelOff" ;
VAL_ 2561081086 AuxI_O53 3 "NtAvlblTkNoActionDependingOnApp" 2 "ErrrIndctrNotUsedDependingOnApp" 1 "AuxChannelOn" 0 "AuxChannelOff" ;
VAL_ 2561081086 AuxI_O54 3 "NtAvlblTkNoActionDependingOnApp" 2 "ErrrIndctrNotUsedDependingOnApp" 1 "AuxChannelOn" 0 "AuxChannelOff" ;
VAL_ 2561081086 AuxI_O55 3 "NtAvlblTkNoActionDependingOnApp" 2 "ErrrIndctrNotUsedDependingOnApp" 1 "AuxChannelOn" 0 "AuxChannelOff" ;
VAL_ 2561081086 AuxI_O56 3 "NtAvlblTkNoActionDependingOnApp" 2 "ErrrIndctrNotUsedDependingOnApp" 1 "AuxChannelOn" 0 "AuxChannelOff" ;
VAL_ 2561081086 AuxI_O49 3 "NtAvlblTkNoActionDependingOnApp" 2 "ErrrIndctrNotUsedDependingOnApp" 1 "AuxChannelOn" 0 "AuxChannelOff" ;
VAL_ 2561081086 AuxI_O50 3 "NtAvlblTkNoActionDependingOnApp" 2 "ErrrIndctrNotUsedDependingOnApp" 1 "AuxChannelOn" 0 "AuxChannelOff" ;
VAL_ 2561081086 AuxI_O51 3 "NtAvlblTkNoActionDependingOnApp" 2 "ErrrIndctrNotUsedDependingOnApp" 1 "AuxChannelOn" 0 "AuxChannelOff" ;
VAL_ 2561081086 AuxI_O52 3 "NtAvlblTkNoActionDependingOnApp" 2 "ErrrIndctrNotUsedDependingOnApp" 1 "AuxChannelOn" 0 "AuxChannelOff" ;
VAL_ 2561015550 AuxI_O92 3 "NtAvlblTkNoActionDependingOnApp" 2 "ErrrIndctrNotUsedDependingOnApp" 1 "AuxChannelOn" 0 "AuxChannelOff" ;
VAL_ 2561015550 AuxI_O85 3 "NtAvlblTkNoActionDependingOnApp" 2 "ErrrIndctrNotUsedDependingOnApp" 1 "AuxChannelOn" 0 "AuxChannelOff" ;
VAL_ 2561015550 AuxI_O86 3 "NtAvlblTkNoActionDependingOnApp" 2 "ErrrIndctrNotUsedDependingOnApp" 1 "AuxChannelOn" 0 "AuxChannelOff" ;
VAL_ 2561015550 AuxI_O87 3 "NtAvlblTkNoActionDependingOnApp" 2 "ErrrIndctrNotUsedDependingOnApp" 1 "AuxChannelOn" 0 "AuxChannelOff" ;
VAL_ 2561015550 AuxI_O88 3 "NtAvlblTkNoActionDependingOnApp" 2 "ErrrIndctrNotUsedDependingOnApp" 1 "AuxChannelOn" 0 "AuxChannelOff" ;
VAL_ 2561015550 AuxI_O81 3 "NtAvlblTkNoActionDependingOnApp" 2 "ErrrIndctrNotUsedDependingOnApp" 1 "AuxChannelOn" 0 "AuxChannelOff" ;
VAL_ 2561015550 AuxI_O82 3 "NtAvlblTkNoActionDependingOnApp" 2 "ErrrIndctrNotUsedDependingOnApp" 1 "AuxChannelOn" 0 "AuxChannelOff" ;
VAL_ 2561015550 AuxI_O83 3 "NtAvlblTkNoActionDependingOnApp" 2 "ErrrIndctrNotUsedDependingOnApp" 1 "AuxChannelOn" 0 "AuxChannelOff" ;
VAL_ 2561015550 AuxI_O84 3 "NtAvlblTkNoActionDependingOnApp" 2 "ErrrIndctrNotUsedDependingOnApp" 1 "AuxChannelOn" 0 "AuxChannelOff" ;
VAL_ 2561015550 AuxI_O109 3 "NtAvlblTkNoActionDependingOnApp" 2 "ErrrIndctrNotUsedDependingOnApp" 1 "AuxChannelOn" 0 "AuxChannelOff" ;
VAL_ 2561015550 AuxI_O110 3 "NtAvlblTkNoActionDependingOnApp" 2 "ErrrIndctrNotUsedDependingOnApp" 1 "AuxChannelOn" 0 "AuxChannelOff" ;
VAL_ 2561015550 AuxI_O111 3 "NtAvlblTkNoActionDependingOnApp" 2 "ErrrIndctrNotUsedDependingOnApp" 1 "AuxChannelOn" 0 "AuxChannelOff" ;
VAL_ 2561015550 AuxI_O112 3 "NtAvlblTkNoActionDependingOnApp" 2 "ErrrIndctrNotUsedDependingOnApp" 1 "AuxChannelOn" 0 "AuxChannelOff" ;
VAL_ 2561015550 AuxI_O105 3 "NtAvlblTkNoActionDependingOnApp" 2 "ErrrIndctrNotUsedDependingOnApp" 1 "AuxChannelOn" 0 "AuxChannelOff" ;
VAL_ 2561015550 AuxI_O106 3 "NtAvlblTkNoActionDependingOnApp" 2 "ErrrIndctrNotUsedDependingOnApp" 1 "AuxChannelOn" 0 "AuxChannelOff" ;
VAL_ 2561015550 AuxI_O107 3 "NtAvlblTkNoActionDependingOnApp" 2 "ErrrIndctrNotUsedDependingOnApp" 1 "AuxChannelOn" 0 "AuxChannelOff" ;
VAL_ 2561015550 AuxI_O108 3 "NtAvlblTkNoActionDependingOnApp" 2 "ErrrIndctrNotUsedDependingOnApp" 1 "AuxChannelOn" 0 "AuxChannelOff" ;
VAL_ 2561015550 AuxI_O101 2 "ErrrIndctrNotUsedDependingOnApp" 1 "AuxChannelOn" 0 "AuxChannelOff" 3 "NtAvlblTkNoActionDependingOnApp" ;
VAL_ 2561015550 AuxI_O102 3 "NtAvlblTkNoActionDependingOnApp" 2 "ErrrIndctrNotUsedDependingOnApp" 1 "AuxChannelOn" 0 "AuxChannelOff" ;
VAL_ 2561015550 AuxI_O103 3 "NtAvlblTkNoActionDependingOnApp" 2 "ErrrIndctrNotUsedDependingOnApp" 1 "AuxChannelOn" 0 "AuxChannelOff" ;
VAL_ 2561015550 AuxI_O104 3 "NtAvlblTkNoActionDependingOnApp" 2 "ErrrIndctrNotUsedDependingOnApp" 1 "AuxChannelOn" 0 "AuxChannelOff" ;
VAL_ 2561015550 AuxI_O97 3 "NtAvlblTkNoActionDependingOnApp" 2 "ErrrIndctrNotUsedDependingOnApp" 1 "AuxChannelOn" 0 "AuxChannelOff" ;
VAL_ 2561015550 AuxI_O98 3 "NtAvlblTkNoActionDependingOnApp" 2 "ErrrIndctrNotUsedDependingOnApp" 1 "AuxChannelOn" 0 "AuxChannelOff" ;
VAL_ 2561015550 AuxI_O99 3 "NtAvlblTkNoActionDependingOnApp" 2 "ErrrIndctrNotUsedDependingOnApp" 1 "AuxChannelOn" 0 "AuxChannelOff" ;
VAL_ 2561015550 AuxI_O100 3 "NtAvlblTkNoActionDependingOnApp" 2 "ErrrIndctrNotUsedDependingOnApp" 1 "AuxChannelOn" 0 "AuxChannelOff" ;
VAL_ 2561015550 AuxI_O93 3 "NtAvlblTkNoActionDependingOnApp" 2 "ErrrIndctrNotUsedDependingOnApp" 1 "AuxChannelOn" 0 "AuxChannelOff" ;
VAL_ 2561015550 AuxI_O94 3 "NtAvlblTkNoActionDependingOnApp" 2 "ErrrIndctrNotUsedDependingOnApp" 1 "AuxChannelOn" 0 "AuxChannelOff" ;
VAL_ 2561015550 AuxI_O95 3 "NtAvlblTkNoActionDependingOnApp" 2 "ErrrIndctrNotUsedDependingOnApp" 1 "AuxChannelOn" 0 "AuxChannelOff" ;
VAL_ 2561015550 AuxI_O96 3 "NtAvlblTkNoActionDependingOnApp" 2 "ErrrIndctrNotUsedDependingOnApp" 1 "AuxChannelOn" 0 "AuxChannelOff" ;
VAL_ 2561015550 AuxI_O89 3 "NtAvlblTkNoActionDependingOnApp" 2 "ErrrIndctrNotUsedDependingOnApp" 1 "AuxChannelOn" 0 "AuxChannelOff" ;
VAL_ 2561015550 AuxI_O90 3 "NtAvlblTkNoActionDependingOnApp" 2 "ErrrIndctrNotUsedDependingOnApp" 1 "AuxChannelOn" 0 "AuxChannelOff" ;
VAL_ 2561015550 AuxI_O91 3 "NtAvlblTkNoActionDependingOnApp" 2 "ErrrIndctrNotUsedDependingOnApp" 1 "AuxChannelOn" 0 "AuxChannelOff" ;
VAL_ 2566746622 TrailerBrakeStrokeAxle5Right 7 "NotAvailable" 6 "SensorError" 5 "Reserved" 3 "DraggingBrake" 2 "Overstroke" 1 "Nonfunctioning" 0 "OK" ;
VAL_ 2566746622 TrailerBrakeStrokeAxle5Left 7 "NotAvailable" 6 "SensorError" 5 "Reserved" 3 "DraggingBrake" 2 "Overstroke" 1 "Nonfunctioning" 0 "OK" ;
VAL_ 2566746622 TrailerBrakeStrokeAxle4Right 7 "NotAvailable" 6 "SensorError" 5 "Reserved" 3 "DraggingBrake" 2 "Overstroke" 1 "Nonfunctioning" 0 "OK" ;
VAL_ 2566746622 TrailerBrakeStrokeAxle4Left 7 "NotAvailable" 6 "SensorError" 5 "Reserved" 3 "DraggingBrake" 2 "Overstroke" 1 "Nonfunctioning" 0 "OK" ;
VAL_ 2566746622 TrailerBrakeStrokeAxle3Right 7 "NotAvailable" 6 "SensorError" 5 "Reserved" 3 "DraggingBrake" 2 "Overstroke" 1 "Nonfunctioning" 0 "OK" ;
VAL_ 2566746622 TrailerBrakeStrokeAxle3Left 7 "NotAvailable" 6 "SensorError" 5 "Reserved" 3 "DraggingBrake" 2 "Overstroke" 1 "Nonfunctioning" 0 "OK" ;
VAL_ 2566746622 TrailerBrakeStrokeAxle2Right 7 "NotAvailable" 6 "SensorError" 5 "Reserved" 3 "DraggingBrake" 2 "Overstroke" 1 "Nonfunctioning" 0 "OK" ;
VAL_ 2566746622 TrailerBrakeStrokeAxle2Left 7 "NotAvailable" 6 "SensorError" 5 "Reserved" 3 "DraggingBrake" 2 "Overstroke" 1 "Nonfunctioning" 0 "OK" ;
VAL_ 2566746622 TrailerBrakeStrokeAxle1Right 7 "NotAvailable" 6 "SensorError" 5 "Reserved" 3 "DraggingBrake" 2 "Overstroke" 1 "Nonfunctioning" 0 "OK" ;
VAL_ 2566746622 TrailerBrakeStrokeAxle1Left 7 "NotAvailable" 6 "SensorError" 5 "Reserved" 3 "DraggingBrake" 2 "Overstroke" 1 "Nonfunctioning" 0 "OK" ;
VAL_ 2566746622 TractorBrakeStrokeAxle5Right 7 "NotAvailable" 6 "SensorError" 5 "Reserved" 3 "DraggingBrake" 2 "Overstroke" 1 "Nonfunctioning" 0 "OK" ;
VAL_ 2566746622 TractorBrakeStrokeAxle5Left 7 "NotAvailable" 6 "SensorError" 5 "Reserved" 3 "DraggingBrake" 2 "Overstroke" 1 "Nonfunctioning" 0 "OK" ;
VAL_ 2566746622 TractorBrakeStrokeAxle4Right 7 "NotAvailable" 6 "SensorError" 5 "Reserved" 3 "DraggingBrake" 2 "Overstroke" 1 "Nonfunctioning" 0 "OK" ;
VAL_ 2566746622 TractorBrakeStrokeAxle4Left 7 "NotAvailable" 6 "SensorError" 5 "Reserved" 3 "DraggingBrake" 2 "Overstroke" 1 "Nonfunctioning" 0 "OK" ;
VAL_ 2566746622 TractorBrakeStrokeAxle3Right 7 "NotAvailable" 6 "SensorError" 5 "Reserved" 3 "DraggingBrake" 2 "Overstroke" 1 "Nonfunctioning" 0 "OK" ;
VAL_ 2566746622 TractorBrakeStrokeAxle3Left 7 "NotAvailable" 6 "SensorError" 5 "Reserved" 3 "DraggingBrake" 2 "Overstroke" 1 "Nonfunctioning" 0 "OK" ;
VAL_ 2566746622 TractorBrakeStrokeAxle2Right 7 "NotAvailable" 6 "SensorError" 5 "Reserved" 3 "DraggingBrake" 2 "Overstroke" 1 "Nonfunctioning" 0 "OK" ;
VAL_ 2566746622 TractorBrakeStrokeAxle2Left 7 "NotAvailable" 6 "SensorError" 5 "Reserved" 3 "DraggingBrake" 2 "Overstroke" 1 "Nonfunctioning" 0 "OK" ;
VAL_ 2566746622 TractorBrakeStrokeAxle1Right 7 "NotAvailable" 6 "SensorError" 5 "Reserved" 3 "DraggingBrake" 2 "Overstroke" 1 "Nonfunctioning" 0 "OK" ;
VAL_ 2566746622 TractorBrakeStrokeAxle1Left 7 "NotAvailable" 6 "SensorError" 5 "Reserved" 3 "DraggingBrake" 2 "Overstroke" 1 "Nonfunctioning" 0 "OK" ;
VAL_ 2566827774 AirCompressorStatus 3 "NotAvailable" 2 "ErrorIndicator" 1 "CompressorActive" 0 "CompressorNotActive" ;
VAL_ 2566803966 RqedACCDistanceMode 7 "notAvailable" 6 "errorCondition" 5 "notDefined" 4 "RqedACCDistanceMode5" 3 "RqedACCDistanceMode4" 2 "RqedACCDistanceMode3" 1 "RqedACCDistanceMode2" 0 "RqedACCDistanceMode1" ;
VAL_ 2432593918 ACCDistanceAlertSignal 3 "TakeNoAction" 2 "Reserved" 1 "ACCDASActive" 0 "ACCDASNotActive" ;
VAL_ 2432593918 ACCSystemShutoffWarning 3 "TakeNoAction" 2 "Reserved" 1 "ACCSSOWActive" 0 "ACCSSOWNotActive" ;
VAL_ 2432593918 ACCTargetDetected 3 "TakeNoAction" 2 "Reserved" 1 "TargetDetected" 0 "NoTargetsDetected" ;
VAL_ 2432593918 AdptveCruiseCtrlSetDistanceMode 7 "NotAvailable_NotValid" 6 "ErrorCondition" 5 "ConventionalCruiseCtrlMode" 4 "ACCDistanceMode5" 3 "ACCDistanceMode4" 2 "ACCDistanceMode3" 1 "ACCDistanceMode2" 0 "ACCDistanceMode1" ;
VAL_ 2432593918 AdaptiveCruiseCtrlMode 7 "NotAvailable_NotValid" 6 "DsbldErrrCndtnUsdTIndctThtACCIs" 5 "FinishMode" 4 "HldMdUsdTIndctThtACCHsLstThPrvs" 3 "OvertakeMode" 2 "DstncCtrlActvUsdTIndctThtACCIsO" 1 "SpeedCtrlActive" 0 "OffUsdTIndctACCIsEnbldInClbCnfg" ;
VAL_ 2565406462 ControlByte 3 "CannotRespond" 2 "AccessDenied" 1 "NACK" 0 "ACK" ;
VAL_ 2566803198 Status2OfDoors 3 "notAvailable" 2 "error" 1 "atLeast1BusDoorEnabled" 0 "allBusDoorsAreDisabled" ;
VAL_ 2566803198 Ramp_WheelChairLiftPos 3 "NotAvailable" 2 "Error" 1 "OutsideBus" 0 "InsideBus" ;
VAL_ 2566803198 PosOfDoors 15 "NotAvailable" 14 "Error" 3 "1101NotDefined" 2 "AllDoorsClosed" 1 "ClosingLastDoor" 0 "AtLeast1DoorIsOpen" ;
VAL_ 2565870334 FifthWheelRollWarningIndicator 3 "NotAvailable" 2 "error" 1 "LimitExceeded" 0 "LimitNotExceeded" ;
VAL_ 2566762238 FifthWheelSliderLockIndicator 3 "NotAvailable" 2 "Error" 1 "Locked" 0 "NotLocked" ;
VAL_ 2566762238 FfthWhlLckCoupleStatusIndicator 3 "NotAvailable" 2 "Error" 1 "SuccessfulCoupleDetected" 0 "IncmpltBdCplTrckShuldNotBeMoved" ;
VAL_ 2566762238 FfthWhlLckRadyToCoupleIndicator 3 "NotAvailable" 2 "Error" 1 "LockOpenReadyToCouple" 0 "LockNotOpenNotReadyToCouple" ;
VAL_ 2566762238 FifthWheelErrorStatus 15 "NotAvailable" 9 "Kingpin_LockOpen" 8 "KingpinMissingMoreThan5Seconds" 7 "CouplingTimingError" 6 "CouplingSequenceError_Kingpin" 5 "CouplingSequenceError" 14 "NotUsed" 2 "Kingpin_LocksOpenAtStartup" 1 "LocksClosed_NoKingpinAtStartup" 0 "ImproperCouple" ;
VAL_ 2364543998 PitchAndRollCompensated 1 "NotAvailable" 0 "CompensationOn" ;
VAL_ 2364543998 PitchRateFigureOfMerit 1 "NotAvailable" 0 "PtchRtDgrddDtIsSspctDTEnvrnmntl" ;
VAL_ 2364543998 RollAngleFigureOfMerit 1 "NotAvailable" 0 "RllAnglDgrddDtIsSspctDTEnvrnmnt" ;
VAL_ 2364543998 PitchAngleFigureOfMerit 1 "NotAvailable" 0 "PtchAnglDgrddDtIsSspctDTEnvrnmn" ;
VAL_ 2566846718 TransOilLevelMeasurementStatus 15 "NotAvailable" 14 "Error" 13 "ConditionsNotValidOther" 12 "NotDefined" 8 "CndtionsNotValidEngSpeedTooHigh" 7 "CnditionsNotValidEngSpeedTooLow" 6 "CndtionsNotValidVehicleNotLevel" 5 "CndtnsNtVldVhclMvngOtptShftSpdT" 4 "CndtnsNtVldTrnsFluidTempTooHigh" 3 "CndtnsNtVldTransFluidTempTooLow" 2 "ConditionsNotValidTransInGear" 1 "CndtnsNtVldSttlngTmrStllCntngDw" 0 "CndtnsVldFrTrnsOlLvlMeasurement" ;
VAL_ 2566846718 TransOilLevelCountdownTimer 15 "NotAvailable" 14 "Error" 13 "ThirteenMinutes" 12 "TwelveMinutes" 11 "ElevenMinutes" 10 "TenMinutes" 9 "NineMinutes" 8 "EightMinutes" 7 "SevenMinutes" 6 "SixMinutes" 5 "FiveMinutes" 4 "FourMinutes" 3 "ThreeMinutes" 2 "TwoMinutes" 1 "OneMinute" 0 "lessThan1Minute" ;
VAL_ 2566760702 WrlessCommunicationNetworkType2 4 "Satellite network" 3 "Wireless LAN #2" 2 "Wireless LAN #1" 1 "CellularNetwork2" 0 "CellularNetwork1" ;
VAL_ 2566760702 NetworkAntennaStatus2 1 "On" 0 "Off" ;
VAL_ 2566760702 NetworkServiceStatus2 1 "RoamingService" 0 "LocalService" ;
VAL_ 2566760702 NetworkTransceiverStatus2 1 "On" 0 "Off" ;
VAL_ 2566760958 WrlessCommunicationNetworkType1 4 "Satellite network" 1 "CellularNetwork2" 0 "CellularNetwork1" 3 "Wireless LAN #2" 2 "Wireless LAN #1" ;
VAL_ 2566760958 NetworkAntennaStatus1 1 "On" 0 "Off" ;
VAL_ 2566760958 NetworkServiceStatus1 1 "RoamingService" 0 "LocalService" ;
VAL_ 2566760958 NetworkTransceiverStatus1 1 "On" 0 "Off" ;
VAL_ 2633869310 VoltageRegulatorEnabled 3 "NotAvailable" 2 "Error" 1 "RegulatingVoltage" 0 "NtRegulatingVoltageUnitDisabled" ;
VAL_ 2633869310 VoltageRegulatorSoftStartState 3 "NotAvailable" 2 "Error" 1 "SoftStartIsActive" 0 "SoftStartIsInactive" ;
VAL_ 2633869310 VltgRgltrUndrfrqncyCmpnstnEnbld 3 "NotAvailable" 2 "Error" 1 "UndrfrquencyCompensationEnabled" 0 "UndrfrqencyCompensationDisabled" ;
VAL_ 2633869310 VltgRgltrVAr_PwrFctrOprtingMode 7 "NotAvailable" 6 "Error" 5 "Reserved" 2 "VArRegulationEnabled" 1 "PowerFactorRegulationEnabled" 0 "VAr_PwrFactorRegulationDisabled" ;
VAL_ 2633869310 VltgRglatorLoadCompensationMode 7 "NotAvailable" 6 "Error" 5 "Reserved" 2 "IRLineDropCompensationEnabled" 1 "VoltageDroopCompensationEnabled" 0 "LoadCompensationDisabled" ;
